VERSION ""

NS_ :

BS_:

BU_: PFAF_HS LVMPC_HS DCDC_HS AMP_HS VICM2_HS FICM_HS ARS_HS MCP_B_HS MCP_A_HS ICCM_OBD_HS SAS_HS ACCM_HS VLBS_HS EBCM_OBD_HS EDI_HS HPCC_HS VITM_OBD_HS PTAM_HS OBCM_HS VICM_HS HCP_HS FDCM_HS APPS_HS ICCM_HS EOCM_F_HS GPCM_HS FSCM_ITBC_HS SCM_HS ITBC_HS VCM_HS HMIM_HS FCP_HS VES_HS Dummy_HS MCP_C_HS RWS_HS ONSTAR_HS EPS_HS TestTool_HS MCP_HS BCP_HS ALC_HS AHL_AFL_HS SADS_HS EPB_HS FSCM_HS AFS_HS FCM_HS TCCM_HS RDCM_HS PTO_HS PCM_HS EBCM_HS ACC_HS BCM_HS TCM_HS ECM_HS

BO_ 1359 UUDT_Resp_From_RDCM_HS: 8 RDCM_HS
 SG_ DgnInf_HS54F : 7|64@0+ (1,0) [0|1.844674407371E+019] ""  FCP_HS,ONSTAR_HS,TestTool_HS

BO_ 2023 USDT_Req_to_VITM_HS: 8 TestTool_HS
 SG_ DgnInf : 7|64@0+ (1,0) [0|1.844674407371E+019] ""  VITM_OBD_HS

BO_ 2021 USDT_Req_to_OBD_Device5: 8 TestTool_HS
 SG_ DgnInf : 7|64@0+ (1,0) [0|1.844674407371E+019] ""  EBCM_OBD_HS

BO_ 2017 USDT_Req_to_BCP_HS: 8 TestTool_HS
 SG_ DgnInf : 7|64@0+ (1,0) [0|1.844674407371E+019] ""  HCP_HS,BCP_HS

BO_ 2019 USDT_Req_to_FSCM_HS: 8 TestTool_HS
 SG_ DgnInf : 7|64@0+ (1,0) [0|1.844674407371E+019] ""  ICCM_OBD_HS,FSCM_ITBC_HS,FSCM_HS

BO_ 585 USDT_Req_to_AFL_AHL_HS: 8 TestTool_HS
 SG_ DgnInf : 7|64@0+ (1,0) [0|1.844674407371E+019] ""  AHL_AFL_HS

BO_ 578 USDT_Req_to_EHPS_EPS_HS: 8 TestTool_HS
 SG_ DgnInf : 7|64@0+ (1,0) [0|1.844674407371E+019] ""  VES_HS,EPS_HS

BO_ 2022 USDT_Req_to_OBD_Device6: 8 TestTool_HS
 SG_ DgnInf : 7|64@0+ (1,0) [0|1.844674407371E+019] ""  FICM_HS,GPCM_HS,VICM2_HS

BO_ 584 USDT_Req_to_Free_48_HS: 8 TestTool_HS
 SG_ DgnInf : 7|64@0+ (1,0) [0|1.844674407371E+019] ""  Dummy_HS

BO_ 591 USDT_Req_to_RDCM_HS: 8 TestTool_HS
 SG_ DgnInf : 7|64@0+ (1,0) [0|1.844674407371E+019] ""  RDCM_HS

BO_ 581 USDT_Req_to_ALC_HS: 8 TestTool_HS
 SG_ DgnInf : 7|64@0+ (1,0) [0|1.844674407371E+019] ""  ALC_HS

BO_ 586 USDT_Req_to_SAS_HS: 8 TestTool_HS
 SG_ DgnInf : 7|64@0+ (1,0) [0|1.844674407371E+019] ""  SAS_HS

BO_ 588 USDT_Req_to_PFAF_HS: 8 TestTool_HS
 SG_ DgnInf : 7|64@0+ (1,0) [0|1.844674407371E+019] ""  PFAF_HS

BO_ 580 USDT_Req_to_OBCM_HS: 8 TestTool_HS
 SG_ DgnInf : 7|64@0+ (1,0) [0|1.844674407371E+019] ""  DCDC_HS,OBCM_HS

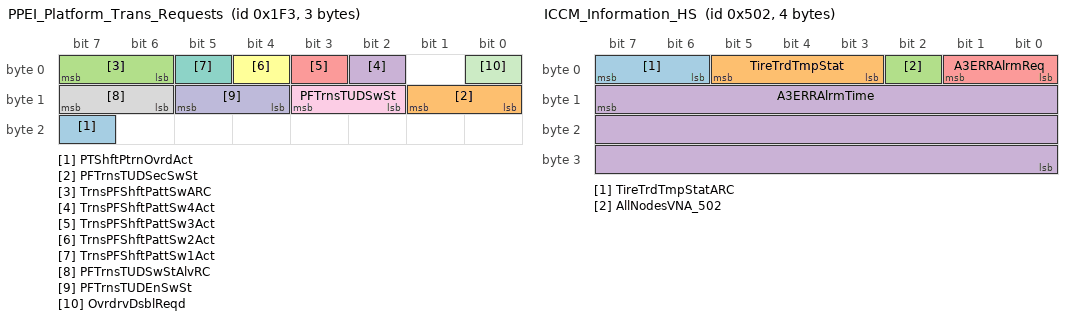
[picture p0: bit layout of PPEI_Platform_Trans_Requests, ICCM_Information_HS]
BO_ 499 PPEI_Platform_Trans_Requests: 3 BCM_HS
 SG_ PTShftPtrnOvrdAct : 23|1@0+ (1,0) [0|1] ""  TCM_HS
 SG_ PFTrnsTUDSecSwSt : 9|2@0+ (1,0) [0|3] ""  TCM_HS
 SG_ TrnsPFShftPattSwARC : 7|2@0+ (1,0) [0|3] ""  PCM_HS,ECM_HS,TCM_HS
 SG_ TrnsPFShftPattSw4Act : 2|1@0+ (1,0) [0|1] ""  PCM_HS,ECM_HS,TCM_HS
 SG_ TrnsPFShftPattSw3Act : 3|1@0+ (1,0) [0|1] ""  PCM_HS,ECM_HS,TCM_HS
 SG_ TrnsPFShftPattSw2Act : 4|1@0+ (1,0) [0|1] ""  PCM_HS,ECM_HS,TCM_HS
 SG_ TrnsPFShftPattSw1Act : 5|1@0+ (1,0) [0|1] ""  PCM_HS,ECM_HS,TCM_HS
 SG_ PFTrnsTUDSwStAlvRC : 15|2@0+ (1,0) [0|3] ""  TCM_HS
 SG_ PFTrnsTUDSwSt : 11|2@0+ (1,0) [0|3] ""  TCM_HS
 SG_ PFTrnsTUDEnSwSt : 13|2@0+ (1,0) [0|3] ""  TCM_HS
 SG_ OvrdrvDsblReqd : 0|1@0+ (1,0) [0|1] "" Vector__XXX

BO_ 1282 ICCM_Information_HS: 4 ALC_HS
 SG_ TireTrdTmpStatARC : 7|2@0+ (1,0) [0|3] ""  EBCM_OBD_HS,EBCM_HS
 SG_ TireTrdTmpStat : 5|3@0+ (1,0) [0|7] ""  BCM_HS,EBCM_OBD_HS,EBCM_HS
 SG_ AllNodesVNA_502 : 2|1@0+ (1,0) [0|1] ""  BCM_HS
 SG_ A3ERRAlrmTime : 15|24@0+ (1,0) [0|16777215] "min"  BCM_HS
 SG_ A3ERRAlrmReq : 1|2@0+ (1,0) [0|3] ""  BCM_HS

BO_ 1360 UUDT_Resp_From_PTAM_HS: 8 PTAM_HS
 SG_ DgnInf_HS550 : 7|64@0+ (1,0) [0|1.844674407371E+019] ""  FCP_HS,ONSTAR_HS,TestTool_HS

BO_ 1616 USDT_Resp_From_PTAM_HS: 8 PTAM_HS
 SG_ DgnInf : 7|64@0+ (1,0) [0|1.844674407371E+019] ""  FCP_HS,ONSTAR_HS,TestTool_HS

BO_ 1921 DTC_Triggered_781: 7 Dummy_HS
 SG_ DTCI_CurrentStatus_781 : 41|1@0+ (1,0) [0|1] ""  HMIM_HS,FCP_HS,ONSTAR_HS
 SG_ DTCI_WrnIndRqdSt_781 : 47|1@0+ (1,0) [0|1] ""  HMIM_HS,FCP_HS,ONSTAR_HS
 SG_ DTCIUnused7_781 : 1|1@0+ (1,0) [0|1] ""  HMIM_HS,FCP_HS,ONSTAR_HS
 SG_ DTCIUnused6_781 : 2|1@0+ (1,0) [0|1] ""  HMIM_HS,FCP_HS,ONSTAR_HS
 SG_ DTCIUnused5_781 : 3|1@0+ (1,0) [0|1] ""  HMIM_HS,FCP_HS,ONSTAR_HS
 SG_ DTCIUnused4_781 : 4|1@0+ (1,0) [0|1] ""  HMIM_HS,FCP_HS,ONSTAR_HS
 SG_ DTCIUnused3_781 : 5|1@0+ (1,0) [0|1] ""  HMIM_HS,FCP_HS,ONSTAR_HS
 SG_ DTCIUnused2_781 : 6|1@0+ (1,0) [0|1] ""  HMIM_HS,FCP_HS,ONSTAR_HS
 SG_ DTCIUnused1_781 : 7|1@0+ (1,0) [0|1] ""  HMIM_HS,FCP_HS,ONSTAR_HS
 SG_ DTCI_TstNPsdPwrUpSt_781 : 45|1@0+ (1,0) [0|1] ""  HMIM_HS,FCP_HS,ONSTAR_HS
 SG_ DTCI_TstNPsdCdClrdSt_781 : 42|1@0+ (1,0) [0|1] ""  HMIM_HS,FCP_HS,ONSTAR_HS
 SG_ DTCI_TstFldPwrUpSt_781 : 46|1@0+ (1,0) [0|1] ""  HMIM_HS,FCP_HS,ONSTAR_HS
 SG_ DTCI_TstFldCdClrdStat_781 : 43|1@0+ (1,0) [0|1] ""  HMIM_HS,FCP_HS,ONSTAR_HS
 SG_ DTCI_HistStat_781 : 44|1@0+ (1,0) [0|1] ""  HMIM_HS,FCP_HS,ONSTAR_HS
 SG_ DTCI_DTCTriggered_781 : 0|1@0+ (1,0) [0|1] ""  HMIM_HS,FCP_HS,ONSTAR_HS
 SG_ DTCI_DTCSource_781 : 15|8@0+ (1,0) [0|255] ""  HMIM_HS,FCP_HS,ONSTAR_HS
 SG_ DTCI_DTCNumber_781 : 23|16@0+ (1,0) [0|65535] ""  HMIM_HS,FCP_HS,ONSTAR_HS
 SG_ DTCI_DTCFaultType_781 : 55|8@0+ (1,0) [0|255] ""  HMIM_HS,FCP_HS,ONSTAR_HS
 SG_ DTCI_DTCFailType_781 : 39|8@0+ (1,0) [0|255] ""  HMIM_HS,FCP_HS,ONSTAR_HS
 SG_ DTCI_CodeSupported_781 : 40|1@0+ (1,0) [0|1] ""  HMIM_HS,FCP_HS,ONSTAR_HS

BO_ 1920 DTC_Triggered_780: 7 EBCM_HS
 SG_ DTCI_CurrentStatus_780 : 41|1@0+ (1,0) [0|1] ""  HMIM_HS,FCP_HS,ONSTAR_HS
 SG_ DTCI_WrnIndRqdSt_780 : 47|1@0+ (1,0) [0|1] ""  HMIM_HS,FCP_HS,ONSTAR_HS
 SG_ DTCIUnused7_780 : 1|1@0+ (1,0) [0|1] ""  HMIM_HS,FCP_HS,ONSTAR_HS
 SG_ DTCIUnused6_780 : 2|1@0+ (1,0) [0|1] ""  HMIM_HS,FCP_HS,ONSTAR_HS
 SG_ DTCIUnused5_780 : 3|1@0+ (1,0) [0|1] ""  HMIM_HS,FCP_HS,ONSTAR_HS
 SG_ DTCIUnused4_780 : 4|1@0+ (1,0) [0|1] ""  HMIM_HS,FCP_HS,ONSTAR_HS
 SG_ DTCIUnused3_780 : 5|1@0+ (1,0) [0|1] ""  HMIM_HS,FCP_HS,ONSTAR_HS
 SG_ DTCIUnused2_780 : 6|1@0+ (1,0) [0|1] ""  HMIM_HS,FCP_HS,ONSTAR_HS
 SG_ DTCIUnused1_780 : 7|1@0+ (1,0) [0|1] ""  HMIM_HS,FCP_HS,ONSTAR_HS
 SG_ DTCI_TstNPsdPwrUpSt_780 : 45|1@0+ (1,0) [0|1] ""  HMIM_HS,FCP_HS,ONSTAR_HS
 SG_ DTCI_TstNPsdCdClrdSt_780 : 42|1@0+ (1,0) [0|1] ""  HMIM_HS,FCP_HS,ONSTAR_HS
 SG_ DTCI_TstFldPwrUpSt_780 : 46|1@0+ (1,0) [0|1] ""  HMIM_HS,FCP_HS,ONSTAR_HS
 SG_ DTCI_TstFldCdClrdStat_780 : 43|1@0+ (1,0) [0|1] ""  HMIM_HS,FCP_HS,ONSTAR_HS
 SG_ DTCI_HistStat_780 : 44|1@0+ (1,0) [0|1] ""  HMIM_HS,FCP_HS,ONSTAR_HS
 SG_ DTCI_DTCTriggered_780 : 0|1@0+ (1,0) [0|1] ""  HMIM_HS,FCP_HS,ONSTAR_HS
 SG_ DTCI_DTCSource_780 : 15|8@0+ (1,0) [0|255] ""  HMIM_HS,FCP_HS,ONSTAR_HS
 SG_ DTCI_DTCNumber_780 : 23|16@0+ (1,0) [0|65535] ""  HMIM_HS,FCP_HS,ONSTAR_HS
 SG_ DTCI_DTCFaultType_780 : 55|8@0+ (1,0) [0|255] ""  HMIM_HS,FCP_HS,ONSTAR_HS
 SG_ DTCI_DTCFailType_780 : 39|8@0+ (1,0) [0|255] ""  HMIM_HS,FCP_HS,ONSTAR_HS
 SG_ DTCI_CodeSupported_780 : 40|1@0+ (1,0) [0|1] ""  HMIM_HS,FCP_HS,ONSTAR_HS

BO_ 596 USDT_Req_to_EPB_HS: 8 TestTool_HS
 SG_ DgnInf : 7|64@0+ (1,0) [0|1.844674407371E+019] ""  EPB_HS

BO_ 2033 PCU_Req_to_SDM_HS: 8 TestTool_HS
 SG_ PCUInfo : 7|64@0+ (1,0) [0|1.844674407371E+019] ""  BCM_HS

BO_ 495 PPEI_Fuel_System_Request_2: 4 ECM_HS
 SG_ MassAirFloV : 7|1@0+ (1,0) [0|1] ""  VICM_HS
 SG_ MassAirFlo : 23|16@0+ (0.01,0) [0|655.35] "grams/s"  VICM_HS

BO_ 1350 UUDT_Resp_From_APPS_HS: 8 APPS_HS
 SG_ DgnInf_HS546 : 7|64@0+ (1,0) [0|1.844674407371E+019] ""  FCP_HS,ONSTAR_HS,TestTool_HS

BO_ 1914 DTC_Triggered_77A: 7 RDCM_HS
 SG_ DTCI_DTCFaultType_77A : 55|8@0+ (1,0) [0|255] ""  HMIM_HS,FCP_HS,ONSTAR_HS
 SG_ DTCI_CodeSupported_77A : 40|1@0+ (1,0) [0|1] ""  HMIM_HS,FCP_HS,ONSTAR_HS
 SG_ DTCI_CurrentStatus_77A : 41|1@0+ (1,0) [0|1] ""  HMIM_HS,FCP_HS,ONSTAR_HS
 SG_ DTCI_TstNPsdCdClrdSt_77A : 42|1@0+ (1,0) [0|1] ""  HMIM_HS,FCP_HS,ONSTAR_HS
 SG_ DTCI_TstFldCdClrdStat_77A : 43|1@0+ (1,0) [0|1] ""  HMIM_HS,FCP_HS,ONSTAR_HS
 SG_ DTCI_HistStat_77A : 44|1@0+ (1,0) [0|1] ""  HMIM_HS,FCP_HS,ONSTAR_HS
 SG_ DTCI_TstNPsdPwrUpSt_77A : 45|1@0+ (1,0) [0|1] ""  HMIM_HS,FCP_HS,ONSTAR_HS
 SG_ DTCI_TstFldPwrUpSt_77A : 46|1@0+ (1,0) [0|1] ""  HMIM_HS,FCP_HS,ONSTAR_HS
 SG_ DTCI_WrnIndRqdSt_77A : 47|1@0+ (1,0) [0|1] ""  HMIM_HS,FCP_HS,ONSTAR_HS
 SG_ DTCI_DTCFailType_77A : 39|8@0+ (1,0) [0|255] ""  HMIM_HS,FCP_HS,ONSTAR_HS
 SG_ DTCI_DTCNumber_77A : 23|16@0+ (1,0) [0|65535] ""  HMIM_HS,FCP_HS,ONSTAR_HS
 SG_ DTCI_DTCSource_77A : 15|8@0+ (1,0) [0|255] ""  HMIM_HS,FCP_HS,ONSTAR_HS
 SG_ DTCI_DTCTriggered_77A : 0|1@0+ (1,0) [0|1] ""  HMIM_HS,FCP_HS,ONSTAR_HS
 SG_ DTCIUnused7_77A : 1|1@0+ (1,0) [0|1] ""  HMIM_HS,FCP_HS,ONSTAR_HS
 SG_ DTCIUnused6_77A : 2|1@0+ (1,0) [0|1] ""  HMIM_HS,FCP_HS,ONSTAR_HS
 SG_ DTCIUnused5_77A : 3|1@0+ (1,0) [0|1] ""  HMIM_HS,FCP_HS,ONSTAR_HS
 SG_ DTCIUnused4_77A : 4|1@0+ (1,0) [0|1] ""  HMIM_HS,FCP_HS,ONSTAR_HS
 SG_ DTCIUnused3_77A : 5|1@0+ (1,0) [0|1] ""  HMIM_HS,FCP_HS,ONSTAR_HS
 SG_ DTCIUnused2_77A : 6|1@0+ (1,0) [0|1] ""  HMIM_HS,FCP_HS,ONSTAR_HS
 SG_ DTCIUnused1_77A : 7|1@0+ (1,0) [0|1] ""  HMIM_HS,FCP_HS,ONSTAR_HS

BO_ 1911 DTC_Triggered_777: 7 PTO_HS
 SG_ DTCI_DTCFaultType_777 : 55|8@0+ (1,0) [0|255] ""  HMIM_HS,FCP_HS,ONSTAR_HS
 SG_ DTCI_CodeSupported_777 : 40|1@0+ (1,0) [0|1] ""  HMIM_HS,FCP_HS,ONSTAR_HS
 SG_ DTCI_CurrentStatus_777 : 41|1@0+ (1,0) [0|1] ""  HMIM_HS,FCP_HS,ONSTAR_HS
 SG_ DTCI_TstNPsdCdClrdSt_777 : 42|1@0+ (1,0) [0|1] ""  HMIM_HS,FCP_HS,ONSTAR_HS
 SG_ DTCI_TstFldCdClrdStat_777 : 43|1@0+ (1,0) [0|1] ""  HMIM_HS,FCP_HS,ONSTAR_HS
 SG_ DTCI_HistStat_777 : 44|1@0+ (1,0) [0|1] ""  HMIM_HS,FCP_HS,ONSTAR_HS
 SG_ DTCI_TstNPsdPwrUpSt_777 : 45|1@0+ (1,0) [0|1] ""  HMIM_HS,FCP_HS,ONSTAR_HS
 SG_ DTCI_TstFldPwrUpSt_777 : 46|1@0+ (1,0) [0|1] ""  HMIM_HS,FCP_HS,ONSTAR_HS
 SG_ DTCI_WrnIndRqdSt_777 : 47|1@0+ (1,0) [0|1] ""  HMIM_HS,FCP_HS,ONSTAR_HS
 SG_ DTCI_DTCFailType_777 : 39|8@0+ (1,0) [0|255] ""  HMIM_HS,FCP_HS,ONSTAR_HS
 SG_ DTCI_DTCNumber_777 : 23|16@0+ (1,0) [0|65535] ""  HMIM_HS,FCP_HS,ONSTAR_HS
 SG_ DTCI_DTCSource_777 : 15|8@0+ (1,0) [0|255] ""  HMIM_HS,FCP_HS,ONSTAR_HS
 SG_ DTCI_DTCTriggered_777 : 0|1@0+ (1,0) [0|1] ""  HMIM_HS,FCP_HS,ONSTAR_HS
 SG_ DTCIUnused7_777 : 1|1@0+ (1,0) [0|1] ""  HMIM_HS,FCP_HS,ONSTAR_HS
 SG_ DTCIUnused6_777 : 2|1@0+ (1,0) [0|1] ""  HMIM_HS,FCP_HS,ONSTAR_HS
 SG_ DTCIUnused5_777 : 3|1@0+ (1,0) [0|1] ""  HMIM_HS,FCP_HS,ONSTAR_HS
 SG_ DTCIUnused4_777 : 4|1@0+ (1,0) [0|1] ""  HMIM_HS,FCP_HS,ONSTAR_HS
 SG_ DTCIUnused3_777 : 5|1@0+ (1,0) [0|1] ""  HMIM_HS,FCP_HS,ONSTAR_HS
 SG_ DTCIUnused2_777 : 6|1@0+ (1,0) [0|1] ""  HMIM_HS,FCP_HS,ONSTAR_HS
 SG_ DTCIUnused1_777 : 7|1@0+ (1,0) [0|1] ""  HMIM_HS,FCP_HS,ONSTAR_HS

BO_ 583 USDT_Req_to_PTO_HS: 8 TestTool_HS
 SG_ DgnInf : 7|64@0+ (1,0) [0|1.844674407371E+019] ""  PTO_HS

BO_ 1351 UUDT_Resp_From_PTO: 8 PTO_HS
 SG_ DgnInf_HS547 : 7|64@0+ (1,0) [0|1.844674407371E+019] ""  FCP_HS,ONSTAR_HS,TestTool_HS

BO_ 1607 USDT_Resp_From_PTO_HS: 8 PTO_HS
 SG_ DgnInf : 7|64@0+ (1,0) [0|1.844674407371E+019] ""  FCP_HS,ONSTAR_HS,TestTool_HS

BO_ 1906 DTC_Triggered_772: 7 ECM_HS
 SG_ DTCI_DTCFaultType_772 : 55|8@0+ (1,0) [0|255] ""  HMIM_HS,FCP_HS,ONSTAR_HS
 SG_ DTCI_CodeSupported_772 : 40|1@0+ (1,0) [0|1] ""  HMIM_HS,FCP_HS,ONSTAR_HS
 SG_ DTCI_CurrentStatus_772 : 41|1@0+ (1,0) [0|1] ""  HMIM_HS,FCP_HS,ONSTAR_HS
 SG_ DTCI_TstNPsdCdClrdSt_772 : 42|1@0+ (1,0) [0|1] ""  HMIM_HS,FCP_HS,ONSTAR_HS
 SG_ DTCI_TstFldCdClrdStat_772 : 43|1@0+ (1,0) [0|1] ""  HMIM_HS,FCP_HS,ONSTAR_HS
 SG_ DTCI_HistStat_772 : 44|1@0+ (1,0) [0|1] ""  HMIM_HS,FCP_HS,ONSTAR_HS
 SG_ DTCI_TstNPsdPwrUpSt_772 : 45|1@0+ (1,0) [0|1] ""  HMIM_HS,FCP_HS,ONSTAR_HS
 SG_ DTCI_TstFldPwrUpSt_772 : 46|1@0+ (1,0) [0|1] ""  HMIM_HS,FCP_HS,ONSTAR_HS
 SG_ DTCI_WrnIndRqdSt_772 : 47|1@0+ (1,0) [0|1] ""  HMIM_HS,FCP_HS,ONSTAR_HS
 SG_ DTCI_DTCFailType_772 : 39|8@0+ (1,0) [0|255] ""  HMIM_HS,FCP_HS,ONSTAR_HS
 SG_ DTCI_DTCNumber_772 : 23|16@0+ (1,0) [0|65535] ""  HMIM_HS,FCP_HS,ONSTAR_HS
 SG_ DTCI_DTCSource_772 : 15|8@0+ (1,0) [0|255] ""  HMIM_HS,FCP_HS,ONSTAR_HS
 SG_ DTCI_DTCTriggered_772 : 0|1@0+ (1,0) [0|1] ""  HMIM_HS,FCP_HS,ONSTAR_HS
 SG_ DTCIUnused7_772 : 1|1@0+ (1,0) [0|1] ""  HMIM_HS,FCP_HS,ONSTAR_HS
 SG_ DTCIUnused6_772 : 2|1@0+ (1,0) [0|1] ""  HMIM_HS,FCP_HS,ONSTAR_HS
 SG_ DTCIUnused5_772 : 3|1@0+ (1,0) [0|1] ""  HMIM_HS,FCP_HS,ONSTAR_HS
 SG_ DTCIUnused4_772 : 4|1@0+ (1,0) [0|1] ""  HMIM_HS,FCP_HS,ONSTAR_HS
 SG_ DTCIUnused3_772 : 5|1@0+ (1,0) [0|1] ""  HMIM_HS,FCP_HS,ONSTAR_HS
 SG_ DTCIUnused2_772 : 6|1@0+ (1,0) [0|1] ""  HMIM_HS,FCP_HS,ONSTAR_HS
 SG_ DTCIUnused1_772 : 7|1@0+ (1,0) [0|1] ""  HMIM_HS,FCP_HS,ONSTAR_HS

BO_ 1907 DTC_Triggered_773: 7 EBCM_HS
 SG_ DTCI_DTCFaultType_773 : 55|8@0+ (1,0) [0|255] ""  HMIM_HS,FCP_HS,ONSTAR_HS
 SG_ DTCI_CodeSupported_773 : 40|1@0+ (1,0) [0|1] ""  HMIM_HS,FCP_HS,ONSTAR_HS
 SG_ DTCI_CurrentStatus_773 : 41|1@0+ (1,0) [0|1] ""  HMIM_HS,FCP_HS,ONSTAR_HS
 SG_ DTCI_TstNPsdCdClrdSt_773 : 42|1@0+ (1,0) [0|1] ""  HMIM_HS,FCP_HS,ONSTAR_HS
 SG_ DTCI_TstFldCdClrdStat_773 : 43|1@0+ (1,0) [0|1] ""  HMIM_HS,FCP_HS,ONSTAR_HS
 SG_ DTCI_HistStat_773 : 44|1@0+ (1,0) [0|1] ""  HMIM_HS,FCP_HS,ONSTAR_HS
 SG_ DTCI_TstNPsdPwrUpSt_773 : 45|1@0+ (1,0) [0|1] ""  HMIM_HS,FCP_HS,ONSTAR_HS
 SG_ DTCI_TstFldPwrUpSt_773 : 46|1@0+ (1,0) [0|1] ""  HMIM_HS,FCP_HS,ONSTAR_HS
 SG_ DTCI_WrnIndRqdSt_773 : 47|1@0+ (1,0) [0|1] ""  HMIM_HS,FCP_HS,ONSTAR_HS
 SG_ DTCI_DTCFailType_773 : 39|8@0+ (1,0) [0|255] ""  HMIM_HS,FCP_HS,ONSTAR_HS
 SG_ DTCI_DTCNumber_773 : 23|16@0+ (1,0) [0|65535] ""  HMIM_HS,FCP_HS,ONSTAR_HS
 SG_ DTCI_DTCSource_773 : 15|8@0+ (1,0) [0|255] ""  HMIM_HS,FCP_HS,ONSTAR_HS
 SG_ DTCI_DTCTriggered_773 : 0|1@0+ (1,0) [0|1] ""  HMIM_HS,FCP_HS,ONSTAR_HS
 SG_ DTCIUnused7_773 : 1|1@0+ (1,0) [0|1] ""  HMIM_HS,FCP_HS,ONSTAR_HS
 SG_ DTCIUnused6_773 : 2|1@0+ (1,0) [0|1] ""  HMIM_HS,FCP_HS,ONSTAR_HS
 SG_ DTCIUnused5_773 : 3|1@0+ (1,0) [0|1] ""  HMIM_HS,FCP_HS,ONSTAR_HS
 SG_ DTCIUnused4_773 : 4|1@0+ (1,0) [0|1] ""  HMIM_HS,FCP_HS,ONSTAR_HS
 SG_ DTCIUnused3_773 : 5|1@0+ (1,0) [0|1] ""  HMIM_HS,FCP_HS,ONSTAR_HS
 SG_ DTCIUnused2_773 : 6|1@0+ (1,0) [0|1] ""  HMIM_HS,FCP_HS,ONSTAR_HS
 SG_ DTCIUnused1_773 : 7|1@0+ (1,0) [0|1] ""  HMIM_HS,FCP_HS,ONSTAR_HS

BO_ 579 USDT_Req_to_EBCM_HPCC_HS: 8 TestTool_HS
 SG_ DgnInf : 7|64@0+ (1,0) [0|1.844674407371E+019] ""  HPCC_HS,EBCM_HS

BO_ 1603 USDT_Resp_From_EBCM_HPCC_HS: 8 EBCM_HS
 SG_ DgnInf : 7|64@0+ (1,0) [0|1.844674407371E+019] ""  FCP_HS,ONSTAR_HS,TestTool_HS

BO_ 1347 UUDT_Resp_From_EBCM_HPCC_HS: 8 EBCM_HS
 SG_ DgnInf_HS543 : 7|64@0+ (1,0) [0|1.844674407371E+019] ""  FCP_HS,ONSTAR_HS,TestTool_HS

BO_ 1915 DTC_Triggered_77B: 7 ACC_HS
 SG_ DTCI_DTCFaultType_77B : 55|8@0+ (1,0) [0|255] ""  HMIM_HS,FCP_HS,ONSTAR_HS
 SG_ DTCI_CodeSupported_77B : 40|1@0+ (1,0) [0|1] ""  HMIM_HS,FCP_HS,ONSTAR_HS
 SG_ DTCI_CurrentStatus_77B : 41|1@0+ (1,0) [0|1] ""  HMIM_HS,FCP_HS,ONSTAR_HS
 SG_ DTCI_TstNPsdCdClrdSt_77B : 42|1@0+ (1,0) [0|1] ""  HMIM_HS,FCP_HS,ONSTAR_HS
 SG_ DTCI_TstFldCdClrdStat_77B : 43|1@0+ (1,0) [0|1] ""  HMIM_HS,FCP_HS,ONSTAR_HS
 SG_ DTCI_HistStat_77B : 44|1@0+ (1,0) [0|1] ""  HMIM_HS,FCP_HS,ONSTAR_HS
 SG_ DTCI_TstNPsdPwrUpSt_77B : 45|1@0+ (1,0) [0|1] ""  HMIM_HS,FCP_HS,ONSTAR_HS
 SG_ DTCI_TstFldPwrUpSt_77B : 46|1@0+ (1,0) [0|1] ""  HMIM_HS,FCP_HS,ONSTAR_HS
 SG_ DTCI_WrnIndRqdSt_77B : 47|1@0+ (1,0) [0|1] ""  HMIM_HS,FCP_HS,ONSTAR_HS
 SG_ DTCI_DTCFailType_77B : 39|8@0+ (1,0) [0|255] ""  HMIM_HS,FCP_HS,ONSTAR_HS
 SG_ DTCI_DTCNumber_77B : 23|16@0+ (1,0) [0|65535] ""  HMIM_HS,FCP_HS,ONSTAR_HS
 SG_ DTCI_DTCSource_77B : 15|8@0+ (1,0) [0|255] ""  HMIM_HS,FCP_HS,ONSTAR_HS
 SG_ DTCI_DTCTriggered_77B : 0|1@0+ (1,0) [0|1] ""  HMIM_HS,FCP_HS,ONSTAR_HS
 SG_ DTCIUnused7_77B : 1|1@0+ (1,0) [0|1] ""  HMIM_HS,FCP_HS,ONSTAR_HS
 SG_ DTCIUnused6_77B : 2|1@0+ (1,0) [0|1] ""  HMIM_HS,FCP_HS,ONSTAR_HS
 SG_ DTCIUnused5_77B : 3|1@0+ (1,0) [0|1] ""  HMIM_HS,FCP_HS,ONSTAR_HS
 SG_ DTCIUnused4_77B : 4|1@0+ (1,0) [0|1] ""  HMIM_HS,FCP_HS,ONSTAR_HS
 SG_ DTCIUnused3_77B : 5|1@0+ (1,0) [0|1] ""  HMIM_HS,FCP_HS,ONSTAR_HS
 SG_ DTCIUnused2_77B : 6|1@0+ (1,0) [0|1] ""  HMIM_HS,FCP_HS,ONSTAR_HS
 SG_ DTCIUnused1_77B : 7|1@0+ (1,0) [0|1] ""  HMIM_HS,FCP_HS,ONSTAR_HS

BO_ 587 USDT_Req_to_EOCM_FCM_HS: 8 TestTool_HS
 SG_ DgnInf : 7|64@0+ (1,0) [0|1.844674407371E+019] ""  EOCM_F_HS,FCM_HS

BO_ 1611 USDT_Resp_From_EOCM_FCM_HS: 8 FCM_HS
 SG_ DgnInf : 7|64@0+ (1,0) [0|1.844674407371E+019] ""  FCP_HS,ONSTAR_HS,TestTool_HS

BO_ 1355 UUDT_Resp_From_EOCM_FCM_HS: 8 FCM_HS
 SG_ DgnInf_HS54B : 7|64@0+ (1,0) [0|1.844674407371E+019] ""  FCP_HS,ONSTAR_HS,TestTool_HS

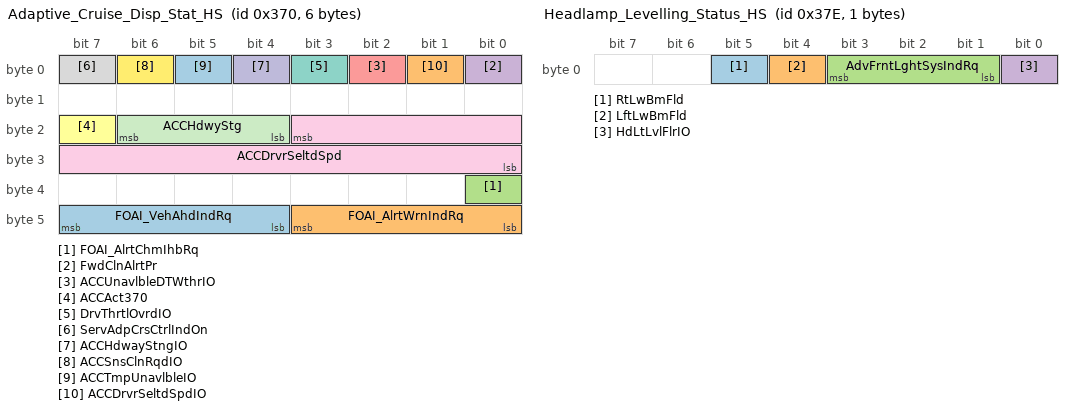
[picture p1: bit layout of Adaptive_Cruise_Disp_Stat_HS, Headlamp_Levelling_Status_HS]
BO_ 880 Adaptive_Cruise_Disp_Stat_HS: 6 ACC_HS
 SG_ FOAI_VehAhdIndRq : 47|4@0+ (1,0) [0|15] ""  BCM_HS
 SG_ FOAI_AlrtWrnIndRq : 43|4@0+ (1,0) [0|15] ""  BCM_HS
 SG_ FOAI_AlrtChmIhbRq : 32|1@0+ (1,0) [0|1] ""  BCM_HS
 SG_ FwdClnAlrtPr : 0|1@0+ (1,0) [0|1] ""  BCM_HS
 SG_ ACCUnavlbleDTWthrIO : 2|1@0+ (1,0) [0|1] ""  BCM_HS
 SG_ ACCAct370 : 23|1@0+ (1,0) [0|1] ""  EBCM_OBD_HS,EBCM_HS,TCM_HS,BCM_HS
 SG_ DrvThrtlOvrdIO : 3|1@0+ (1,0) [0|1] ""  BCM_HS
 SG_ ServAdpCrsCtrlIndOn : 7|1@0+ (1,0) [0|1] ""  BCM_HS
 SG_ ACCDrvrSeltdSpd : 19|12@0+ (0.0625,0) [0|255.9375] "km / h"  ECM_HS,BCM_HS
 SG_ ACCHdwayStngIO : 4|1@0+ (1,0) [0|1] ""  BCM_HS
 SG_ ACCHdwyStg : 22|3@0+ (1,0) [0|7] ""  BCM_HS
 SG_ ACCSnsClnRqdIO : 6|1@0+ (1,0) [0|1] ""  BCM_HS
 SG_ ACCTmpUnavlbleIO : 5|1@0+ (1,0) [0|1] ""  BCM_HS
 SG_ ACCDrvrSeltdSpdIO : 1|1@0+ (1,0) [0|1] ""  BCM_HS

BO_ 894 Headlamp_Levelling_Status_HS: 1 AHL_AFL_HS
 SG_ RtLwBmFld : 5|1@0+ (1,0) [0|1] ""  EOCM_F_HS,BCM_HS
 SG_ LftLwBmFld : 4|1@0+ (1,0) [0|1] ""  EOCM_F_HS,BCM_HS
 SG_ AdvFrntLghtSysIndRq : 3|3@0+ (1,0) [0|7] ""  BCM_HS
 SG_ HdLtLvlFlrIO : 0|1@0+ (1,0) [0|1] ""  BCM_HS

BO_ 577 USDT_Req_to_BCM_HS: 8 TestTool_HS
 SG_ DgnInf : 7|64@0+ (1,0) [0|1.844674407371E+019] ""  BCM_HS

BO_ 298 Body_Information_HS: 8 BCM_HS
 SG_ SpdLmtrSttngTyp : 59|2@0+ (1,0) [0|3] ""  ECM_HS
 SG_ TCSysDisSwAtv : 62|1@0+ (1,0) [0|1] ""  ECM_HS
 SG_ AutoMdSpdLmtCnfrmd : 57|1@0+ (1,0) [0|1] ""  ECM_HS
 SG_ TCSysDisSwAtvARC : 61|2@0+ (1,0) [0|3] ""  ECM_HS,EBCM_OBD_HS,EBCM_HS
 SG_ ChmAct : 55|1@0+ (1,0) [0|1] ""  ACC_HS
 SG_ DDAjrSwAtvM : 63|1@0+ (1,0) [0|1] ""  EBCM_OBD_HS,EBCM_HS,ECM_HS,ACC_HS
 SG_ CrshAlrtDrvrSlctdType : 5|1@0+ (1,0) [0|1] ""  EBCM_OBD_HS,EBCM_HS,ACC_HS
 SG_ PsSbltAtcV : 54|1@0+ (1,0) [0|1] ""  EBCM_OBD_HS,EBCM_HS
 SG_ PsSbltAtc : 53|1@0+ (1,0) [0|1] ""  EBCM_OBD_HS,EBCM_HS
 SG_ TrlrBrkDsplyAct : 51|1@0+ (1,0) [0|1] ""  FSCM_ITBC_HS
 SG_ RdSpdCatType : 45|2@0+ (1,0) [0|3] ""  FCM_HS,AHL_AFL_HS
 SG_ LnCat : 47|2@0+ (1,0) [0|3] ""  FCM_HS,AHL_AFL_HS
 SG_ FncRdClass : 50|3@0+ (1,0) [0|7] ""  FCM_HS,AHL_AFL_HS
 SG_ SprtLnRd : 43|1@0+ (1,0) [0|1] ""  FCM_HS,AHL_AFL_HS
 SG_ CntrldAccRd : 39|1@0+ (1,0) [0|1] ""  FCM_HS,AHL_AFL_HS
 SG_ BldUpArDet : 11|1@0+ (1,0) [0|1] ""  FCM_HS,AHL_AFL_HS
 SG_ MpDataAvlbl : 3|1@0+ (1,0) [0|1] ""  FCM_HS,AHL_AFL_HS
 SG_ SusCustStngReq : 42|3@0+ (1,0) [0|7] ""  EBCM_OBD_HS,EBCM_HS
 SG_ StrCustStngReq : 38|3@0+ (1,0) [0|7] ""  EBCM_OBD_HS,EBCM_HS
 SG_ RstrCustFctrDef : 35|1@0+ (1,0) [0|1] ""  AHL_AFL_HS,EBCM_OBD_HS,EBCM_HS
 SG_ DrvlnCustStngReq : 34|3@0+ (1,0) [0|7] ""  EBCM_OBD_HS,EBCM_HS
 SG_ ChmMstrVDA : 22|1@0+ (1,0) [0|1] ""  EOCM_F_HS,ACC_HS
 SG_ IPCVDA : 21|1@0+ (1,0) [0|1] ""  EOCM_F_HS,ACC_HS,EBCM_OBD_HS,EBCM_HS
 SG_ HeadUpDispVDA : 20|1@0+ (1,0) [0|1] ""  EOCM_F_HS,ACC_HS
 SG_ HapticSeatVDA : 52|1@0+ (1,0) [0|1] ""  ACC_HS
 SG_ RRDoorAjarSwAct : 23|1@0+ (1,0) [0|1] ""  ICCM_OBD_HS,ICCM_HS,ALC_HS,EPB_HS,SADS_HS
 SG_ PDAjrSwAtv : 10|1@0+ (1,0) [0|1] ""  EPB_HS,ICCM_OBD_HS,ICCM_HS,ALC_HS,SADS_HS
 SG_ DDAjrSwAtv : 9|1@0+ (1,0) [0|1] ""  ECM_HS,EBCM_OBD_HS,EBCM_HS,ACC_HS,EPB_HS,ICCM_OBD_HS,ICCM_HS,ALC_HS,SADS_HS
 SG_ TrlrHWIntrfcVDA : 4|1@0+ (1,0) [0|1] ""  EBCM_OBD_HS,EBCM_HS,RDCM_HS
 SG_ DrId : 15|3@0+ (1,0) [0|7] ""  ACC_HS
 SG_ EnrgMgtLdShdRq : 19|4@0+ (1,0) [0|15] ""  PTO_HS,ARS_HS,ICCM_OBD_HS,ICCM_HS,ALC_HS,SADS_HS
 SG_ DrSbltAtcV : 2|1@0+ (1,0) [0|1] ""  ECM_HS,ACC_HS,EPB_HS,EBCM_OBD_HS,EBCM_HS
 SG_ TrlrHtchSwAtv : 0|1@0+ (1,0) [0|1] ""  EBCM_OBD_HS,EBCM_HS,RDCM_HS
 SG_ TreInfMonSysRstReq : 7|1@0+ (1,0) [0|1] ""  EBCM_OBD_HS,EBCM_HS
 SG_ HUDActv : 6|1@0+ (1,0) [0|1] ""  ACC_HS
 SG_ BatVltV : 1|1@0+ (1,0) [0|1] ""  LVMPC_HS,EDI_HS,TCM_HS,HCP_HS,BCP_HS,MCP_C_HS,MCP_B_HS,MCP_A_HS,ECM_HS,EPB_HS,ICCM_OBD_HS,ICCM_HS,ALC_HS,SADS_HS
 SG_ BatVlt : 31|8@0+ (0.1,3) [3|28.5] "volts"  LVMPC_HS,EDI_HS,TCM_HS,HCP_HS,BCP_HS,MCP_C_HS,MCP_B_HS,MCP_A_HS,ECM_HS,EPB_HS,ICCM_OBD_HS,ICCM_HS,ALC_HS,SADS_HS
 SG_ RLDoorAjarSwAct : 8|1@0+ (1,0) [0|1] ""  ICCM_OBD_HS,ICCM_HS,ALC_HS,EPB_HS,SADS_HS
 SG_ DrSbltAtc : 12|1@0+ (1,0) [0|1] ""  ECM_HS,ACC_HS,EPB_HS,EBCM_OBD_HS,EBCM_HS

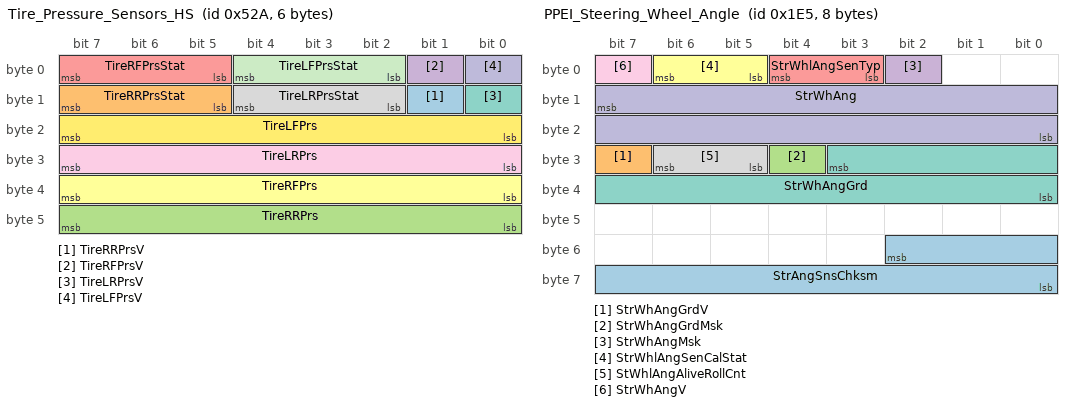
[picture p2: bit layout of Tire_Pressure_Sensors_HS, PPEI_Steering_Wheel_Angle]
BO_ 1322 Tire_Pressure_Sensors_HS: 6 BCM_HS
 SG_ TireRRPrsV : 9|1@0+ (1,0) [0|1] ""  LVMPC_HS,EDI_HS,ICCM_OBD_HS,ICCM_HS,RDCM_HS,EBCM_OBD_HS,EBCM_HS
 SG_ TireRRPrsStat : 15|3@0+ (1,0) [0|7] ""  LVMPC_HS,EDI_HS,ICCM_OBD_HS,ICCM_HS,RDCM_HS,EBCM_OBD_HS,EBCM_HS
 SG_ TireRRPrs : 47|8@0+ (4,0) [0|1020] "kPaG"  LVMPC_HS,EDI_HS,ICCM_OBD_HS,ICCM_HS,RDCM_HS,EBCM_OBD_HS,EBCM_HS
 SG_ TireRFPrsV : 1|1@0+ (1,0) [0|1] ""  LVMPC_HS,EDI_HS,ICCM_OBD_HS,ICCM_HS,RDCM_HS,EBCM_OBD_HS,EBCM_HS
 SG_ TireRFPrsStat : 7|3@0+ (1,0) [0|7] ""  LVMPC_HS,EDI_HS,ICCM_OBD_HS,ICCM_HS,RDCM_HS,EBCM_OBD_HS,EBCM_HS
 SG_ TireRFPrs : 39|8@0+ (4,0) [0|1020] "kPaG"  LVMPC_HS,EDI_HS,ICCM_OBD_HS,ICCM_HS,RDCM_HS,EBCM_OBD_HS,EBCM_HS
 SG_ TireLRPrsV : 8|1@0+ (1,0) [0|1] ""  LVMPC_HS,EDI_HS,ICCM_OBD_HS,ICCM_HS,RDCM_HS,EBCM_OBD_HS,EBCM_HS
 SG_ TireLRPrsStat : 12|3@0+ (1,0) [0|7] ""  LVMPC_HS,EDI_HS,ICCM_OBD_HS,ICCM_HS,RDCM_HS,EBCM_OBD_HS,EBCM_HS
 SG_ TireLRPrs : 31|8@0+ (4,0) [0|1020] "kPaG"  LVMPC_HS,EDI_HS,ICCM_OBD_HS,ICCM_HS,RDCM_HS,EBCM_OBD_HS,EBCM_HS
 SG_ TireLFPrsV : 0|1@0+ (1,0) [0|1] ""  LVMPC_HS,EDI_HS,ICCM_OBD_HS,ICCM_HS,RDCM_HS,EBCM_OBD_HS,EBCM_HS
 SG_ TireLFPrsStat : 4|3@0+ (1,0) [0|7] ""  LVMPC_HS,EDI_HS,ICCM_OBD_HS,ICCM_HS,RDCM_HS,EBCM_OBD_HS,EBCM_HS
 SG_ TireLFPrs : 23|8@0+ (4,0) [0|1020] "kPaG"  LVMPC_HS,EDI_HS,ICCM_OBD_HS,ICCM_HS,RDCM_HS,EBCM_OBD_HS,EBCM_HS

BO_ 1601 USDT_Resp_From_BCM_HS: 8 BCM_HS
 SG_ DgnInf : 7|64@0+ (1,0) [0|1.844674407371E+019] ""  FCP_HS,ONSTAR_HS,TestTool_HS

BO_ 2018 USDT_Req_to_TCM_MTA_MTIO_HS: 8 TestTool_HS
 SG_ DgnInf : 7|64@0+ (1,0) [0|1.844674407371E+019] ""  TCM_HS

BO_ 2026 USDT_Resp_From_TCM_MTA_MTIO_HS: 8 TCM_HS
 SG_ DgnInf : 7|64@0+ (1,0) [0|1.844674407371E+019] ""  FCP_HS,ONSTAR_HS,TestTool_HS

BO_ 1514 UUDT_Resp_From_TCM_MTA_MTIO_HS: 8 TCM_HS
 SG_ DgnInf : 7|64@0+ (1,0) [0|1.844674407371E+019] ""  FCP_HS,ONSTAR_HS,TestTool_HS

BO_ 1300 VIN_Digits_2_to_9_HS: 8 BCM_HS
 SG_ VehIdNmDig2_9 : 7|64@0+ (1,0) [0|1] ""  EBCM_OBD_HS,EBCM_HS,VES_HS,EPS_HS,VLBS_HS,ACC_HS,TCCM_HS,EPB_HS,AFS_HS,RDCM_HS

BO_ 288 Vehicle_Odometer_HS: 5 BCM_HS
 SG_ VehOdo : 7|32@0+ (0.015625,0) [0|67108863.984375] "km"  LVMPC_HS,TCCM_HS,ACC_HS,AFS_HS
 SG_ VehOdoV : 32|1@0+ (1,0) [0|1] ""  LVMPC_HS,TCCM_HS,ACC_HS,AFS_HS

BO_ 2020 USDT_Req_to_VICM_HS: 8 TestTool_HS
 SG_ DgnInf : 7|64@0+ (1,0) [0|1.844674407371E+019] ""  VICM_HS

BO_ 2028 USDT_Resp_From_VICM_HS: 8 VICM_HS
 SG_ DgnInf : 7|64@0+ (1,0) [0|1.844674407371E+019] ""  FCP_HS,ONSTAR_HS,TestTool_HS

BO_ 1516 UUDT_Resp_From_VICM_HS: 8 VICM_HS
 SG_ DgnInf : 7|64@0+ (1,0) [0|1.844674407371E+019] ""  FCP_HS,ONSTAR_HS,TestTool_HS

BO_ 485 PPEI_Steering_Wheel_Angle: 8 EBCM_HS
 SG_ StrAngSnsChksm : 50|11@0+ (1,0) [0|2047] ""  FCM_HS,HMIM_HS,VES_HS,EPS_HS,EBCM_OBD_HS,EBCM_HS,EPB_HS
 SG_ StrWhAngGrdV : 31|1@0+ (1,0) [0|1] ""  FCM_HS,HMIM_HS,ACC_HS,FCP_HS,ONSTAR_HS,ICCM_OBD_HS,ICCM_HS,ALC_HS,SADS_HS,ECM_HS,VES_HS,EPS_HS,EPB_HS,RDCM_HS,TCCM_HS,EBCM_OBD_HS,EBCM_HS
 SG_ StrWhAngGrdMsk : 28|1@0+ (1,0) [0|1] ""  FCM_HS,VES_HS,EPS_HS,HMIM_HS,EPB_HS,EBCM_OBD_HS,EBCM_HS
 SG_ StrWhAngMsk : 2|1@0+ (1,0) [0|1] ""  LVMPC_HS,EDI_HS,FCM_HS,HMIM_HS,ICCM_OBD_HS,ICCM_HS,ALC_HS,SADS_HS,VES_HS,EPS_HS,EPB_HS,RDCM_HS,EBCM_OBD_HS,EBCM_HS
 SG_ StrWhlAngSenTyp : 4|2@0+ (1,0) [0|3] ""  EBCM_OBD_HS,EBCM_HS,VES_HS,EPS_HS,HMIM_HS,EPB_HS
 SG_ StrWhlAngSenCalStat : 6|2@0+ (1,0) [0|3] ""  EBCM_OBD_HS,EBCM_HS,HMIM_HS,FCM_HS,ICCM_OBD_HS,ICCM_HS,ALC_HS,SADS_HS,VES_HS,EPS_HS,AHL_AFL_HS,EPB_HS,RDCM_HS,ACC_HS,BCM_HS,TCCM_HS
 SG_ StrWhAngGrd : 27|12@0- (1,0) [-2048|2047] "deg/sec"  FCM_HS,EBCM_OBD_HS,EBCM_HS,HMIM_HS,ACC_HS,PCM_HS,ECM_HS,TCCM_HS,RDCM_HS,ICCM_OBD_HS,ICCM_HS,ALC_HS,SADS_HS,VES_HS,EPS_HS,EPB_HS,FCP_HS,ONSTAR_HS
 SG_ StWhlAngAliveRollCnt : 30|2@0+ (1,0) [0|3] ""  HMIM_HS,EBCM_OBD_HS,EBCM_HS,ICCM_OBD_HS,ICCM_HS,ALC_HS,SADS_HS,VES_HS,EPS_HS,RDCM_HS,EPB_HS
 SG_ StrWhAngV : 7|1@0+ (1,0) [0|1] ""  LVMPC_HS,EDI_HS,HMIM_HS,FCM_HS,EBCM_OBD_HS,EBCM_HS,ICCM_OBD_HS,ICCM_HS,ALC_HS,SADS_HS,VES_HS,EPS_HS,RDCM_HS,FCP_HS,ONSTAR_HS,ACC_HS,BCM_HS,AHL_AFL_HS,EPB_HS,TCCM_HS
 SG_ StrWhAng : 15|16@0- (0.0625,0) [-2048|2047.9375] "deg"  LVMPC_HS,EDI_HS,HMIM_HS,FCM_HS,EBCM_OBD_HS,EBCM_HS,ICCM_OBD_HS,ICCM_HS,ALC_HS,SADS_HS,VES_HS,EPS_HS,RDCM_HS,EPB_HS,FCP_HS,ONSTAR_HS,ACC_HS,AHL_AFL_HS,BCM_HS,TCCM_HS

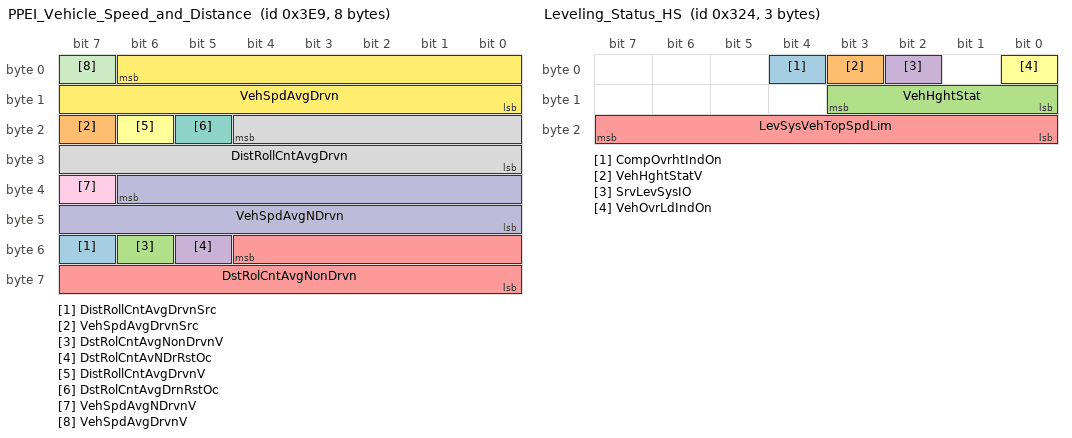
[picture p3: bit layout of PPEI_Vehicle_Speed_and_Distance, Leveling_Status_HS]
BO_ 1001 PPEI_Vehicle_Speed_and_Distance: 8 ECM_HS
 SG_ DistRollCntAvgDrvnSrc : 55|1@0+ (1,0) [0|1] ""  HCP_HS,BCP_HS,HMIM_HS,EBCM_OBD_HS,EBCM_HS,VES_HS,EPS_HS,VICM_HS,TCM_HS,TCCM_HS,BCM_HS
 SG_ VehSpdAvgDrvnSrc : 23|1@0+ (1,0) [0|1] ""  PTO_HS,FICM_HS,EBCM_OBD_HS,EBCM_HS,HMIM_HS,TCM_HS,ARS_HS,VES_HS,EPS_HS,TCCM_HS,EPB_HS,BCM_HS
 SG_ DstRolCntAvgNonDrvnV : 54|1@0+ (1,0) [0|1] ""  VICM_HS,HMIM_HS,EBCM_OBD_HS,EBCM_HS,VES_HS,EPS_HS,TCCM_HS,BCM_HS
 SG_ DstRolCntAvNDrRstOc : 53|1@0+ (1,0) [0|1] ""  VICM_HS,HMIM_HS,EBCM_OBD_HS,EBCM_HS,VES_HS,EPS_HS,TCCM_HS,BCM_HS
 SG_ DstRolCntAvgNonDrvn : 52|13@0+ (0.125,0) [0|1023.875] "m"  VICM_HS,HMIM_HS,EBCM_OBD_HS,EBCM_HS,VES_HS,EPS_HS,TCCM_HS,BCM_HS
 SG_ DistRollCntAvgDrvnV : 22|1@0+ (1,0) [0|1] ""  HCP_HS,BCP_HS,HMIM_HS,EBCM_OBD_HS,EBCM_HS,VES_HS,EPS_HS,VICM_HS,TCM_HS,TCCM_HS,ICCM_OBD_HS,ICCM_HS,FSCM_ITBC_HS,FSCM_HS,BCM_HS
 SG_ DstRolCntAvgDrnRstOc : 21|1@0+ (1,0) [0|1] ""  HCP_HS,BCP_HS,HMIM_HS,EBCM_OBD_HS,EBCM_HS,VES_HS,EPS_HS,VICM_HS,TCM_HS,TCCM_HS,ICCM_OBD_HS,ICCM_HS,FSCM_ITBC_HS,FSCM_HS,BCM_HS
 SG_ DistRollCntAvgDrvn : 20|13@0+ (0.125,0) [0|1023.875] "m"  HCP_HS,BCP_HS,HMIM_HS,EBCM_OBD_HS,EBCM_HS,VES_HS,EPS_HS,VICM_HS,TCM_HS,TCCM_HS,ICCM_OBD_HS,ICCM_HS,FSCM_ITBC_HS,FSCM_HS,BCM_HS
 SG_ VehSpdAvgNDrvnV : 39|1@0+ (1,0) [0|1] ""  VICM2_HS,VLBS_HS,HMIM_HS,FCP_HS,ONSTAR_HS,VES_HS,EPS_HS,VICM_HS,ICCM_OBD_HS,ICCM_HS,EBCM_OBD_HS,EBCM_HS,APPS_HS,TCCM_HS,BCP_HS,EPB_HS,AHL_AFL_HS,BCM_HS,ACC_HS,PTO_HS
 SG_ VehSpdAvgNDrvn : 38|15@0+ (0.015625,0) [0|511.984375] "km / h"  VICM2_HS,VLBS_HS,HMIM_HS,FCP_HS,ONSTAR_HS,VES_HS,EPS_HS,VICM_HS,ICCM_OBD_HS,ICCM_HS,EBCM_OBD_HS,EBCM_HS,APPS_HS,BCP_HS,TCCM_HS,EPB_HS,AHL_AFL_HS,BCM_HS,ACC_HS,PTO_HS
 SG_ VehSpdAvgDrvnV : 7|1@0+ (1,0) [0|1] ""  PFAF_HS,LVMPC_HS,EDI_HS,VLBS_HS,FICM_HS,EBCM_OBD_HS,EBCM_HS,HMIM_HS,TCM_HS,ARS_HS,BCP_HS,ONSTAR_HS,VES_HS,EPS_HS,VICM_HS,APPS_HS,TCCM_HS,FCP_HS,VICM2_HS,FSCM_ITBC_HS,FSCM_HS,EPB_HS,ICCM_OBD_HS,ICCM_HS,ALC_HS,SADS_HS,ACC_HS,BCM_HS,PTO_HS
 SG_ VehSpdAvgDrvn : 6|15@0+ (0.015625,0) [0|511.984375] "km / h"  PFAF_HS,LVMPC_HS,EDI_HS,VLBS_HS,FICM_HS,EBCM_OBD_HS,EBCM_HS,HMIM_HS,TCM_HS,ARS_HS,BCP_HS,ONSTAR_HS,VES_HS,EPS_HS,VICM_HS,APPS_HS,TCCM_HS,VICM2_HS,FSCM_ITBC_HS,FSCM_HS,EPB_HS,ICCM_OBD_HS,ICCM_HS,ALC_HS,SADS_HS,FCP_HS,ACC_HS,BCM_HS,PTO_HS

BO_ 961 PPEI_Powertrain_Immobilizer_Data: 8 ECM_HS
 SG_ PTImmblzerInfo : 7|64@0+ (1,0) [0|1.844674407371E+019] ""  PCM_HS,ECM_HS,VLBS_HS,FCP_HS,ONSTAR_HS,BCM_HS

BO_ 804 Leveling_Status_HS: 3 SADS_HS
 SG_ CompOvrhtIndOn : 4|1@0+ (1,0) [0|1] ""  BCM_HS
 SG_ VehHghtStatV : 3|1@0+ (1,0) [0|1] ""  BCM_HS,EBCM_OBD_HS,EBCM_HS
 SG_ VehHghtStat : 11|4@0+ (1,0) [0|15] ""  BCM_HS,EBCM_OBD_HS,EBCM_HS
 SG_ SrvLevSysIO : 2|1@0+ (1,0) [0|1] ""  BCM_HS,FCP_HS,ONSTAR_HS
 SG_ LevSysVehTopSpdLim : 23|8@0+ (2,0) [0|510] "km/h"  BCM_HS
 SG_ VehOvrLdIndOn : 0|1@0+ (1,0) [0|1] ""  FCP_HS,ONSTAR_HS,BCM_HS

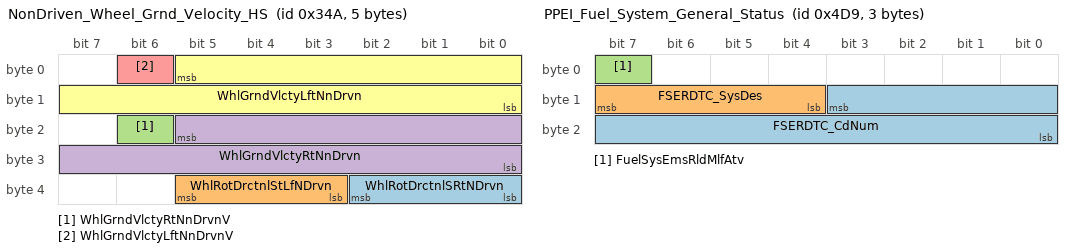
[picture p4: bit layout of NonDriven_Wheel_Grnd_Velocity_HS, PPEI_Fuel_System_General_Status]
BO_ 842 NonDriven_Wheel_Grnd_Velocity_HS: 5 EBCM_HS
 SG_ WhlRotDrctnlSRtNDrvn : 34|3@0+ (1,0) [0|7] ""  VICM_HS,EDI_HS,EOCM_F_HS,HMIM_HS
 SG_ WhlRotDrctnlStLfNDrvn : 37|3@0+ (1,0) [0|7] ""  VICM_HS,EDI_HS,EOCM_F_HS,HMIM_HS
 SG_ WhlGrndVlctyRtNnDrvnV : 22|1@0+ (1,0) [0|1] ""  EDI_HS,HMIM_HS,TCCM_HS,FCM_HS,APPS_HS,EOCM_F_HS,EPB_HS,RDCM_HS,ACC_HS,BCM_HS,AFS_HS,VES_HS,EPS_HS,SADS_HS
 SG_ WhlGrndVlctyRtNnDrvn : 21|14@0+ (0.03125,0) [0|511.96875] "km / h"  EDI_HS,HMIM_HS,TCCM_HS,FCM_HS,APPS_HS,EOCM_F_HS,RDCM_HS,ACC_HS,BCM_HS,EPB_HS,AFS_HS,VES_HS,EPS_HS,SADS_HS
 SG_ WhlGrndVlctyLftNnDrvnV : 6|1@0+ (1,0) [0|1] ""  EDI_HS,HMIM_HS,TCCM_HS,FCM_HS,APPS_HS,EOCM_F_HS,EPB_HS,BCM_HS,RDCM_HS,ACC_HS,AFS_HS,VES_HS,EPS_HS,SADS_HS
 SG_ WhlGrndVlctyLftNnDrvn : 5|14@0+ (0.03125,0) [0|511.96875] "km / h"  EDI_HS,HMIM_HS,TCCM_HS,FCM_HS,APPS_HS,EOCM_F_HS,BCM_HS,RDCM_HS,ACC_HS,EPB_HS,VES_HS,EPS_HS,AFS_HS,SADS_HS

BO_ 1241 PPEI_Fuel_System_General_Status: 3 FSCM_HS
 SG_ FSERDTC_CdNum : 11|12@0+ (1,0) [0|4095] ""  PCM_HS,ECM_HS
 SG_ FSERDTC_SysDes : 15|4@0+ (1,0) [0|15] ""  PCM_HS,ECM_HS
 SG_ FuelSysEmsRldMlfAtv : 7|1@0+ (1,0) [0|1] ""  PCM_HS,ECM_HS

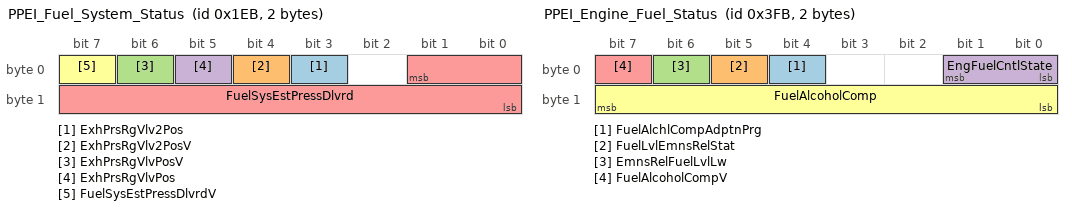
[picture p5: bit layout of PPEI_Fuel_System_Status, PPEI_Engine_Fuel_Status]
BO_ 491 PPEI_Fuel_System_Status: 2 FSCM_HS
 SG_ ExhPrsRgVlv2Pos : 3|1@0+ (1,0) [0|1] ""  ECM_HS
 SG_ ExhPrsRgVlv2PosV : 4|1@0+ (1,0) [0|1] ""  ECM_HS
 SG_ ExhPrsRgVlvPosV : 6|1@0+ (1,0) [0|1] ""  PCM_HS,ECM_HS
 SG_ ExhPrsRgVlvPos : 5|1@0+ (1,0) [0|1] ""  PCM_HS,ECM_HS
 SG_ FuelSysEstPressDlvrd : 1|10@0+ (1,0) [0|1023] "kPa"  VCM_HS,PCM_HS,ECM_HS
 SG_ FuelSysEstPressDlvrdV : 7|1@0+ (1,0) [0|1] ""  VCM_HS,PCM_HS,ECM_HS

BO_ 1019 PPEI_Engine_Fuel_Status: 2 ECM_HS
 SG_ FuelAlchlCompAdptnPrg : 4|1@0+ (1,0) [0|1] ""  BCM_HS
 SG_ FuelLvlEmnsRelStat : 5|1@0+ (1,0) [0|1] ""  FICM_HS,BCP_HS
 SG_ EmnsRelFuelLvlLw : 6|1@0+ (1,0) [0|1] ""  FICM_HS,BCP_HS,ICCM_OBD_HS,ICCM_HS,FSCM_ITBC_HS,FSCM_HS
 SG_ EngFuelCntlState : 1|2@0+ (1,0) [0|3] ""  FICM_HS,ICCM_OBD_HS,ICCM_HS,FSCM_ITBC_HS,FSCM_HS
 SG_ FuelAlcoholCompV : 7|1@0+ (1,0) [0|1] ""  FICM_HS,VICM_HS,FCP_HS,ONSTAR_HS,BCM_HS,ICCM_OBD_HS,ICCM_HS,FSCM_ITBC_HS,FSCM_HS
 SG_ FuelAlcoholComp : 15|8@0+ (0.392157,0) [0|100.000035] "%"  FICM_HS,VICM_HS,FCP_HS,ONSTAR_HS,BCM_HS,ICCM_OBD_HS,ICCM_HS,FSCM_ITBC_HS,FSCM_HS

BO_TX_BU_ 2023 : FCP_HS,ONSTAR_HS,TestTool_HS;
BO_TX_BU_ 2021 : FCP_HS,ONSTAR_HS,TestTool_HS;
BO_TX_BU_ 2017 : FCP_HS,ONSTAR_HS,TestTool_HS;
BO_TX_BU_ 2019 : FCP_HS,ONSTAR_HS,TestTool_HS;
BO_TX_BU_ 585 : FCP_HS,ONSTAR_HS,TestTool_HS;
BO_TX_BU_ 578 : FCP_HS,ONSTAR_HS,TestTool_HS;
BO_TX_BU_ 2022 : FCP_HS,ONSTAR_HS,TestTool_HS;
BO_TX_BU_ 584 : FCP_HS,ONSTAR_HS,TestTool_HS;
BO_TX_BU_ 591 : FCP_HS,ONSTAR_HS,TestTool_HS;
BO_TX_BU_ 581 : FCP_HS,ONSTAR_HS,TestTool_HS;
BO_TX_BU_ 586 : FCP_HS,ONSTAR_HS,TestTool_HS;
BO_TX_BU_ 588 : FCP_HS,ONSTAR_HS,TestTool_HS;
BO_TX_BU_ 580 : FCP_HS,ONSTAR_HS,TestTool_HS;
BO_TX_BU_ 1282 : ICCM_OBD_HS,ICCM_HS,ALC_HS;
BO_TX_BU_ 1920 : EBCM_OBD_HS,EBCM_HS;
BO_TX_BU_ 596 : FCP_HS,ONSTAR_HS,TestTool_HS;
BO_TX_BU_ 495 : PCM_HS,ECM_HS;
BO_TX_BU_ 1914 : TCCM_HS,RDCM_HS;
BO_TX_BU_ 583 : FCP_HS,ONSTAR_HS,TestTool_HS;
BO_TX_BU_ 1906 : PCM_HS,ECM_HS;
BO_TX_BU_ 1907 : EBCM_OBD_HS,EBCM_HS;
BO_TX_BU_ 579 : FCP_HS,ONSTAR_HS,TestTool_HS;
BO_TX_BU_ 1603 : HPCC_HS,EBCM_HS;
BO_TX_BU_ 1347 : HPCC_HS,EBCM_HS;
BO_TX_BU_ 1915 : FCM_HS,ACC_HS;
BO_TX_BU_ 587 : FCP_HS,ONSTAR_HS,TestTool_HS;
BO_TX_BU_ 1611 : EOCM_F_HS,FCM_HS;
BO_TX_BU_ 1355 : EOCM_F_HS,FCM_HS;
BO_TX_BU_ 880 : EOCM_F_HS,ACC_HS;
BO_TX_BU_ 577 : FCP_HS,ONSTAR_HS,TestTool_HS;
BO_TX_BU_ 2018 : FCP_HS,ONSTAR_HS,TestTool_HS;
BO_TX_BU_ 2020 : FCP_HS,ONSTAR_HS,TestTool_HS;
BO_TX_BU_ 485 : SAS_HS,EBCM_OBD_HS,EPS_HS,EBCM_HS;
BO_TX_BU_ 961 : HCP_HS,PCM_HS,ECM_HS;
BO_TX_BU_ 804 : ICCM_OBD_HS,ICCM_HS,ALC_HS,SADS_HS;
BO_TX_BU_ 842 : EBCM_OBD_HS,EBCM_HS;
BO_TX_BU_ 1241 : ICCM_OBD_HS,ICCM_HS,FSCM_ITBC_HS,FSCM_HS;
BO_TX_BU_ 491 : ICCM_OBD_HS,ICCM_HS,FSCM_ITBC_HS,FSCM_HS;
BO_TX_BU_ 1019 : PCM_HS,ECM_HS;
CM_ SG_ 499 PFTrnsTUDSecSwSt "Added 2006 Nov 10 according to CR1112";
CM_ BO_ 1282 "ALC will not (and cannot) be present on vehicles where the ICCM will transmit HS $502. Currently, this is only envisioned for high-performance vehicles.";
CM_ SG_ 1921 DTCI_DTCSource_781 "This shall be equal to the Diagnostic Address of the transmittting device.";
CM_ SG_ 1921 DTCI_DTCFaultType_781 "Based on Powertrain definition.  Not expected to be supported by all devices.";
CM_ SG_ 1921 DTCI_DTCFailType_781 "Assigned per GMW3110, Appendix E";
CM_ SG_ 1920 DTCI_DTCSource_780 "This shall be equal to the Diagnostic Address of the transmittting device.";
CM_ SG_ 1920 DTCI_DTCFaultType_780 "Based on Powertrain definition.  Not expected to be supported by all devices.";
CM_ SG_ 1920 DTCI_DTCFailType_780 "Assigned per GMW3110, Appendix E";
CM_ SG_ 1914 DTCI_DTCFaultType_77A "Based on Powertrain definition.  Not expected to be supported by all devices.";
CM_ SG_ 1914 DTCI_DTCFailType_77A "Assigned per GMW3110, Appendix E";
CM_ SG_ 1914 DTCI_DTCSource_77A "This shall be equal to the Diagnostic Address of the transmittting device.";
CM_ SG_ 1911 DTCI_DTCFaultType_777 "Based on Powertrain definition.  Not expected to be supported by all devices.";
CM_ SG_ 1911 DTCI_DTCFailType_777 "Assigned per GMW3110, Appendix E";
CM_ SG_ 1911 DTCI_DTCSource_777 "This shall be equal to the Diagnostic Address of the transmittting device.";
CM_ SG_ 1906 DTCI_DTCFaultType_772 "Based on Powertrain definition.  Not expected to be supported by all devices.";
CM_ SG_ 1906 DTCI_DTCFailType_772 "Assigned per GMW3110, Appendix E";
CM_ SG_ 1906 DTCI_DTCSource_772 "This shall be equal to the Diagnostic Address of the transmittting device.";
CM_ SG_ 1907 DTCI_DTCFaultType_773 "Based on Powertrain definition.  Not expected to be supported by all devices.";
CM_ SG_ 1907 DTCI_DTCFailType_773 "Assigned per GMW3110, Appendix E";
CM_ SG_ 1907 DTCI_DTCSource_773 "This shall be equal to the Diagnostic Address of the transmittting device.";
CM_ SG_ 1915 DTCI_DTCFaultType_77B "Based on Powertrain definition.  Not expected to be supported by all devices.";
CM_ SG_ 1915 DTCI_DTCFailType_77B "Assigned per GMW3110, Appendix E";
CM_ SG_ 1915 DTCI_DTCSource_77B "This shall be equal to the Diagnostic Address of the transmittting device.";
CM_ BO_ 880 "Note that the ACC algorithm will transmit this message at a 50 ms periodic rate and the EOCM algorithm will transmit this message at a 40 ms periodic rate";
CM_ SG_ 880 ACCHdwyStg "Headway is the  time which results from dividing the following distance (or gap) between vehicles by the vehicle speed.  This setting allows the driver to choose a Headway Setting without actually knowing the value of this time.";
CM_ SG_ 298 DrId "Driver 8 changed to Unknown on 3/30/99";
CM_ SG_ 1300 VehIdNmDig2_9 "Desc: 8 ASCII Characters";
CM_ BO_ 485 "6443-Power Steering Indication On in this frame not used by GlobalA /JD";
CM_ BO_ 491 "Changed for PPEI 3.6 - Should be gated from FSCM";
BA_DEF_ SG_  "VNSigSLHS_VNReq" ENUM  "No","Yes";
BA_DEF_ SG_  "VNSigSLHSSharedDiagnostic" ENUM  "No","Yes";
BA_DEF_ SG_  "SignalType" STRING ;
BA_DEF_ SG_  "PacketOrder" INT 0 65535;
BA_DEF_ SG_  "SignalLongName" STRING ;
BA_DEF_ SG_  "GenSigStartValue" INT 0 65535;
BA_DEF_ SG_  "VNSigAllNodes" ENUM  "No","Yes";
BA_DEF_ SG_  "GenSigDeltaValue" INT 0 0;
BA_DEF_ SG_  "GenSigSendType" ENUM  "not used","not used","not used","not used","not used","not used","not used","NoSigSendType","not used","not used","OnAnyChange","OnChangeIfActive","OnDelta";
BA_DEF_ SG_  "GenSigSendOnInit" ENUM  "Not Initialized","Application","Handler";
BA_DEF_ BO_  "AppGenMsgCycleTime" INT 0 0;
BA_DEF_ BO_  "GenMsgILSupport" ENUM  "No","Yes";
BA_DEF_ BO_  "TpApplType" STRING ;
BA_DEF_ BO_  "Prio" INT 0 7;
BA_DEF_ BO_  "MessageSubnet" ENUM  "LS","MS","HS","CE","PE","HV","FO";
BA_DEF_ BO_  "DiagState" ENUM  "No","Yes";
BA_DEF_ BO_  "GenMsgDelayTime" INT 0 100000;
BA_DEF_ BO_  "GenMsgCycleTime" INT 0 100000;
BA_DEF_ BO_  "GenMsgSendType" ENUM  "cyclicX","spontanX","cyclicIfActiveX","spontanWithDelay","cyclicAndSpontanX","cyclicAndSpontanWithDelay","spontanWithRepitition","cyclicIfActiveAndSpontanWD";
BA_DEF_ BO_  "DiagResponse" ENUM  "No","Yes";
BA_DEF_ BO_  "DiagRequest" ENUM  "No","Yes";
BA_DEF_ BO_  "NmMessage" ENUM  "No","Yes";
BA_DEF_REL_ BU_SG_REL_  "GenSigSuprvRespComment" STRING ;
BA_DEF_REL_ BU_SG_REL_  "GenSigVBitResp" ENUM  "No","Yes";
BA_DEF_REL_ BU_SG_REL_  "GenSigVBitRespComment" STRING ;
BA_DEF_REL_ BU_SG_REL_  "GenSigVDAFailComment" STRING ;
BA_DEF_REL_ BU_SG_REL_  "GenSigVDAFailResp" ENUM  "No","Yes";
BA_DEF_REL_ BU_SG_REL_  "GenSigRxStartValue" STRING ;
BA_DEF_REL_ BU_SG_REL_  "GenSigSuprvRespSubValue" INT 0 65535;
BA_DEF_REL_ BU_SG_REL_  "GenSigSuprvResp" ENUM  "None","Notify App","Substitute Default";
BA_DEF_REL_ BU_SG_REL_  "GenSigTimeoutMsg" HEX -2147483648 268435455;
BA_DEF_REL_ BU_SG_REL_  "GenSigTimeoutTime" INT 0 15000;
BA_DEF_DEF_  "VNSigSLHS_VNReq" "No";
BA_DEF_DEF_  "VNSigSLHSSharedDiagnostic" "No";
BA_DEF_DEF_  "SignalType" "";
BA_DEF_DEF_  "PacketOrder" 0;
BA_DEF_DEF_  "SignalLongName" "";
BA_DEF_DEF_  "GenSigStartValue" 0;
BA_DEF_DEF_  "VNSigAllNodes" "No";
BA_DEF_DEF_  "GenSigDeltaValue" 0;
BA_DEF_DEF_  "GenSigSendType" "NoSigSendType";
BA_DEF_DEF_  "GenSigSendOnInit" "Not Initialized";
BA_DEF_DEF_  "AppGenMsgCycleTime" 0;
BA_DEF_DEF_  "GenMsgILSupport" "Yes";
BA_DEF_DEF_  "TpApplType" "";
BA_DEF_DEF_  "Prio" 4;
BA_DEF_DEF_  "MessageSubnet" "FO";
BA_DEF_DEF_  "DiagState" "No";
BA_DEF_DEF_  "GenMsgDelayTime" 0;
BA_DEF_DEF_  "GenMsgCycleTime" 0;
BA_DEF_DEF_  "GenMsgSendType" "spontanX";
BA_DEF_DEF_  "DiagResponse" "No";
BA_DEF_DEF_  "DiagRequest" "No";
BA_DEF_DEF_  "NmMessage" "No";
BA_DEF_DEF_REL_ "GenSigSuprvRespComment" "";
BA_DEF_DEF_REL_ "GenSigVBitResp" "No";
BA_DEF_DEF_REL_ "GenSigVBitRespComment" "";
BA_DEF_DEF_REL_ "GenSigVDAFailComment" "";
BA_DEF_DEF_REL_ "GenSigVDAFailResp" "No";
BA_DEF_DEF_REL_ "GenSigRxStartValue" "";
BA_DEF_DEF_REL_ "GenSigSuprvRespSubValue" 0;
BA_DEF_DEF_REL_ "GenSigSuprvResp" "None";
BA_DEF_DEF_REL_ "GenSigTimeoutMsg" 0;
BA_DEF_DEF_REL_ "GenSigTimeoutTime" 0;
BA_ "GenMsgILSupport" BO_ 1359 0;
BA_ "TpApplType" BO_ 1359 "DiagUUDTResponse";
BA_ "Prio" BO_ 1359 0;
BA_ "MessageSubnet" BO_ 1359 2;
BA_ "Prio" BO_ 2023 0;
BA_ "MessageSubnet" BO_ 2023 2;
BA_ "DiagRequest" BO_ 2023 1;
BA_ "Prio" BO_ 2021 0;
BA_ "MessageSubnet" BO_ 2021 2;
BA_ "DiagRequest" BO_ 2021 1;
BA_ "Prio" BO_ 2017 0;
BA_ "MessageSubnet" BO_ 2017 2;
BA_ "DiagRequest" BO_ 2017 1;
BA_ "Prio" BO_ 2019 0;
BA_ "MessageSubnet" BO_ 2019 2;
BA_ "DiagRequest" BO_ 2019 1;
BA_ "Prio" BO_ 585 0;
BA_ "MessageSubnet" BO_ 585 2;
BA_ "DiagRequest" BO_ 585 1;
BA_ "Prio" BO_ 578 0;
BA_ "MessageSubnet" BO_ 578 2;
BA_ "DiagRequest" BO_ 578 1;
BA_ "Prio" BO_ 2022 0;
BA_ "MessageSubnet" BO_ 2022 2;
BA_ "DiagRequest" BO_ 2022 1;
BA_ "Prio" BO_ 584 0;
BA_ "MessageSubnet" BO_ 584 2;
BA_ "DiagRequest" BO_ 584 1;
BA_ "Prio" BO_ 591 0;
BA_ "MessageSubnet" BO_ 591 2;
BA_ "DiagRequest" BO_ 591 1;
BA_ "Prio" BO_ 581 0;
BA_ "MessageSubnet" BO_ 581 2;
BA_ "DiagRequest" BO_ 581 1;
BA_ "Prio" BO_ 586 0;
BA_ "MessageSubnet" BO_ 586 2;
BA_ "DiagRequest" BO_ 586 1;
BA_ "GenMsgILSupport" BO_ 588 0;
BA_ "Prio" BO_ 588 0;
BA_ "MessageSubnet" BO_ 588 2;
BA_ "DiagRequest" BO_ 588 1;
BA_ "Prio" BO_ 580 0;
BA_ "MessageSubnet" BO_ 580 2;
BA_ "DiagRequest" BO_ 580 1;
BA_ "Prio" BO_ 499 0;
BA_ "MessageSubnet" BO_ 499 2;
BA_ "GenMsgCycleTime" BO_ 499 30;
BA_ "GenMsgSendType" BO_ 499 0;
BA_ "Prio" BO_ 1282 0;
BA_ "MessageSubnet" BO_ 1282 2;
BA_ "GenMsgCycleTime" BO_ 1282 500;
BA_ "GenMsgSendType" BO_ 1282 0;
BA_ "GenMsgILSupport" BO_ 1360 0;
BA_ "TpApplType" BO_ 1360 "DiagUUDTResponse";
BA_ "Prio" BO_ 1360 0;
BA_ "MessageSubnet" BO_ 1360 2;
BA_ "Prio" BO_ 1616 0;
BA_ "MessageSubnet" BO_ 1616 2;
BA_ "DiagResponse" BO_ 1616 1;
BA_ "Prio" BO_ 1921 0;
BA_ "MessageSubnet" BO_ 1921 2;
BA_ "GenMsgCycleTime" BO_ 1921 1000;
BA_ "GenMsgSendType" BO_ 1921 0;
BA_ "Prio" BO_ 1920 0;
BA_ "MessageSubnet" BO_ 1920 2;
BA_ "GenMsgCycleTime" BO_ 1920 1000;
BA_ "GenMsgSendType" BO_ 1920 0;
BA_ "Prio" BO_ 596 0;
BA_ "MessageSubnet" BO_ 596 2;
BA_ "DiagRequest" BO_ 596 1;
BA_ "Prio" BO_ 2033 0;
BA_ "MessageSubnet" BO_ 2033 2;
BA_ "Prio" BO_ 495 0;
BA_ "MessageSubnet" BO_ 495 2;
BA_ "GenMsgCycleTime" BO_ 495 12;
BA_ "GenMsgSendType" BO_ 495 0;
BA_ "GenMsgILSupport" BO_ 1350 0;
BA_ "TpApplType" BO_ 1350 "DiagUUDTResponse";
BA_ "Prio" BO_ 1350 0;
BA_ "MessageSubnet" BO_ 1350 2;
BA_ "Prio" BO_ 1914 6;
BA_ "MessageSubnet" BO_ 1914 2;
BA_ "GenMsgCycleTime" BO_ 1914 1000;
BA_ "GenMsgSendType" BO_ 1914 0;
BA_ "Prio" BO_ 1911 6;
BA_ "MessageSubnet" BO_ 1911 2;
BA_ "GenMsgCycleTime" BO_ 1911 1000;
BA_ "GenMsgSendType" BO_ 1911 0;
BA_ "Prio" BO_ 583 0;
BA_ "MessageSubnet" BO_ 583 2;
BA_ "DiagRequest" BO_ 583 1;
BA_ "GenMsgILSupport" BO_ 1351 0;
BA_ "TpApplType" BO_ 1351 "DiagUUDTResponse";
BA_ "Prio" BO_ 1351 0;
BA_ "MessageSubnet" BO_ 1351 2;
BA_ "Prio" BO_ 1607 0;
BA_ "MessageSubnet" BO_ 1607 2;
BA_ "DiagResponse" BO_ 1607 1;
BA_ "Prio" BO_ 1906 6;
BA_ "MessageSubnet" BO_ 1906 2;
BA_ "GenMsgCycleTime" BO_ 1906 1000;
BA_ "GenMsgSendType" BO_ 1906 0;
BA_ "Prio" BO_ 1907 6;
BA_ "MessageSubnet" BO_ 1907 2;
BA_ "GenMsgCycleTime" BO_ 1907 1000;
BA_ "GenMsgSendType" BO_ 1907 0;
BA_ "Prio" BO_ 579 0;
BA_ "MessageSubnet" BO_ 579 2;
BA_ "DiagRequest" BO_ 579 1;
BA_ "Prio" BO_ 1603 0;
BA_ "MessageSubnet" BO_ 1603 2;
BA_ "DiagResponse" BO_ 1603 1;
BA_ "GenMsgILSupport" BO_ 1347 0;
BA_ "TpApplType" BO_ 1347 "DiagUUDTResponse";
BA_ "Prio" BO_ 1347 0;
BA_ "MessageSubnet" BO_ 1347 2;
BA_ "Prio" BO_ 1915 6;
BA_ "MessageSubnet" BO_ 1915 2;
BA_ "GenMsgCycleTime" BO_ 1915 1000;
BA_ "GenMsgSendType" BO_ 1915 0;
BA_ "GenMsgILSupport" BO_ 587 0;
BA_ "Prio" BO_ 587 0;
BA_ "MessageSubnet" BO_ 587 2;
BA_ "DiagRequest" BO_ 587 1;
BA_ "GenMsgILSupport" BO_ 1611 0;
BA_ "Prio" BO_ 1611 0;
BA_ "MessageSubnet" BO_ 1611 2;
BA_ "DiagResponse" BO_ 1611 1;
BA_ "GenMsgILSupport" BO_ 1355 0;
BA_ "TpApplType" BO_ 1355 "DiagUUDTResponse";
BA_ "Prio" BO_ 1355 0;
BA_ "MessageSubnet" BO_ 1355 2;
BA_ "AppGenMsgCycleTime" BO_ 880 40;
BA_ "Prio" BO_ 880 0;
BA_ "MessageSubnet" BO_ 880 2;
BA_ "Prio" BO_ 894 0;
BA_ "MessageSubnet" BO_ 894 2;
BA_ "GenMsgCycleTime" BO_ 894 1500;
BA_ "GenMsgSendType" BO_ 894 0;
BA_ "Prio" BO_ 577 0;
BA_ "MessageSubnet" BO_ 577 2;
BA_ "DiagRequest" BO_ 577 1;
BA_ "Prio" BO_ 298 0;
BA_ "MessageSubnet" BO_ 298 2;
BA_ "GenMsgCycleTime" BO_ 298 100;
BA_ "GenMsgSendType" BO_ 298 0;
BA_ "Prio" BO_ 1322 0;
BA_ "MessageSubnet" BO_ 1322 2;
BA_ "GenMsgCycleTime" BO_ 1322 1000;
BA_ "GenMsgSendType" BO_ 1322 0;
BA_ "Prio" BO_ 1601 0;
BA_ "MessageSubnet" BO_ 1601 2;
BA_ "DiagResponse" BO_ 1601 1;
BA_ "Prio" BO_ 2018 0;
BA_ "MessageSubnet" BO_ 2018 2;
BA_ "DiagRequest" BO_ 2018 1;
BA_ "Prio" BO_ 2026 0;
BA_ "MessageSubnet" BO_ 2026 2;
BA_ "DiagResponse" BO_ 2026 1;
BA_ "GenMsgILSupport" BO_ 1514 0;
BA_ "TpApplType" BO_ 1514 "DiagUUDTResponse";
BA_ "Prio" BO_ 1514 0;
BA_ "MessageSubnet" BO_ 1514 2;
BA_ "Prio" BO_ 1300 0;
BA_ "MessageSubnet" BO_ 1300 2;
BA_ "GenMsgCycleTime" BO_ 1300 1000;
BA_ "GenMsgSendType" BO_ 1300 0;
BA_ "Prio" BO_ 288 0;
BA_ "MessageSubnet" BO_ 288 2;
BA_ "GenMsgCycleTime" BO_ 288 5000;
BA_ "GenMsgSendType" BO_ 288 0;
BA_ "Prio" BO_ 2020 0;
BA_ "MessageSubnet" BO_ 2020 2;
BA_ "DiagRequest" BO_ 2020 1;
BA_ "Prio" BO_ 2028 0;
BA_ "MessageSubnet" BO_ 2028 2;
BA_ "DiagResponse" BO_ 2028 1;
BA_ "GenMsgILSupport" BO_ 1516 0;
BA_ "TpApplType" BO_ 1516 "DiagUUDTResponse";
BA_ "Prio" BO_ 1516 0;
BA_ "MessageSubnet" BO_ 1516 2;
BA_ "Prio" BO_ 485 0;
BA_ "MessageSubnet" BO_ 485 2;
BA_ "GenMsgCycleTime" BO_ 485 10;
BA_ "GenMsgSendType" BO_ 485 0;
BA_ "Prio" BO_ 1001 0;
BA_ "MessageSubnet" BO_ 1001 2;
BA_ "GenMsgCycleTime" BO_ 1001 100;
BA_ "GenMsgSendType" BO_ 1001 0;
BA_ "Prio" BO_ 961 0;
BA_ "MessageSubnet" BO_ 961 2;
BA_ "GenMsgCycleTime" BO_ 961 100;
BA_ "GenMsgSendType" BO_ 961 0;
BA_ "Prio" BO_ 804 0;
BA_ "MessageSubnet" BO_ 804 2;
BA_ "GenMsgCycleTime" BO_ 804 500;
BA_ "GenMsgSendType" BO_ 804 0;
BA_ "Prio" BO_ 842 0;
BA_ "MessageSubnet" BO_ 842 2;
BA_ "GenMsgCycleTime" BO_ 842 50;
BA_ "GenMsgSendType" BO_ 842 0;
BA_ "Prio" BO_ 1241 0;
BA_ "MessageSubnet" BO_ 1241 2;
BA_ "GenMsgCycleTime" BO_ 1241 500;
BA_ "GenMsgSendType" BO_ 1241 0;
BA_ "Prio" BO_ 491 0;
BA_ "MessageSubnet" BO_ 491 2;
BA_ "GenMsgCycleTime" BO_ 491 12;
BA_ "GenMsgSendType" BO_ 491 0;
BA_ "Prio" BO_ 1019 0;
BA_ "MessageSubnet" BO_ 1019 2;
BA_ "GenMsgCycleTime" BO_ 1019 250;
BA_ "GenMsgSendType" BO_ 1019 0;
BA_ "VNSigSLHSSharedDiagnostic" SG_ 1359 DgnInf_HS54F 1;
BA_ "SignalType" SG_ 1359 DgnInf_HS54F "UNM";
BA_ "SignalLongName" SG_ 1359 DgnInf_HS54F "Diagnostic Information HS54F";
BA_ "VNSigAllNodes" SG_ 1359 DgnInf_HS54F 1;
BA_ "VNSigSLHSSharedDiagnostic" SG_ 2023 DgnInf 1;
BA_ "SignalType" SG_ 2023 DgnInf "UNM";
BA_ "SignalLongName" SG_ 2023 DgnInf "Diagnostic Information";
BA_ "VNSigAllNodes" SG_ 2023 DgnInf 1;
BA_ "VNSigSLHSSharedDiagnostic" SG_ 2021 DgnInf 1;
BA_ "SignalType" SG_ 2021 DgnInf "UNM";
BA_ "SignalLongName" SG_ 2021 DgnInf "Diagnostic Information";
BA_ "VNSigAllNodes" SG_ 2021 DgnInf 1;
BA_ "VNSigSLHSSharedDiagnostic" SG_ 2017 DgnInf 1;
BA_ "SignalType" SG_ 2017 DgnInf "UNM";
BA_ "SignalLongName" SG_ 2017 DgnInf "Diagnostic Information";
BA_ "VNSigAllNodes" SG_ 2017 DgnInf 1;
BA_ "VNSigSLHSSharedDiagnostic" SG_ 2019 DgnInf 1;
BA_ "SignalType" SG_ 2019 DgnInf "UNM";
BA_ "SignalLongName" SG_ 2019 DgnInf "Diagnostic Information";
BA_ "VNSigAllNodes" SG_ 2019 DgnInf 1;
BA_ "VNSigSLHSSharedDiagnostic" SG_ 585 DgnInf 1;
BA_ "SignalType" SG_ 585 DgnInf "UNM";
BA_ "SignalLongName" SG_ 585 DgnInf "Diagnostic Information";
BA_ "VNSigAllNodes" SG_ 585 DgnInf 1;
BA_ "VNSigSLHSSharedDiagnostic" SG_ 578 DgnInf 1;
BA_ "SignalType" SG_ 578 DgnInf "UNM";
BA_ "SignalLongName" SG_ 578 DgnInf "Diagnostic Information";
BA_ "VNSigAllNodes" SG_ 578 DgnInf 1;
BA_ "VNSigSLHSSharedDiagnostic" SG_ 2022 DgnInf 1;
BA_ "SignalType" SG_ 2022 DgnInf "UNM";
BA_ "SignalLongName" SG_ 2022 DgnInf "Diagnostic Information";
BA_ "VNSigAllNodes" SG_ 2022 DgnInf 1;
BA_ "VNSigSLHSSharedDiagnostic" SG_ 584 DgnInf 1;
BA_ "SignalType" SG_ 584 DgnInf "UNM";
BA_ "SignalLongName" SG_ 584 DgnInf "Diagnostic Information";
BA_ "VNSigAllNodes" SG_ 584 DgnInf 1;
BA_ "VNSigSLHSSharedDiagnostic" SG_ 591 DgnInf 1;
BA_ "SignalType" SG_ 591 DgnInf "UNM";
BA_ "SignalLongName" SG_ 591 DgnInf "Diagnostic Information";
BA_ "VNSigAllNodes" SG_ 591 DgnInf 1;
BA_ "VNSigSLHSSharedDiagnostic" SG_ 581 DgnInf 1;
BA_ "SignalType" SG_ 581 DgnInf "UNM";
BA_ "SignalLongName" SG_ 581 DgnInf "Diagnostic Information";
BA_ "VNSigAllNodes" SG_ 581 DgnInf 1;
BA_ "VNSigSLHSSharedDiagnostic" SG_ 586 DgnInf 1;
BA_ "SignalType" SG_ 586 DgnInf "UNM";
BA_ "SignalLongName" SG_ 586 DgnInf "Diagnostic Information";
BA_ "VNSigAllNodes" SG_ 586 DgnInf 1;
BA_ "VNSigSLHSSharedDiagnostic" SG_ 588 DgnInf 1;
BA_ "SignalType" SG_ 588 DgnInf "UNM";
BA_ "SignalLongName" SG_ 588 DgnInf "Diagnostic Information";
BA_ "VNSigAllNodes" SG_ 588 DgnInf 1;
BA_ "VNSigSLHSSharedDiagnostic" SG_ 580 DgnInf 1;
BA_ "SignalType" SG_ 580 DgnInf "UNM";
BA_ "SignalLongName" SG_ 580 DgnInf "Diagnostic Information";
BA_ "VNSigAllNodes" SG_ 580 DgnInf 1;
BA_ "SignalType" SG_ 499 PTShftPtrnOvrdAct "BLN";
BA_ "SignalLongName" SG_ 499 PTShftPtrnOvrdAct "Powertrain Shift Pattern Override Active";
BA_ "VNSigAllNodes" SG_ 499 PTShftPtrnOvrdAct 1;
BA_ "SignalType" SG_ 499 PFTrnsTUDSecSwSt "ENM";
BA_ "SignalLongName" SG_ 499 PFTrnsTUDSecSwSt "Platform Transmission Tap Up/Down Secondary Switch State";
BA_ "VNSigAllNodes" SG_ 499 PFTrnsTUDSecSwSt 1;
BA_ "SignalType" SG_ 499 TrnsPFShftPattSwARC "UNM";
BA_ "SignalLongName" SG_ 499 TrnsPFShftPattSwARC "Transmission Platform Shift Pattern Switch Alive Rolling Count";
BA_ "VNSigAllNodes" SG_ 499 TrnsPFShftPattSwARC 1;
BA_ "SignalType" SG_ 499 TrnsPFShftPattSw4Act "BLN";
BA_ "SignalLongName" SG_ 499 TrnsPFShftPattSw4Act "Transmission Platform Shift Pattern Switch 4 Active";
BA_ "VNSigAllNodes" SG_ 499 TrnsPFShftPattSw4Act 1;
BA_ "SignalType" SG_ 499 TrnsPFShftPattSw3Act "BLN";
BA_ "SignalLongName" SG_ 499 TrnsPFShftPattSw3Act "Transmission Platform Shift Pattern Switch 3 Active";
BA_ "VNSigAllNodes" SG_ 499 TrnsPFShftPattSw3Act 1;
BA_ "SignalType" SG_ 499 TrnsPFShftPattSw2Act "BLN";
BA_ "SignalLongName" SG_ 499 TrnsPFShftPattSw2Act "Transmission Platform Shift Pattern Switch 2 Active";
BA_ "VNSigAllNodes" SG_ 499 TrnsPFShftPattSw2Act 1;
BA_ "SignalType" SG_ 499 TrnsPFShftPattSw1Act "BLN";
BA_ "SignalLongName" SG_ 499 TrnsPFShftPattSw1Act "Transmission Platform Shift Pattern Switch 1 Active";
BA_ "VNSigAllNodes" SG_ 499 TrnsPFShftPattSw1Act 1;
BA_ "SignalType" SG_ 499 PFTrnsTUDSwStAlvRC "UNM";
BA_ "SignalLongName" SG_ 499 PFTrnsTUDSwStAlvRC "Platform Transmission Tap Up/Down Switch Status Alive Rolling Count";
BA_ "VNSigAllNodes" SG_ 499 PFTrnsTUDSwStAlvRC 1;
BA_ "SignalType" SG_ 499 PFTrnsTUDSwSt "ENM";
BA_ "SignalLongName" SG_ 499 PFTrnsTUDSwSt "Platform Transmission Tap Up/Down Switch State";
BA_ "VNSigAllNodes" SG_ 499 PFTrnsTUDSwSt 1;
BA_ "SignalType" SG_ 499 PFTrnsTUDEnSwSt "ENM";
BA_ "SignalLongName" SG_ 499 PFTrnsTUDEnSwSt "Platform Transmission Tap Up/Down Enable Switch State";
BA_ "VNSigAllNodes" SG_ 499 PFTrnsTUDEnSwSt 1;
BA_ "SignalType" SG_ 499 OvrdrvDsblReqd "BLN";
BA_ "SignalLongName" SG_ 499 OvrdrvDsblReqd "Overdrive Disable Requested";
BA_ "VNSigAllNodes" SG_ 499 OvrdrvDsblReqd 1;
BA_ "SignalType" SG_ 1282 TireTrdTmpStatARC "UNM";
BA_ "SignalLongName" SG_ 1282 TireTrdTmpStatARC "Tire Tread Temperature Status Alive Rolling Count";
BA_ "VNSigAllNodes" SG_ 1282 TireTrdTmpStatARC 1;
BA_ "SignalType" SG_ 1282 TireTrdTmpStat "ENM";
BA_ "SignalLongName" SG_ 1282 TireTrdTmpStat "Tire Tread Temperature Status";
BA_ "VNSigAllNodes" SG_ 1282 TireTrdTmpStat 1;
BA_ "VNSigSLHS_VNReq" SG_ 1282 AllNodesVNA_502 1;
BA_ "SignalType" SG_ 1282 AllNodesVNA_502 "ENM";
BA_ "SignalLongName" SG_ 1282 AllNodesVNA_502 "All Nodes Virtual Network Activation";
BA_ "VNSigAllNodes" SG_ 1282 AllNodesVNA_502 1;
BA_ "SignalType" SG_ 1282 A3ERRAlrmTime "UNM";
BA_ "PacketOrder" SG_ 1282 A3ERRAlrmTime 2;
BA_ "SignalLongName" SG_ 1282 A3ERRAlrmTime "Alarm 3 Extended Range Request : Alarm Time";
BA_ "VNSigAllNodes" SG_ 1282 A3ERRAlrmTime 1;
BA_ "SignalType" SG_ 1282 A3ERRAlrmReq "ENM";
BA_ "PacketOrder" SG_ 1282 A3ERRAlrmReq 1;
BA_ "SignalLongName" SG_ 1282 A3ERRAlrmReq "Alarm 3 Extended Range Request : Alarm Request";
BA_ "VNSigAllNodes" SG_ 1282 A3ERRAlrmReq 1;
BA_ "VNSigSLHSSharedDiagnostic" SG_ 1360 DgnInf_HS550 1;
BA_ "SignalType" SG_ 1360 DgnInf_HS550 "UNM";
BA_ "SignalLongName" SG_ 1360 DgnInf_HS550 "Diagnostic Information HS550";
BA_ "VNSigAllNodes" SG_ 1360 DgnInf_HS550 1;
BA_ "VNSigSLHSSharedDiagnostic" SG_ 1616 DgnInf 1;
BA_ "SignalType" SG_ 1616 DgnInf "UNM";
BA_ "SignalLongName" SG_ 1616 DgnInf "Diagnostic Information";
BA_ "VNSigAllNodes" SG_ 1616 DgnInf 1;
BA_ "SignalType" SG_ 1921 DTCI_CurrentStatus_781 "BLN";
BA_ "PacketOrder" SG_ 1921 DTCI_CurrentStatus_781 18;
BA_ "SignalLongName" SG_ 1921 DTCI_CurrentStatus_781 "Diagnostic Trouble Code Information Extended 781: Current Status";
BA_ "VNSigAllNodes" SG_ 1921 DTCI_CurrentStatus_781 1;
BA_ "SignalType" SG_ 1921 DTCI_WrnIndRqdSt_781 "BLN";
BA_ "PacketOrder" SG_ 1921 DTCI_WrnIndRqdSt_781 12;
BA_ "SignalLongName" SG_ 1921 DTCI_WrnIndRqdSt_781 "Diagnostic Trouble Code Information Extended 781 : Warning Indicator Requested Status";
BA_ "VNSigAllNodes" SG_ 1921 DTCI_WrnIndRqdSt_781 1;
BA_ "SignalType" SG_ 1921 DTCIUnused7_781 "BLN";
BA_ "PacketOrder" SG_ 1921 DTCIUnused7_781 7;
BA_ "SignalLongName" SG_ 1921 DTCIUnused7_781 "Diagnostic Trouble Code Information Extended 781 : Unused 7";
BA_ "VNSigAllNodes" SG_ 1921 DTCIUnused7_781 1;
BA_ "SignalType" SG_ 1921 DTCIUnused6_781 "BLN";
BA_ "PacketOrder" SG_ 1921 DTCIUnused6_781 6;
BA_ "SignalLongName" SG_ 1921 DTCIUnused6_781 "Diagnostic Trouble Code Information Extended 781 : Unused 6";
BA_ "VNSigAllNodes" SG_ 1921 DTCIUnused6_781 1;
BA_ "SignalType" SG_ 1921 DTCIUnused5_781 "BLN";
BA_ "PacketOrder" SG_ 1921 DTCIUnused5_781 5;
BA_ "SignalLongName" SG_ 1921 DTCIUnused5_781 "Diagnostic Trouble Code Information Extended 781 : Unused 5";
BA_ "VNSigAllNodes" SG_ 1921 DTCIUnused5_781 1;
BA_ "SignalType" SG_ 1921 DTCIUnused4_781 "BLN";
BA_ "PacketOrder" SG_ 1921 DTCIUnused4_781 4;
BA_ "SignalLongName" SG_ 1921 DTCIUnused4_781 "Diagnostic Trouble Code Information Extended 781 : Unused 4";
BA_ "VNSigAllNodes" SG_ 1921 DTCIUnused4_781 1;
BA_ "SignalType" SG_ 1921 DTCIUnused3_781 "BLN";
BA_ "PacketOrder" SG_ 1921 DTCIUnused3_781 3;
BA_ "SignalLongName" SG_ 1921 DTCIUnused3_781 "Diagnostic Trouble Code Information Extended 781 : Unused 3";
BA_ "VNSigAllNodes" SG_ 1921 DTCIUnused3_781 1;
BA_ "SignalType" SG_ 1921 DTCIUnused2_781 "BLN";
BA_ "PacketOrder" SG_ 1921 DTCIUnused2_781 2;
BA_ "SignalLongName" SG_ 1921 DTCIUnused2_781 "Diagnostic Trouble Code Information Extended 781 : Unused 2";
BA_ "VNSigAllNodes" SG_ 1921 DTCIUnused2_781 1;
BA_ "SignalType" SG_ 1921 DTCIUnused1_781 "BLN";
BA_ "PacketOrder" SG_ 1921 DTCIUnused1_781 1;
BA_ "SignalLongName" SG_ 1921 DTCIUnused1_781 "Diagnostic Trouble Code Information Extended 781 : Unused 1";
BA_ "VNSigAllNodes" SG_ 1921 DTCIUnused1_781 1;
BA_ "SignalType" SG_ 1921 DTCI_TstNPsdPwrUpSt_781 "BLN";
BA_ "PacketOrder" SG_ 1921 DTCI_TstNPsdPwrUpSt_781 14;
BA_ "SignalLongName" SG_ 1921 DTCI_TstNPsdPwrUpSt_781 "Diagnostic Trouble Code Information Extended 781 : Test Not Passed Since Power Up Status";
BA_ "VNSigAllNodes" SG_ 1921 DTCI_TstNPsdPwrUpSt_781 1;
BA_ "SignalType" SG_ 1921 DTCI_TstNPsdCdClrdSt_781 "BLN";
BA_ "PacketOrder" SG_ 1921 DTCI_TstNPsdCdClrdSt_781 17;
BA_ "SignalLongName" SG_ 1921 DTCI_TstNPsdCdClrdSt_781 "Diagnostic Trouble Code Information Extended 781 : Test Not Passed Since Code Cleared Status";
BA_ "VNSigAllNodes" SG_ 1921 DTCI_TstNPsdCdClrdSt_781 1;
BA_ "SignalType" SG_ 1921 DTCI_TstFldPwrUpSt_781 "BLN";
BA_ "PacketOrder" SG_ 1921 DTCI_TstFldPwrUpSt_781 13;
BA_ "SignalLongName" SG_ 1921 DTCI_TstFldPwrUpSt_781 "Diagnostic Trouble Code Information Extended 781 : Test Failed Since Power Up Status";
BA_ "VNSigAllNodes" SG_ 1921 DTCI_TstFldPwrUpSt_781 1;
BA_ "SignalType" SG_ 1921 DTCI_TstFldCdClrdStat_781 "BLN";
BA_ "PacketOrder" SG_ 1921 DTCI_TstFldCdClrdStat_781 16;
BA_ "SignalLongName" SG_ 1921 DTCI_TstFldCdClrdStat_781 "Diagnostic Trouble Code Information Extended 781 : Test Failed Since Code Cleared Status";
BA_ "VNSigAllNodes" SG_ 1921 DTCI_TstFldCdClrdStat_781 1;
BA_ "SignalType" SG_ 1921 DTCI_HistStat_781 "BLN";
BA_ "PacketOrder" SG_ 1921 DTCI_HistStat_781 15;
BA_ "SignalLongName" SG_ 1921 DTCI_HistStat_781 "Diagnostic Trouble Code Information Extended 781 : History Status";
BA_ "VNSigAllNodes" SG_ 1921 DTCI_HistStat_781 1;
BA_ "SignalType" SG_ 1921 DTCI_DTCTriggered_781 "BLN";
BA_ "PacketOrder" SG_ 1921 DTCI_DTCTriggered_781 8;
BA_ "SignalLongName" SG_ 1921 DTCI_DTCTriggered_781 "Diagnostic Trouble Code Information Extended 781 : Diagnostic Trouble Code Triggered";
BA_ "VNSigAllNodes" SG_ 1921 DTCI_DTCTriggered_781 1;
BA_ "SignalType" SG_ 1921 DTCI_DTCSource_781 "UNM";
BA_ "PacketOrder" SG_ 1921 DTCI_DTCSource_781 9;
BA_ "SignalLongName" SG_ 1921 DTCI_DTCSource_781 "Diagnostic Trouble Code Information Extended 781 : Diagnostic Trouble Code Source";
BA_ "VNSigAllNodes" SG_ 1921 DTCI_DTCSource_781 1;
BA_ "SignalType" SG_ 1921 DTCI_DTCNumber_781 "UNM";
BA_ "PacketOrder" SG_ 1921 DTCI_DTCNumber_781 10;
BA_ "SignalLongName" SG_ 1921 DTCI_DTCNumber_781 "Diagnostic Trouble Code Information Extended 781 : Diagnostic Trouble Code Number";
BA_ "VNSigAllNodes" SG_ 1921 DTCI_DTCNumber_781 1;
BA_ "SignalType" SG_ 1921 DTCI_DTCFaultType_781 "ENM";
BA_ "PacketOrder" SG_ 1921 DTCI_DTCFaultType_781 20;
BA_ "SignalLongName" SG_ 1921 DTCI_DTCFaultType_781 "Diagnostic Trouble Code Information Extended 781 : Diagnostic Trouble Code Fault Type";
BA_ "VNSigAllNodes" SG_ 1921 DTCI_DTCFaultType_781 1;
BA_ "SignalType" SG_ 1921 DTCI_DTCFailType_781 "UNM";
BA_ "PacketOrder" SG_ 1921 DTCI_DTCFailType_781 11;
BA_ "SignalLongName" SG_ 1921 DTCI_DTCFailType_781 "Diagnostic Trouble Code Information Extended 781 : Diagnostic Trouble Code Failure Type";
BA_ "VNSigAllNodes" SG_ 1921 DTCI_DTCFailType_781 1;
BA_ "SignalType" SG_ 1921 DTCI_CodeSupported_781 "BLN";
BA_ "PacketOrder" SG_ 1921 DTCI_CodeSupported_781 19;
BA_ "SignalLongName" SG_ 1921 DTCI_CodeSupported_781 "Diagnostic Trouble Code Information Extended 781 : Code Supported";
BA_ "VNSigAllNodes" SG_ 1921 DTCI_CodeSupported_781 1;
BA_ "SignalType" SG_ 1920 DTCI_CurrentStatus_780 "BLN";
BA_ "PacketOrder" SG_ 1920 DTCI_CurrentStatus_780 18;
BA_ "SignalLongName" SG_ 1920 DTCI_CurrentStatus_780 "Diagnostic Trouble Code Information Extended 780 : Current Status";
BA_ "VNSigAllNodes" SG_ 1920 DTCI_CurrentStatus_780 1;
BA_ "SignalType" SG_ 1920 DTCI_WrnIndRqdSt_780 "BLN";
BA_ "PacketOrder" SG_ 1920 DTCI_WrnIndRqdSt_780 12;
BA_ "SignalLongName" SG_ 1920 DTCI_WrnIndRqdSt_780 "Diagnostic Trouble Code Information Extended 780 : Warning Indicator Requested Status";
BA_ "VNSigAllNodes" SG_ 1920 DTCI_WrnIndRqdSt_780 1;
BA_ "SignalType" SG_ 1920 DTCIUnused7_780 "BLN";
BA_ "PacketOrder" SG_ 1920 DTCIUnused7_780 7;
BA_ "SignalLongName" SG_ 1920 DTCIUnused7_780 "Diagnostic Trouble Code Information Extended 780 : Unused 7";
BA_ "VNSigAllNodes" SG_ 1920 DTCIUnused7_780 1;
BA_ "SignalType" SG_ 1920 DTCIUnused6_780 "BLN";
BA_ "PacketOrder" SG_ 1920 DTCIUnused6_780 6;
BA_ "SignalLongName" SG_ 1920 DTCIUnused6_780 "Diagnostic Trouble Code Information Extended 780 : Unused 6";
BA_ "VNSigAllNodes" SG_ 1920 DTCIUnused6_780 1;
BA_ "SignalType" SG_ 1920 DTCIUnused5_780 "BLN";
BA_ "PacketOrder" SG_ 1920 DTCIUnused5_780 5;
BA_ "SignalLongName" SG_ 1920 DTCIUnused5_780 "Diagnostic Trouble Code Information Extended 780 : Unused 5";
BA_ "VNSigAllNodes" SG_ 1920 DTCIUnused5_780 1;
BA_ "SignalType" SG_ 1920 DTCIUnused4_780 "BLN";
BA_ "PacketOrder" SG_ 1920 DTCIUnused4_780 4;
BA_ "SignalLongName" SG_ 1920 DTCIUnused4_780 "Diagnostic Trouble Code Information Extended 780 : Unused 4";
BA_ "VNSigAllNodes" SG_ 1920 DTCIUnused4_780 1;
BA_ "SignalType" SG_ 1920 DTCIUnused3_780 "BLN";
BA_ "PacketOrder" SG_ 1920 DTCIUnused3_780 3;
BA_ "SignalLongName" SG_ 1920 DTCIUnused3_780 "Diagnostic Trouble Code Information Extended 780 : Unused 3";
BA_ "VNSigAllNodes" SG_ 1920 DTCIUnused3_780 1;
BA_ "SignalType" SG_ 1920 DTCIUnused2_780 "BLN";
BA_ "PacketOrder" SG_ 1920 DTCIUnused2_780 2;
BA_ "SignalLongName" SG_ 1920 DTCIUnused2_780 "Diagnostic Trouble Code Information Extended 780 : Unused 2";
BA_ "VNSigAllNodes" SG_ 1920 DTCIUnused2_780 1;
BA_ "SignalType" SG_ 1920 DTCIUnused1_780 "BLN";
BA_ "PacketOrder" SG_ 1920 DTCIUnused1_780 1;
BA_ "SignalLongName" SG_ 1920 DTCIUnused1_780 "Diagnostic Trouble Code Information Extended 780 : Unused 1";
BA_ "VNSigAllNodes" SG_ 1920 DTCIUnused1_780 1;
BA_ "SignalType" SG_ 1920 DTCI_TstNPsdPwrUpSt_780 "BLN";
BA_ "PacketOrder" SG_ 1920 DTCI_TstNPsdPwrUpSt_780 14;
BA_ "SignalLongName" SG_ 1920 DTCI_TstNPsdPwrUpSt_780 "Diagnostic Trouble Code Information Extended 780 : Test Not Passed Since Power Up Status";
BA_ "VNSigAllNodes" SG_ 1920 DTCI_TstNPsdPwrUpSt_780 1;
BA_ "SignalType" SG_ 1920 DTCI_TstNPsdCdClrdSt_780 "BLN";
BA_ "PacketOrder" SG_ 1920 DTCI_TstNPsdCdClrdSt_780 17;
BA_ "SignalLongName" SG_ 1920 DTCI_TstNPsdCdClrdSt_780 "Diagnostic Trouble Code Information Extended 780 : Test Not Passed Since Code Cleared Status";
BA_ "VNSigAllNodes" SG_ 1920 DTCI_TstNPsdCdClrdSt_780 1;
BA_ "SignalType" SG_ 1920 DTCI_TstFldPwrUpSt_780 "BLN";
BA_ "PacketOrder" SG_ 1920 DTCI_TstFldPwrUpSt_780 13;
BA_ "SignalLongName" SG_ 1920 DTCI_TstFldPwrUpSt_780 "Diagnostic Trouble Code Information Extended 780 : Test Failed Since Power Up Status";
BA_ "VNSigAllNodes" SG_ 1920 DTCI_TstFldPwrUpSt_780 1;
BA_ "SignalType" SG_ 1920 DTCI_TstFldCdClrdStat_780 "BLN";
BA_ "PacketOrder" SG_ 1920 DTCI_TstFldCdClrdStat_780 16;
BA_ "SignalLongName" SG_ 1920 DTCI_TstFldCdClrdStat_780 "Diagnostic Trouble Code Information Extended 780 : Test Failed Since Code Cleared Status";
BA_ "VNSigAllNodes" SG_ 1920 DTCI_TstFldCdClrdStat_780 1;
BA_ "SignalType" SG_ 1920 DTCI_HistStat_780 "BLN";
BA_ "PacketOrder" SG_ 1920 DTCI_HistStat_780 15;
BA_ "SignalLongName" SG_ 1920 DTCI_HistStat_780 "Diagnostic Trouble Code Information Extended 780 : History Status";
BA_ "VNSigAllNodes" SG_ 1920 DTCI_HistStat_780 1;
BA_ "SignalType" SG_ 1920 DTCI_DTCTriggered_780 "BLN";
BA_ "PacketOrder" SG_ 1920 DTCI_DTCTriggered_780 8;
BA_ "SignalLongName" SG_ 1920 DTCI_DTCTriggered_780 "Diagnostic Trouble Code Information Extended 780 : Diagnostic Trouble Code Triggered";
BA_ "VNSigAllNodes" SG_ 1920 DTCI_DTCTriggered_780 1;
BA_ "SignalType" SG_ 1920 DTCI_DTCSource_780 "UNM";
BA_ "PacketOrder" SG_ 1920 DTCI_DTCSource_780 9;
BA_ "SignalLongName" SG_ 1920 DTCI_DTCSource_780 "Diagnostic Trouble Code Information Extended 780 : Diagnostic Trouble Code Source";
BA_ "VNSigAllNodes" SG_ 1920 DTCI_DTCSource_780 1;
BA_ "SignalType" SG_ 1920 DTCI_DTCNumber_780 "UNM";
BA_ "PacketOrder" SG_ 1920 DTCI_DTCNumber_780 10;
BA_ "SignalLongName" SG_ 1920 DTCI_DTCNumber_780 "Diagnostic Trouble Code Information Extended 780 : Diagnostic Trouble Code Number";
BA_ "VNSigAllNodes" SG_ 1920 DTCI_DTCNumber_780 1;
BA_ "SignalType" SG_ 1920 DTCI_DTCFaultType_780 "ENM";
BA_ "PacketOrder" SG_ 1920 DTCI_DTCFaultType_780 20;
BA_ "SignalLongName" SG_ 1920 DTCI_DTCFaultType_780 "Diagnostic Trouble Code Information Extended 780 : Diagnostic Trouble Code Fault Type";
BA_ "VNSigAllNodes" SG_ 1920 DTCI_DTCFaultType_780 1;
BA_ "SignalType" SG_ 1920 DTCI_DTCFailType_780 "UNM";
BA_ "PacketOrder" SG_ 1920 DTCI_DTCFailType_780 11;
BA_ "SignalLongName" SG_ 1920 DTCI_DTCFailType_780 "Diagnostic Trouble Code Information Extended 780 : Diagnostic Trouble Code Failure Type";
BA_ "VNSigAllNodes" SG_ 1920 DTCI_DTCFailType_780 1;
BA_ "SignalType" SG_ 1920 DTCI_CodeSupported_780 "BLN";
BA_ "PacketOrder" SG_ 1920 DTCI_CodeSupported_780 19;
BA_ "SignalLongName" SG_ 1920 DTCI_CodeSupported_780 "Diagnostic Trouble Code Information Extended 780 : Code Supported";
BA_ "VNSigAllNodes" SG_ 1920 DTCI_CodeSupported_780 1;
BA_ "VNSigSLHSSharedDiagnostic" SG_ 596 DgnInf 1;
BA_ "SignalType" SG_ 596 DgnInf "UNM";
BA_ "SignalLongName" SG_ 596 DgnInf "Diagnostic Information";
BA_ "VNSigAllNodes" SG_ 596 DgnInf 1;
BA_ "GenSigDeltaValue" SG_ 2033 PCUInfo 1;
BA_ "GenSigSendType" SG_ 2033 PCUInfo 12;
BA_ "SignalType" SG_ 2033 PCUInfo "UNM";
BA_ "SignalLongName" SG_ 2033 PCUInfo "Pyrotechnical Control Unit Information";
BA_ "VNSigAllNodes" SG_ 2033 PCUInfo 1;
BA_ "SignalType" SG_ 495 MassAirFloV "ENM";
BA_ "SignalLongName" SG_ 495 MassAirFloV "Mass Air Flow Validity";
BA_ "VNSigAllNodes" SG_ 495 MassAirFloV 1;
BA_ "SignalType" SG_ 495 MassAirFlo "UNM";
BA_ "SignalLongName" SG_ 495 MassAirFlo "Mass Air Flow";
BA_ "VNSigAllNodes" SG_ 495 MassAirFlo 1;
BA_ "VNSigSLHSSharedDiagnostic" SG_ 1350 DgnInf_HS546 1;
BA_ "SignalType" SG_ 1350 DgnInf_HS546 "UNM";
BA_ "SignalLongName" SG_ 1350 DgnInf_HS546 "Diagnostic Information HS546";
BA_ "VNSigAllNodes" SG_ 1350 DgnInf_HS546 1;
BA_ "SignalType" SG_ 1914 DTCI_DTCFaultType_77A "ENM";
BA_ "PacketOrder" SG_ 1914 DTCI_DTCFaultType_77A 20;
BA_ "SignalLongName" SG_ 1914 DTCI_DTCFaultType_77A "Diagnostic Trouble Code Information Extended 77A : Diagnostic Trouble Code Fault Type";
BA_ "VNSigAllNodes" SG_ 1914 DTCI_DTCFaultType_77A 1;
BA_ "SignalType" SG_ 1914 DTCI_CodeSupported_77A "BLN";
BA_ "PacketOrder" SG_ 1914 DTCI_CodeSupported_77A 19;
BA_ "SignalLongName" SG_ 1914 DTCI_CodeSupported_77A "Diagnostic Trouble Code Information Extended 77A : Code Supported";
BA_ "VNSigAllNodes" SG_ 1914 DTCI_CodeSupported_77A 1;
BA_ "SignalType" SG_ 1914 DTCI_CurrentStatus_77A "BLN";
BA_ "PacketOrder" SG_ 1914 DTCI_CurrentStatus_77A 18;
BA_ "SignalLongName" SG_ 1914 DTCI_CurrentStatus_77A "Diagnostic Trouble Code Information Extended 77A : Current Status";
BA_ "VNSigAllNodes" SG_ 1914 DTCI_CurrentStatus_77A 1;
BA_ "SignalType" SG_ 1914 DTCI_TstNPsdCdClrdSt_77A "BLN";
BA_ "PacketOrder" SG_ 1914 DTCI_TstNPsdCdClrdSt_77A 17;
BA_ "SignalLongName" SG_ 1914 DTCI_TstNPsdCdClrdSt_77A "Diagnostic Trouble Code Information Extended 77A : Test Not Passed Since Code Cleared Status";
BA_ "VNSigAllNodes" SG_ 1914 DTCI_TstNPsdCdClrdSt_77A 1;
BA_ "SignalType" SG_ 1914 DTCI_TstFldCdClrdStat_77A "BLN";
BA_ "PacketOrder" SG_ 1914 DTCI_TstFldCdClrdStat_77A 16;
BA_ "SignalLongName" SG_ 1914 DTCI_TstFldCdClrdStat_77A "Diagnostic Trouble Code Information Extended 77A : Test Failed Since Code Cleared Status";
BA_ "VNSigAllNodes" SG_ 1914 DTCI_TstFldCdClrdStat_77A 1;
BA_ "SignalType" SG_ 1914 DTCI_HistStat_77A "BLN";
BA_ "PacketOrder" SG_ 1914 DTCI_HistStat_77A 15;
BA_ "SignalLongName" SG_ 1914 DTCI_HistStat_77A "Diagnostic Trouble Code Information Extended 77A : History Status";
BA_ "VNSigAllNodes" SG_ 1914 DTCI_HistStat_77A 1;
BA_ "SignalType" SG_ 1914 DTCI_TstNPsdPwrUpSt_77A "BLN";
BA_ "PacketOrder" SG_ 1914 DTCI_TstNPsdPwrUpSt_77A 14;
BA_ "SignalLongName" SG_ 1914 DTCI_TstNPsdPwrUpSt_77A "Diagnostic Trouble Code Information Extended 77A : Test Not Passed Since Power Up Status";
BA_ "VNSigAllNodes" SG_ 1914 DTCI_TstNPsdPwrUpSt_77A 1;
BA_ "SignalType" SG_ 1914 DTCI_TstFldPwrUpSt_77A "BLN";
BA_ "PacketOrder" SG_ 1914 DTCI_TstFldPwrUpSt_77A 13;
BA_ "SignalLongName" SG_ 1914 DTCI_TstFldPwrUpSt_77A "Diagnostic Trouble Code Information Extended 77A : Test Failed Since Power Up Status";
BA_ "VNSigAllNodes" SG_ 1914 DTCI_TstFldPwrUpSt_77A 1;
BA_ "SignalType" SG_ 1914 DTCI_WrnIndRqdSt_77A "BLN";
BA_ "PacketOrder" SG_ 1914 DTCI_WrnIndRqdSt_77A 12;
BA_ "SignalLongName" SG_ 1914 DTCI_WrnIndRqdSt_77A "Diagnostic Trouble Code Information Extended 77A : Warning Indicator Requested Status";
BA_ "VNSigAllNodes" SG_ 1914 DTCI_WrnIndRqdSt_77A 1;
BA_ "SignalType" SG_ 1914 DTCI_DTCFailType_77A "UNM";
BA_ "PacketOrder" SG_ 1914 DTCI_DTCFailType_77A 11;
BA_ "SignalLongName" SG_ 1914 DTCI_DTCFailType_77A "Diagnostic Trouble Code Information Extended 77A : Diagnostic Trouble Code Failure Type";
BA_ "VNSigAllNodes" SG_ 1914 DTCI_DTCFailType_77A 1;
BA_ "SignalType" SG_ 1914 DTCI_DTCNumber_77A "UNM";
BA_ "PacketOrder" SG_ 1914 DTCI_DTCNumber_77A 10;
BA_ "SignalLongName" SG_ 1914 DTCI_DTCNumber_77A "Diagnostic Trouble Code Information Extended 77A : Diagnostic Trouble Code Number";
BA_ "VNSigAllNodes" SG_ 1914 DTCI_DTCNumber_77A 1;
BA_ "SignalType" SG_ 1914 DTCI_DTCSource_77A "UNM";
BA_ "PacketOrder" SG_ 1914 DTCI_DTCSource_77A 9;
BA_ "SignalLongName" SG_ 1914 DTCI_DTCSource_77A "Diagnostic Trouble Code Information Extended 77A : Diagnostic Trouble Code Source";
BA_ "VNSigAllNodes" SG_ 1914 DTCI_DTCSource_77A 1;
BA_ "SignalType" SG_ 1914 DTCI_DTCTriggered_77A "BLN";
BA_ "PacketOrder" SG_ 1914 DTCI_DTCTriggered_77A 8;
BA_ "SignalLongName" SG_ 1914 DTCI_DTCTriggered_77A "Diagnostic Trouble Code Information Extended 77A : Diagnostic Trouble Code Triggered";
BA_ "VNSigAllNodes" SG_ 1914 DTCI_DTCTriggered_77A 1;
BA_ "SignalType" SG_ 1914 DTCIUnused7_77A "BLN";
BA_ "PacketOrder" SG_ 1914 DTCIUnused7_77A 7;
BA_ "SignalLongName" SG_ 1914 DTCIUnused7_77A "Diagnostic Trouble Code Information Extended 77A : Unused 7";
BA_ "VNSigAllNodes" SG_ 1914 DTCIUnused7_77A 1;
BA_ "SignalType" SG_ 1914 DTCIUnused6_77A "BLN";
BA_ "PacketOrder" SG_ 1914 DTCIUnused6_77A 6;
BA_ "SignalLongName" SG_ 1914 DTCIUnused6_77A "Diagnostic Trouble Code Information Extended 77A : Unused 6";
BA_ "VNSigAllNodes" SG_ 1914 DTCIUnused6_77A 1;
BA_ "SignalType" SG_ 1914 DTCIUnused5_77A "BLN";
BA_ "PacketOrder" SG_ 1914 DTCIUnused5_77A 5;
BA_ "SignalLongName" SG_ 1914 DTCIUnused5_77A "Diagnostic Trouble Code Information Extended 77A : Unused 5";
BA_ "VNSigAllNodes" SG_ 1914 DTCIUnused5_77A 1;
BA_ "SignalType" SG_ 1914 DTCIUnused4_77A "BLN";
BA_ "PacketOrder" SG_ 1914 DTCIUnused4_77A 4;
BA_ "SignalLongName" SG_ 1914 DTCIUnused4_77A "Diagnostic Trouble Code Information Extended 77A : Unused 4";
BA_ "VNSigAllNodes" SG_ 1914 DTCIUnused4_77A 1;
BA_ "SignalType" SG_ 1914 DTCIUnused3_77A "BLN";
BA_ "PacketOrder" SG_ 1914 DTCIUnused3_77A 3;
BA_ "SignalLongName" SG_ 1914 DTCIUnused3_77A "Diagnostic Trouble Code Information Extended 77A : Unused 3";
BA_ "VNSigAllNodes" SG_ 1914 DTCIUnused3_77A 1;
BA_ "SignalType" SG_ 1914 DTCIUnused2_77A "BLN";
BA_ "PacketOrder" SG_ 1914 DTCIUnused2_77A 2;
BA_ "SignalLongName" SG_ 1914 DTCIUnused2_77A "Diagnostic Trouble Code Information Extended 77A : Unused 2";
BA_ "VNSigAllNodes" SG_ 1914 DTCIUnused2_77A 1;
BA_ "SignalType" SG_ 1914 DTCIUnused1_77A "BLN";
BA_ "PacketOrder" SG_ 1914 DTCIUnused1_77A 1;
BA_ "SignalLongName" SG_ 1914 DTCIUnused1_77A "Diagnostic Trouble Code Information Extended 77A : Unused 1";
BA_ "VNSigAllNodes" SG_ 1914 DTCIUnused1_77A 1;
BA_ "SignalType" SG_ 1911 DTCI_DTCFaultType_777 "ENM";
BA_ "PacketOrder" SG_ 1911 DTCI_DTCFaultType_777 20;
BA_ "SignalLongName" SG_ 1911 DTCI_DTCFaultType_777 "Diagnostic Trouble Code Information Extended 777 : Diagnostic Trouble Code Fault Type";
BA_ "VNSigAllNodes" SG_ 1911 DTCI_DTCFaultType_777 1;
BA_ "SignalType" SG_ 1911 DTCI_CodeSupported_777 "BLN";
BA_ "PacketOrder" SG_ 1911 DTCI_CodeSupported_777 19;
BA_ "SignalLongName" SG_ 1911 DTCI_CodeSupported_777 "Diagnostic Trouble Code Information Extended 777 : Code Supported";
BA_ "VNSigAllNodes" SG_ 1911 DTCI_CodeSupported_777 1;
BA_ "SignalType" SG_ 1911 DTCI_CurrentStatus_777 "BLN";
BA_ "PacketOrder" SG_ 1911 DTCI_CurrentStatus_777 18;
BA_ "SignalLongName" SG_ 1911 DTCI_CurrentStatus_777 "Diagnostic Trouble Code Information Extended 777 : Current Status";
BA_ "VNSigAllNodes" SG_ 1911 DTCI_CurrentStatus_777 1;
BA_ "SignalType" SG_ 1911 DTCI_TstNPsdCdClrdSt_777 "BLN";
BA_ "PacketOrder" SG_ 1911 DTCI_TstNPsdCdClrdSt_777 17;
BA_ "SignalLongName" SG_ 1911 DTCI_TstNPsdCdClrdSt_777 "Diagnostic Trouble Code Information Extended 777 : Test Not Passed Since Code Cleared Status";
BA_ "VNSigAllNodes" SG_ 1911 DTCI_TstNPsdCdClrdSt_777 1;
BA_ "SignalType" SG_ 1911 DTCI_TstFldCdClrdStat_777 "BLN";
BA_ "PacketOrder" SG_ 1911 DTCI_TstFldCdClrdStat_777 16;
BA_ "SignalLongName" SG_ 1911 DTCI_TstFldCdClrdStat_777 "Diagnostic Trouble Code Information Extended 777 : Test Failed Since Code Cleared Status";
BA_ "VNSigAllNodes" SG_ 1911 DTCI_TstFldCdClrdStat_777 1;
BA_ "SignalType" SG_ 1911 DTCI_HistStat_777 "BLN";
BA_ "PacketOrder" SG_ 1911 DTCI_HistStat_777 15;
BA_ "SignalLongName" SG_ 1911 DTCI_HistStat_777 "Diagnostic Trouble Code Information Extended 777 : History Status";
BA_ "VNSigAllNodes" SG_ 1911 DTCI_HistStat_777 1;
BA_ "SignalType" SG_ 1911 DTCI_TstNPsdPwrUpSt_777 "BLN";
BA_ "PacketOrder" SG_ 1911 DTCI_TstNPsdPwrUpSt_777 14;
BA_ "SignalLongName" SG_ 1911 DTCI_TstNPsdPwrUpSt_777 "Diagnostic Trouble Code Information Extended 777 : Test Not Passed Since Power Up Status";
BA_ "VNSigAllNodes" SG_ 1911 DTCI_TstNPsdPwrUpSt_777 1;
BA_ "SignalType" SG_ 1911 DTCI_TstFldPwrUpSt_777 "BLN";
BA_ "PacketOrder" SG_ 1911 DTCI_TstFldPwrUpSt_777 13;
BA_ "SignalLongName" SG_ 1911 DTCI_TstFldPwrUpSt_777 "Diagnostic Trouble Code Information Extended 777 : Test Failed Since Power Up Status";
BA_ "VNSigAllNodes" SG_ 1911 DTCI_TstFldPwrUpSt_777 1;
BA_ "SignalType" SG_ 1911 DTCI_WrnIndRqdSt_777 "BLN";
BA_ "PacketOrder" SG_ 1911 DTCI_WrnIndRqdSt_777 12;
BA_ "SignalLongName" SG_ 1911 DTCI_WrnIndRqdSt_777 "Diagnostic Trouble Code Information Extended 777 : Warning Indicator Requested Status";
BA_ "VNSigAllNodes" SG_ 1911 DTCI_WrnIndRqdSt_777 1;
BA_ "SignalType" SG_ 1911 DTCI_DTCFailType_777 "UNM";
BA_ "PacketOrder" SG_ 1911 DTCI_DTCFailType_777 11;
BA_ "SignalLongName" SG_ 1911 DTCI_DTCFailType_777 "Diagnostic Trouble Code Information Extended 777 : Diagnostic Trouble Code Failure Type";
BA_ "VNSigAllNodes" SG_ 1911 DTCI_DTCFailType_777 1;
BA_ "SignalType" SG_ 1911 DTCI_DTCNumber_777 "UNM";
BA_ "PacketOrder" SG_ 1911 DTCI_DTCNumber_777 10;
BA_ "SignalLongName" SG_ 1911 DTCI_DTCNumber_777 "Diagnostic Trouble Code Information Extended 777 : Diagnostic Trouble Code Number";
BA_ "VNSigAllNodes" SG_ 1911 DTCI_DTCNumber_777 1;
BA_ "SignalType" SG_ 1911 DTCI_DTCSource_777 "UNM";
BA_ "PacketOrder" SG_ 1911 DTCI_DTCSource_777 9;
BA_ "SignalLongName" SG_ 1911 DTCI_DTCSource_777 "Diagnostic Trouble Code Information Extended 777 : Diagnostic Trouble Code Source";
BA_ "VNSigAllNodes" SG_ 1911 DTCI_DTCSource_777 1;
BA_ "SignalType" SG_ 1911 DTCI_DTCTriggered_777 "BLN";
BA_ "PacketOrder" SG_ 1911 DTCI_DTCTriggered_777 8;
BA_ "SignalLongName" SG_ 1911 DTCI_DTCTriggered_777 "Diagnostic Trouble Code Information Extended 777 : Diagnostic Trouble Code Triggered";
BA_ "VNSigAllNodes" SG_ 1911 DTCI_DTCTriggered_777 1;
BA_ "SignalType" SG_ 1911 DTCIUnused7_777 "BLN";
BA_ "PacketOrder" SG_ 1911 DTCIUnused7_777 7;
BA_ "SignalLongName" SG_ 1911 DTCIUnused7_777 "Diagnostic Trouble Code Information Extended 777 : Unused 7";
BA_ "VNSigAllNodes" SG_ 1911 DTCIUnused7_777 1;
BA_ "SignalType" SG_ 1911 DTCIUnused6_777 "BLN";
BA_ "PacketOrder" SG_ 1911 DTCIUnused6_777 6;
BA_ "SignalLongName" SG_ 1911 DTCIUnused6_777 "Diagnostic Trouble Code Information Extended 777 : Unused 6";
BA_ "VNSigAllNodes" SG_ 1911 DTCIUnused6_777 1;
BA_ "SignalType" SG_ 1911 DTCIUnused5_777 "BLN";
BA_ "PacketOrder" SG_ 1911 DTCIUnused5_777 5;
BA_ "SignalLongName" SG_ 1911 DTCIUnused5_777 "Diagnostic Trouble Code Information Extended 777 : Unused 5";
BA_ "VNSigAllNodes" SG_ 1911 DTCIUnused5_777 1;
BA_ "SignalType" SG_ 1911 DTCIUnused4_777 "BLN";
BA_ "PacketOrder" SG_ 1911 DTCIUnused4_777 4;
BA_ "SignalLongName" SG_ 1911 DTCIUnused4_777 "Diagnostic Trouble Code Information Extended 777 : Unused 4";
BA_ "VNSigAllNodes" SG_ 1911 DTCIUnused4_777 1;
BA_ "SignalType" SG_ 1911 DTCIUnused3_777 "BLN";
BA_ "PacketOrder" SG_ 1911 DTCIUnused3_777 3;
BA_ "SignalLongName" SG_ 1911 DTCIUnused3_777 "Diagnostic Trouble Code Information Extended 777 : Unused 3";
BA_ "VNSigAllNodes" SG_ 1911 DTCIUnused3_777 1;
BA_ "SignalType" SG_ 1911 DTCIUnused2_777 "BLN";
BA_ "PacketOrder" SG_ 1911 DTCIUnused2_777 2;
BA_ "SignalLongName" SG_ 1911 DTCIUnused2_777 "Diagnostic Trouble Code Information Extended 777 : Unused 2";
BA_ "VNSigAllNodes" SG_ 1911 DTCIUnused2_777 1;
BA_ "SignalType" SG_ 1911 DTCIUnused1_777 "BLN";
BA_ "PacketOrder" SG_ 1911 DTCIUnused1_777 1;
BA_ "SignalLongName" SG_ 1911 DTCIUnused1_777 "Diagnostic Trouble Code Information Extended 777 : Unused 1";
BA_ "VNSigAllNodes" SG_ 1911 DTCIUnused1_777 1;
BA_ "VNSigSLHSSharedDiagnostic" SG_ 583 DgnInf 1;
BA_ "SignalType" SG_ 583 DgnInf "UNM";
BA_ "SignalLongName" SG_ 583 DgnInf "Diagnostic Information";
BA_ "VNSigAllNodes" SG_ 583 DgnInf 1;
BA_ "VNSigSLHSSharedDiagnostic" SG_ 1351 DgnInf_HS547 1;
BA_ "SignalType" SG_ 1351 DgnInf_HS547 "UNM";
BA_ "SignalLongName" SG_ 1351 DgnInf_HS547 "Diagnostic Information HS547";
BA_ "VNSigAllNodes" SG_ 1351 DgnInf_HS547 1;
BA_ "VNSigSLHSSharedDiagnostic" SG_ 1607 DgnInf 1;
BA_ "SignalType" SG_ 1607 DgnInf "UNM";
BA_ "SignalLongName" SG_ 1607 DgnInf "Diagnostic Information";
BA_ "VNSigAllNodes" SG_ 1607 DgnInf 1;
BA_ "SignalType" SG_ 1906 DTCI_DTCFaultType_772 "ENM";
BA_ "PacketOrder" SG_ 1906 DTCI_DTCFaultType_772 20;
BA_ "SignalLongName" SG_ 1906 DTCI_DTCFaultType_772 "Diagnostic Trouble Code Information Extended 772 : Diagnostic Trouble Code Fault Type";
BA_ "VNSigAllNodes" SG_ 1906 DTCI_DTCFaultType_772 1;
BA_ "SignalType" SG_ 1906 DTCI_CodeSupported_772 "BLN";
BA_ "PacketOrder" SG_ 1906 DTCI_CodeSupported_772 19;
BA_ "SignalLongName" SG_ 1906 DTCI_CodeSupported_772 "Diagnostic Trouble Code Information Extended 772 : Code Supported";
BA_ "VNSigAllNodes" SG_ 1906 DTCI_CodeSupported_772 1;
BA_ "SignalType" SG_ 1906 DTCI_CurrentStatus_772 "BLN";
BA_ "PacketOrder" SG_ 1906 DTCI_CurrentStatus_772 18;
BA_ "SignalLongName" SG_ 1906 DTCI_CurrentStatus_772 "Diagnostic Trouble Code Information Extended 772 : Current Status";
BA_ "VNSigAllNodes" SG_ 1906 DTCI_CurrentStatus_772 1;
BA_ "SignalType" SG_ 1906 DTCI_TstNPsdCdClrdSt_772 "BLN";
BA_ "PacketOrder" SG_ 1906 DTCI_TstNPsdCdClrdSt_772 17;
BA_ "SignalLongName" SG_ 1906 DTCI_TstNPsdCdClrdSt_772 "Diagnostic Trouble Code Information Extended 772 : Test Not Passed Since Code Cleared Status";
BA_ "VNSigAllNodes" SG_ 1906 DTCI_TstNPsdCdClrdSt_772 1;
BA_ "SignalType" SG_ 1906 DTCI_TstFldCdClrdStat_772 "BLN";
BA_ "PacketOrder" SG_ 1906 DTCI_TstFldCdClrdStat_772 16;
BA_ "SignalLongName" SG_ 1906 DTCI_TstFldCdClrdStat_772 "Diagnostic Trouble Code Information Extended 772 : Test Failed Since Code Cleared Status";
BA_ "VNSigAllNodes" SG_ 1906 DTCI_TstFldCdClrdStat_772 1;
BA_ "SignalType" SG_ 1906 DTCI_HistStat_772 "BLN";
BA_ "PacketOrder" SG_ 1906 DTCI_HistStat_772 15;
BA_ "SignalLongName" SG_ 1906 DTCI_HistStat_772 "Diagnostic Trouble Code Information Extended 772 : History Status";
BA_ "VNSigAllNodes" SG_ 1906 DTCI_HistStat_772 1;
BA_ "SignalType" SG_ 1906 DTCI_TstNPsdPwrUpSt_772 "BLN";
BA_ "PacketOrder" SG_ 1906 DTCI_TstNPsdPwrUpSt_772 14;
BA_ "SignalLongName" SG_ 1906 DTCI_TstNPsdPwrUpSt_772 "Diagnostic Trouble Code Information Extended 772 : Test Not Passed Since Power Up Status";
BA_ "VNSigAllNodes" SG_ 1906 DTCI_TstNPsdPwrUpSt_772 1;
BA_ "SignalType" SG_ 1906 DTCI_TstFldPwrUpSt_772 "BLN";
BA_ "PacketOrder" SG_ 1906 DTCI_TstFldPwrUpSt_772 13;
BA_ "SignalLongName" SG_ 1906 DTCI_TstFldPwrUpSt_772 "Diagnostic Trouble Code Information Extended 772 : Test Failed Since Power Up Status";
BA_ "VNSigAllNodes" SG_ 1906 DTCI_TstFldPwrUpSt_772 1;
BA_ "SignalType" SG_ 1906 DTCI_WrnIndRqdSt_772 "BLN";
BA_ "PacketOrder" SG_ 1906 DTCI_WrnIndRqdSt_772 12;
BA_ "SignalLongName" SG_ 1906 DTCI_WrnIndRqdSt_772 "Diagnostic Trouble Code Information Extended 772 : Warning Indicator Requested Status";
BA_ "VNSigAllNodes" SG_ 1906 DTCI_WrnIndRqdSt_772 1;
BA_ "SignalType" SG_ 1906 DTCI_DTCFailType_772 "UNM";
BA_ "PacketOrder" SG_ 1906 DTCI_DTCFailType_772 11;
BA_ "SignalLongName" SG_ 1906 DTCI_DTCFailType_772 "Diagnostic Trouble Code Information Extended 772 : Diagnostic Trouble Code Failure Type";
BA_ "VNSigAllNodes" SG_ 1906 DTCI_DTCFailType_772 1;
BA_ "SignalType" SG_ 1906 DTCI_DTCNumber_772 "UNM";
BA_ "PacketOrder" SG_ 1906 DTCI_DTCNumber_772 10;
BA_ "SignalLongName" SG_ 1906 DTCI_DTCNumber_772 "Diagnostic Trouble Code Information Extended 772 : Diagnostic Trouble Code Number";
BA_ "VNSigAllNodes" SG_ 1906 DTCI_DTCNumber_772 1;
BA_ "SignalType" SG_ 1906 DTCI_DTCSource_772 "UNM";
BA_ "PacketOrder" SG_ 1906 DTCI_DTCSource_772 9;
BA_ "SignalLongName" SG_ 1906 DTCI_DTCSource_772 "Diagnostic Trouble Code Information Extended 772 : Diagnostic Trouble Code Source";
BA_ "VNSigAllNodes" SG_ 1906 DTCI_DTCSource_772 1;
BA_ "SignalType" SG_ 1906 DTCI_DTCTriggered_772 "BLN";
BA_ "PacketOrder" SG_ 1906 DTCI_DTCTriggered_772 8;
BA_ "SignalLongName" SG_ 1906 DTCI_DTCTriggered_772 "Diagnostic Trouble Code Information Extended 772 : Diagnostic Trouble Code Triggered";
BA_ "VNSigAllNodes" SG_ 1906 DTCI_DTCTriggered_772 1;
BA_ "SignalType" SG_ 1906 DTCIUnused7_772 "BLN";
BA_ "PacketOrder" SG_ 1906 DTCIUnused7_772 7;
BA_ "SignalLongName" SG_ 1906 DTCIUnused7_772 "Diagnostic Trouble Code Information Extended 772 : Unused 7";
BA_ "VNSigAllNodes" SG_ 1906 DTCIUnused7_772 1;
BA_ "SignalType" SG_ 1906 DTCIUnused6_772 "BLN";
BA_ "PacketOrder" SG_ 1906 DTCIUnused6_772 6;
BA_ "SignalLongName" SG_ 1906 DTCIUnused6_772 "Diagnostic Trouble Code Information Extended 772 : Unused 6";
BA_ "VNSigAllNodes" SG_ 1906 DTCIUnused6_772 1;
BA_ "SignalType" SG_ 1906 DTCIUnused5_772 "BLN";
BA_ "PacketOrder" SG_ 1906 DTCIUnused5_772 5;
BA_ "SignalLongName" SG_ 1906 DTCIUnused5_772 "Diagnostic Trouble Code Information Extended 772 : Unused 5";
BA_ "VNSigAllNodes" SG_ 1906 DTCIUnused5_772 1;
BA_ "SignalType" SG_ 1906 DTCIUnused4_772 "BLN";
BA_ "PacketOrder" SG_ 1906 DTCIUnused4_772 4;
BA_ "SignalLongName" SG_ 1906 DTCIUnused4_772 "Diagnostic Trouble Code Information Extended 772 : Unused 4";
BA_ "VNSigAllNodes" SG_ 1906 DTCIUnused4_772 1;
BA_ "SignalType" SG_ 1906 DTCIUnused3_772 "BLN";
BA_ "PacketOrder" SG_ 1906 DTCIUnused3_772 3;
BA_ "SignalLongName" SG_ 1906 DTCIUnused3_772 "Diagnostic Trouble Code Information Extended 772 : Unused 3";
BA_ "VNSigAllNodes" SG_ 1906 DTCIUnused3_772 1;
BA_ "SignalType" SG_ 1906 DTCIUnused2_772 "BLN";
BA_ "PacketOrder" SG_ 1906 DTCIUnused2_772 2;
BA_ "SignalLongName" SG_ 1906 DTCIUnused2_772 "Diagnostic Trouble Code Information Extended 772 : Unused 2";
BA_ "VNSigAllNodes" SG_ 1906 DTCIUnused2_772 1;
BA_ "SignalType" SG_ 1906 DTCIUnused1_772 "BLN";
BA_ "PacketOrder" SG_ 1906 DTCIUnused1_772 1;
BA_ "SignalLongName" SG_ 1906 DTCIUnused1_772 "Diagnostic Trouble Code Information Extended 772 : Unused 1";
BA_ "VNSigAllNodes" SG_ 1906 DTCIUnused1_772 1;
BA_ "SignalType" SG_ 1907 DTCI_DTCFaultType_773 "ENM";
BA_ "PacketOrder" SG_ 1907 DTCI_DTCFaultType_773 20;
BA_ "SignalLongName" SG_ 1907 DTCI_DTCFaultType_773 "Diagnostic Trouble Code Information Extended 773 : Diagnostic Trouble Code Fault Type";
BA_ "VNSigAllNodes" SG_ 1907 DTCI_DTCFaultType_773 1;
BA_ "SignalType" SG_ 1907 DTCI_CodeSupported_773 "BLN";
BA_ "PacketOrder" SG_ 1907 DTCI_CodeSupported_773 19;
BA_ "SignalLongName" SG_ 1907 DTCI_CodeSupported_773 "Diagnostic Trouble Code Information Extended 773 : Code Supported";
BA_ "VNSigAllNodes" SG_ 1907 DTCI_CodeSupported_773 1;
BA_ "SignalType" SG_ 1907 DTCI_CurrentStatus_773 "BLN";
BA_ "PacketOrder" SG_ 1907 DTCI_CurrentStatus_773 18;
BA_ "SignalLongName" SG_ 1907 DTCI_CurrentStatus_773 "Diagnostic Trouble Code Information Extended 773 : Current Status";
BA_ "VNSigAllNodes" SG_ 1907 DTCI_CurrentStatus_773 1;
BA_ "SignalType" SG_ 1907 DTCI_TstNPsdCdClrdSt_773 "BLN";
BA_ "PacketOrder" SG_ 1907 DTCI_TstNPsdCdClrdSt_773 17;
BA_ "SignalLongName" SG_ 1907 DTCI_TstNPsdCdClrdSt_773 "Diagnostic Trouble Code Information Extended 773 : Test Not Passed Since Code Cleared Status";
BA_ "VNSigAllNodes" SG_ 1907 DTCI_TstNPsdCdClrdSt_773 1;
BA_ "SignalType" SG_ 1907 DTCI_TstFldCdClrdStat_773 "BLN";
BA_ "PacketOrder" SG_ 1907 DTCI_TstFldCdClrdStat_773 16;
BA_ "SignalLongName" SG_ 1907 DTCI_TstFldCdClrdStat_773 "Diagnostic Trouble Code Information Extended 773 : Test Failed Since Code Cleared Status";
BA_ "VNSigAllNodes" SG_ 1907 DTCI_TstFldCdClrdStat_773 1;
BA_ "SignalType" SG_ 1907 DTCI_HistStat_773 "BLN";
BA_ "PacketOrder" SG_ 1907 DTCI_HistStat_773 15;
BA_ "SignalLongName" SG_ 1907 DTCI_HistStat_773 "Diagnostic Trouble Code Information Extended 773 : History Status";
BA_ "VNSigAllNodes" SG_ 1907 DTCI_HistStat_773 1;
BA_ "SignalType" SG_ 1907 DTCI_TstNPsdPwrUpSt_773 "BLN";
BA_ "PacketOrder" SG_ 1907 DTCI_TstNPsdPwrUpSt_773 14;
BA_ "SignalLongName" SG_ 1907 DTCI_TstNPsdPwrUpSt_773 "Diagnostic Trouble Code Information Extended 773 : Test Not Passed Since Power Up Status";
BA_ "VNSigAllNodes" SG_ 1907 DTCI_TstNPsdPwrUpSt_773 1;
BA_ "SignalType" SG_ 1907 DTCI_TstFldPwrUpSt_773 "BLN";
BA_ "PacketOrder" SG_ 1907 DTCI_TstFldPwrUpSt_773 13;
BA_ "SignalLongName" SG_ 1907 DTCI_TstFldPwrUpSt_773 "Diagnostic Trouble Code Information Extended 773 : Test Failed Since Power Up Status";
BA_ "VNSigAllNodes" SG_ 1907 DTCI_TstFldPwrUpSt_773 1;
BA_ "SignalType" SG_ 1907 DTCI_WrnIndRqdSt_773 "BLN";
BA_ "PacketOrder" SG_ 1907 DTCI_WrnIndRqdSt_773 12;
BA_ "SignalLongName" SG_ 1907 DTCI_WrnIndRqdSt_773 "Diagnostic Trouble Code Information Extended 773 : Warning Indicator Requested Status";
BA_ "VNSigAllNodes" SG_ 1907 DTCI_WrnIndRqdSt_773 1;
BA_ "SignalType" SG_ 1907 DTCI_DTCFailType_773 "UNM";
BA_ "PacketOrder" SG_ 1907 DTCI_DTCFailType_773 11;
BA_ "SignalLongName" SG_ 1907 DTCI_DTCFailType_773 "Diagnostic Trouble Code Information Extended 773 : Diagnostic Trouble Code Failure Type";
BA_ "VNSigAllNodes" SG_ 1907 DTCI_DTCFailType_773 1;
BA_ "SignalType" SG_ 1907 DTCI_DTCNumber_773 "UNM";
BA_ "PacketOrder" SG_ 1907 DTCI_DTCNumber_773 10;
BA_ "SignalLongName" SG_ 1907 DTCI_DTCNumber_773 "Diagnostic Trouble Code Information Extended 773 : Diagnostic Trouble Code Number";
BA_ "VNSigAllNodes" SG_ 1907 DTCI_DTCNumber_773 1;
BA_ "SignalType" SG_ 1907 DTCI_DTCSource_773 "UNM";
BA_ "PacketOrder" SG_ 1907 DTCI_DTCSource_773 9;
BA_ "SignalLongName" SG_ 1907 DTCI_DTCSource_773 "Diagnostic Trouble Code Information Extended 773 : Diagnostic Trouble Code Source";
BA_ "VNSigAllNodes" SG_ 1907 DTCI_DTCSource_773 1;
BA_ "SignalType" SG_ 1907 DTCI_DTCTriggered_773 "BLN";
BA_ "PacketOrder" SG_ 1907 DTCI_DTCTriggered_773 8;
BA_ "SignalLongName" SG_ 1907 DTCI_DTCTriggered_773 "Diagnostic Trouble Code Information Extended 773 : Diagnostic Trouble Code Triggered";
BA_ "VNSigAllNodes" SG_ 1907 DTCI_DTCTriggered_773 1;
BA_ "SignalType" SG_ 1907 DTCIUnused7_773 "BLN";
BA_ "PacketOrder" SG_ 1907 DTCIUnused7_773 7;
BA_ "SignalLongName" SG_ 1907 DTCIUnused7_773 "Diagnostic Trouble Code Information Extended 773 : Unused 7";
BA_ "VNSigAllNodes" SG_ 1907 DTCIUnused7_773 1;
BA_ "SignalType" SG_ 1907 DTCIUnused6_773 "BLN";
BA_ "PacketOrder" SG_ 1907 DTCIUnused6_773 6;
BA_ "SignalLongName" SG_ 1907 DTCIUnused6_773 "Diagnostic Trouble Code Information Extended 773 : Unused 6";
BA_ "VNSigAllNodes" SG_ 1907 DTCIUnused6_773 1;
BA_ "SignalType" SG_ 1907 DTCIUnused5_773 "BLN";
BA_ "PacketOrder" SG_ 1907 DTCIUnused5_773 5;
BA_ "SignalLongName" SG_ 1907 DTCIUnused5_773 "Diagnostic Trouble Code Information Extended 773 : Unused 5";
BA_ "VNSigAllNodes" SG_ 1907 DTCIUnused5_773 1;
BA_ "SignalType" SG_ 1907 DTCIUnused4_773 "BLN";
BA_ "PacketOrder" SG_ 1907 DTCIUnused4_773 4;
BA_ "SignalLongName" SG_ 1907 DTCIUnused4_773 "Diagnostic Trouble Code Information Extended 773 : Unused 4";
BA_ "VNSigAllNodes" SG_ 1907 DTCIUnused4_773 1;
BA_ "SignalType" SG_ 1907 DTCIUnused3_773 "BLN";
BA_ "PacketOrder" SG_ 1907 DTCIUnused3_773 3;
BA_ "SignalLongName" SG_ 1907 DTCIUnused3_773 "Diagnostic Trouble Code Information Extended 773 : Unused 3";
BA_ "VNSigAllNodes" SG_ 1907 DTCIUnused3_773 1;
BA_ "SignalType" SG_ 1907 DTCIUnused2_773 "BLN";
BA_ "PacketOrder" SG_ 1907 DTCIUnused2_773 2;
BA_ "SignalLongName" SG_ 1907 DTCIUnused2_773 "Diagnostic Trouble Code Information Extended 773 : Unused 2";
BA_ "VNSigAllNodes" SG_ 1907 DTCIUnused2_773 1;
BA_ "SignalType" SG_ 1907 DTCIUnused1_773 "BLN";
BA_ "PacketOrder" SG_ 1907 DTCIUnused1_773 1;
BA_ "SignalLongName" SG_ 1907 DTCIUnused1_773 "Diagnostic Trouble Code Information Extended 773 : Unused 1";
BA_ "VNSigAllNodes" SG_ 1907 DTCIUnused1_773 1;
BA_ "VNSigSLHSSharedDiagnostic" SG_ 579 DgnInf 1;
BA_ "SignalType" SG_ 579 DgnInf "UNM";
BA_ "SignalLongName" SG_ 579 DgnInf "Diagnostic Information";
BA_ "VNSigAllNodes" SG_ 579 DgnInf 1;
BA_ "VNSigSLHSSharedDiagnostic" SG_ 1603 DgnInf 1;
BA_ "SignalType" SG_ 1603 DgnInf "UNM";
BA_ "SignalLongName" SG_ 1603 DgnInf "Diagnostic Information";
BA_ "VNSigAllNodes" SG_ 1603 DgnInf 1;
BA_ "VNSigSLHSSharedDiagnostic" SG_ 1347 DgnInf_HS543 1;
BA_ "SignalType" SG_ 1347 DgnInf_HS543 "UNM";
BA_ "SignalLongName" SG_ 1347 DgnInf_HS543 "Diagnostic Information HS543";
BA_ "VNSigAllNodes" SG_ 1347 DgnInf_HS543 1;
BA_ "SignalType" SG_ 1915 DTCI_DTCFaultType_77B "ENM";
BA_ "PacketOrder" SG_ 1915 DTCI_DTCFaultType_77B 20;
BA_ "SignalLongName" SG_ 1915 DTCI_DTCFaultType_77B "Diagnostic Trouble Code Information Extended 77B : Diagnostic Trouble Code Fault Type";
BA_ "VNSigAllNodes" SG_ 1915 DTCI_DTCFaultType_77B 1;
BA_ "SignalType" SG_ 1915 DTCI_CodeSupported_77B "BLN";
BA_ "PacketOrder" SG_ 1915 DTCI_CodeSupported_77B 19;
BA_ "SignalLongName" SG_ 1915 DTCI_CodeSupported_77B "Diagnostic Trouble Code Information Extended 77B : Code Supported";
BA_ "VNSigAllNodes" SG_ 1915 DTCI_CodeSupported_77B 1;
BA_ "SignalType" SG_ 1915 DTCI_CurrentStatus_77B "BLN";
BA_ "PacketOrder" SG_ 1915 DTCI_CurrentStatus_77B 18;
BA_ "SignalLongName" SG_ 1915 DTCI_CurrentStatus_77B "Diagnostic Trouble Code Information Extended 77B : Current Status";
BA_ "VNSigAllNodes" SG_ 1915 DTCI_CurrentStatus_77B 1;
BA_ "SignalType" SG_ 1915 DTCI_TstNPsdCdClrdSt_77B "BLN";
BA_ "PacketOrder" SG_ 1915 DTCI_TstNPsdCdClrdSt_77B 17;
BA_ "SignalLongName" SG_ 1915 DTCI_TstNPsdCdClrdSt_77B "Diagnostic Trouble Code Information Extended 77B : Test Not Passed Since Code Cleared Status";
BA_ "VNSigAllNodes" SG_ 1915 DTCI_TstNPsdCdClrdSt_77B 1;
BA_ "SignalType" SG_ 1915 DTCI_TstFldCdClrdStat_77B "BLN";
BA_ "PacketOrder" SG_ 1915 DTCI_TstFldCdClrdStat_77B 16;
BA_ "SignalLongName" SG_ 1915 DTCI_TstFldCdClrdStat_77B "Diagnostic Trouble Code Information Extended 77B : Test Failed Since Code Cleared Status";
BA_ "VNSigAllNodes" SG_ 1915 DTCI_TstFldCdClrdStat_77B 1;
BA_ "SignalType" SG_ 1915 DTCI_HistStat_77B "BLN";
BA_ "PacketOrder" SG_ 1915 DTCI_HistStat_77B 15;
BA_ "SignalLongName" SG_ 1915 DTCI_HistStat_77B "Diagnostic Trouble Code Information Extended 77B : History Status";
BA_ "VNSigAllNodes" SG_ 1915 DTCI_HistStat_77B 1;
BA_ "SignalType" SG_ 1915 DTCI_TstNPsdPwrUpSt_77B "BLN";
BA_ "PacketOrder" SG_ 1915 DTCI_TstNPsdPwrUpSt_77B 14;
BA_ "SignalLongName" SG_ 1915 DTCI_TstNPsdPwrUpSt_77B "Diagnostic Trouble Code Information Extended 77B : Test Not Passed Since Power Up Status";
BA_ "VNSigAllNodes" SG_ 1915 DTCI_TstNPsdPwrUpSt_77B 1;
BA_ "SignalType" SG_ 1915 DTCI_TstFldPwrUpSt_77B "BLN";
BA_ "PacketOrder" SG_ 1915 DTCI_TstFldPwrUpSt_77B 13;
BA_ "SignalLongName" SG_ 1915 DTCI_TstFldPwrUpSt_77B "Diagnostic Trouble Code Information Extended 77B : Test Failed Since Power Up Status";
BA_ "VNSigAllNodes" SG_ 1915 DTCI_TstFldPwrUpSt_77B 1;
BA_ "SignalType" SG_ 1915 DTCI_WrnIndRqdSt_77B "BLN";
BA_ "PacketOrder" SG_ 1915 DTCI_WrnIndRqdSt_77B 12;
BA_ "SignalLongName" SG_ 1915 DTCI_WrnIndRqdSt_77B "Diagnostic Trouble Code Information Extended 77B : Warning Indicator Requested Status";
BA_ "VNSigAllNodes" SG_ 1915 DTCI_WrnIndRqdSt_77B 1;
BA_ "SignalType" SG_ 1915 DTCI_DTCFailType_77B "UNM";
BA_ "PacketOrder" SG_ 1915 DTCI_DTCFailType_77B 11;
BA_ "SignalLongName" SG_ 1915 DTCI_DTCFailType_77B "Diagnostic Trouble Code Information Extended 77B : Diagnostic Trouble Code Failure Type";
BA_ "VNSigAllNodes" SG_ 1915 DTCI_DTCFailType_77B 1;
BA_ "SignalType" SG_ 1915 DTCI_DTCNumber_77B "UNM";
BA_ "PacketOrder" SG_ 1915 DTCI_DTCNumber_77B 10;
BA_ "SignalLongName" SG_ 1915 DTCI_DTCNumber_77B "Diagnostic Trouble Code Information Extended 77B : Diagnostic Trouble Code Number";
BA_ "VNSigAllNodes" SG_ 1915 DTCI_DTCNumber_77B 1;
BA_ "SignalType" SG_ 1915 DTCI_DTCSource_77B "UNM";
BA_ "PacketOrder" SG_ 1915 DTCI_DTCSource_77B 9;
BA_ "SignalLongName" SG_ 1915 DTCI_DTCSource_77B "Diagnostic Trouble Code Information Extended 77B : Diagnostic Trouble Code Source";
BA_ "VNSigAllNodes" SG_ 1915 DTCI_DTCSource_77B 1;
BA_ "SignalType" SG_ 1915 DTCI_DTCTriggered_77B "BLN";
BA_ "PacketOrder" SG_ 1915 DTCI_DTCTriggered_77B 8;
BA_ "SignalLongName" SG_ 1915 DTCI_DTCTriggered_77B "Diagnostic Trouble Code Information Extended 77B : Diagnostic Trouble Code Triggered";
BA_ "VNSigAllNodes" SG_ 1915 DTCI_DTCTriggered_77B 1;
BA_ "SignalType" SG_ 1915 DTCIUnused7_77B "BLN";
BA_ "PacketOrder" SG_ 1915 DTCIUnused7_77B 7;
BA_ "SignalLongName" SG_ 1915 DTCIUnused7_77B "Diagnostic Trouble Code Information Extended 77B : Unused 7";
BA_ "VNSigAllNodes" SG_ 1915 DTCIUnused7_77B 1;
BA_ "SignalType" SG_ 1915 DTCIUnused6_77B "BLN";
BA_ "PacketOrder" SG_ 1915 DTCIUnused6_77B 6;
BA_ "SignalLongName" SG_ 1915 DTCIUnused6_77B "Diagnostic Trouble Code Information Extended 77B : Unused 6";
BA_ "VNSigAllNodes" SG_ 1915 DTCIUnused6_77B 1;
BA_ "SignalType" SG_ 1915 DTCIUnused5_77B "BLN";
BA_ "PacketOrder" SG_ 1915 DTCIUnused5_77B 5;
BA_ "SignalLongName" SG_ 1915 DTCIUnused5_77B "Diagnostic Trouble Code Information Extended 77B : Unused 5";
BA_ "VNSigAllNodes" SG_ 1915 DTCIUnused5_77B 1;
BA_ "SignalType" SG_ 1915 DTCIUnused4_77B "BLN";
BA_ "PacketOrder" SG_ 1915 DTCIUnused4_77B 4;
BA_ "SignalLongName" SG_ 1915 DTCIUnused4_77B "Diagnostic Trouble Code Information Extended 77B : Unused 4";
BA_ "VNSigAllNodes" SG_ 1915 DTCIUnused4_77B 1;
BA_ "SignalType" SG_ 1915 DTCIUnused3_77B "BLN";
BA_ "PacketOrder" SG_ 1915 DTCIUnused3_77B 3;
BA_ "SignalLongName" SG_ 1915 DTCIUnused3_77B "Diagnostic Trouble Code Information Extended 77B : Unused 3";
BA_ "VNSigAllNodes" SG_ 1915 DTCIUnused3_77B 1;
BA_ "SignalType" SG_ 1915 DTCIUnused2_77B "BLN";
BA_ "PacketOrder" SG_ 1915 DTCIUnused2_77B 2;
BA_ "SignalLongName" SG_ 1915 DTCIUnused2_77B "Diagnostic Trouble Code Information Extended 77B : Unused 2";
BA_ "VNSigAllNodes" SG_ 1915 DTCIUnused2_77B 1;
BA_ "SignalType" SG_ 1915 DTCIUnused1_77B "BLN";
BA_ "PacketOrder" SG_ 1915 DTCIUnused1_77B 1;
BA_ "SignalLongName" SG_ 1915 DTCIUnused1_77B "Diagnostic Trouble Code Information Extended 77B : Unused 1";
BA_ "VNSigAllNodes" SG_ 1915 DTCIUnused1_77B 1;
BA_ "VNSigSLHSSharedDiagnostic" SG_ 587 DgnInf 1;
BA_ "SignalType" SG_ 587 DgnInf "UNM";
BA_ "SignalLongName" SG_ 587 DgnInf "Diagnostic Information";
BA_ "VNSigAllNodes" SG_ 587 DgnInf 1;
BA_ "VNSigSLHSSharedDiagnostic" SG_ 1611 DgnInf 1;
BA_ "SignalType" SG_ 1611 DgnInf "UNM";
BA_ "SignalLongName" SG_ 1611 DgnInf "Diagnostic Information";
BA_ "VNSigAllNodes" SG_ 1611 DgnInf 1;
BA_ "VNSigSLHSSharedDiagnostic" SG_ 1355 DgnInf_HS54B 1;
BA_ "SignalType" SG_ 1355 DgnInf_HS54B "UNM";
BA_ "SignalLongName" SG_ 1355 DgnInf_HS54B "Diagnostic Information HS54B";
BA_ "VNSigAllNodes" SG_ 1355 DgnInf_HS54B 1;
BA_ "SignalType" SG_ 880 FOAI_VehAhdIndRq "ENM";
BA_ "SignalLongName" SG_ 880 FOAI_VehAhdIndRq "Forward Object Alert Indications : Vehicle Ahead Indication Request";
BA_ "VNSigAllNodes" SG_ 880 FOAI_VehAhdIndRq 1;
BA_ "SignalType" SG_ 880 FOAI_AlrtWrnIndRq "ENM";
BA_ "SignalLongName" SG_ 880 FOAI_AlrtWrnIndRq "Forward Object Alert Indications : Alert Warning Indication Request";
BA_ "VNSigAllNodes" SG_ 880 FOAI_AlrtWrnIndRq 1;
BA_ "SignalType" SG_ 880 FOAI_AlrtChmIhbRq "ENM";
BA_ "SignalLongName" SG_ 880 FOAI_AlrtChmIhbRq "Forward Object Alert Indications : Alert Warning Chime Inhibit Request";
BA_ "VNSigAllNodes" SG_ 880 FOAI_AlrtChmIhbRq 1;
BA_ "SignalType" SG_ 880 FwdClnAlrtPr "BLN";
BA_ "SignalLongName" SG_ 880 FwdClnAlrtPr "Forward Collision Alert Present";
BA_ "VNSigAllNodes" SG_ 880 FwdClnAlrtPr 1;
BA_ "SignalType" SG_ 880 ACCUnavlbleDTWthrIO "BLN";
BA_ "SignalLongName" SG_ 880 ACCUnavlbleDTWthrIO "Adaptive Cruise Unavailable Due To Weather Indication On";
BA_ "VNSigAllNodes" SG_ 880 ACCUnavlbleDTWthrIO 1;
BA_ "SignalType" SG_ 880 ACCAct370 "BLN";
BA_ "SignalLongName" SG_ 880 ACCAct370 "Adaptive Cruise Control Active";
BA_ "VNSigAllNodes" SG_ 880 ACCAct370 1;
BA_ "SignalType" SG_ 880 DrvThrtlOvrdIO "BLN";
BA_ "SignalLongName" SG_ 880 DrvThrtlOvrdIO "Driver Throttle Override Indication On";
BA_ "VNSigAllNodes" SG_ 880 DrvThrtlOvrdIO 1;
BA_ "SignalType" SG_ 880 ServAdpCrsCtrlIndOn "BLN";
BA_ "SignalLongName" SG_ 880 ServAdpCrsCtrlIndOn "Service Adaptive Cruise Control Indication On";
BA_ "VNSigAllNodes" SG_ 880 ServAdpCrsCtrlIndOn 1;
BA_ "SignalType" SG_ 880 ACCDrvrSeltdSpd "UNM";
BA_ "SignalLongName" SG_ 880 ACCDrvrSeltdSpd "Adaptive Cruise Control Driver Selected Speed";
BA_ "VNSigAllNodes" SG_ 880 ACCDrvrSeltdSpd 1;
BA_ "SignalType" SG_ 880 ACCHdwayStngIO "BLN";
BA_ "SignalLongName" SG_ 880 ACCHdwayStngIO "Adaptive Cruise Control Headway Setting Indication On";
BA_ "VNSigAllNodes" SG_ 880 ACCHdwayStngIO 1;
BA_ "SignalType" SG_ 880 ACCHdwyStg "ENM";
BA_ "SignalLongName" SG_ 880 ACCHdwyStg "Adaptive Cruise Control Headway Setting";
BA_ "VNSigAllNodes" SG_ 880 ACCHdwyStg 1;
BA_ "SignalType" SG_ 880 ACCSnsClnRqdIO "BLN";
BA_ "SignalLongName" SG_ 880 ACCSnsClnRqdIO "Adaptive Cruise Control Sensor Cleaning Required Indication On";
BA_ "VNSigAllNodes" SG_ 880 ACCSnsClnRqdIO 1;
BA_ "SignalType" SG_ 880 ACCTmpUnavlbleIO "BLN";
BA_ "SignalLongName" SG_ 880 ACCTmpUnavlbleIO "Adaptive Cruise Control Temporarily Unavailable Indication On";
BA_ "VNSigAllNodes" SG_ 880 ACCTmpUnavlbleIO 1;
BA_ "SignalType" SG_ 880 ACCDrvrSeltdSpdIO "BLN";
BA_ "SignalLongName" SG_ 880 ACCDrvrSeltdSpdIO "Adaptive Cruise Control Driver Selected Speed Indication On";
BA_ "VNSigAllNodes" SG_ 880 ACCDrvrSeltdSpdIO 1;
BA_ "SignalType" SG_ 894 RtLwBmFld "BLN";
BA_ "SignalLongName" SG_ 894 RtLwBmFld "Right Low Beam Failed";
BA_ "VNSigAllNodes" SG_ 894 RtLwBmFld 1;
BA_ "SignalType" SG_ 894 LftLwBmFld "BLN";
BA_ "SignalLongName" SG_ 894 LftLwBmFld "Left Low Beam Failed";
BA_ "VNSigAllNodes" SG_ 894 LftLwBmFld 1;
BA_ "SignalType" SG_ 894 AdvFrntLghtSysIndRq "ENM";
BA_ "SignalLongName" SG_ 894 AdvFrntLghtSysIndRq "Advanced Front Lighting System Indication Request";
BA_ "VNSigAllNodes" SG_ 894 AdvFrntLghtSysIndRq 1;
BA_ "SignalType" SG_ 894 HdLtLvlFlrIO "BLN";
BA_ "SignalLongName" SG_ 894 HdLtLvlFlrIO "Head Light Leveling Failure Indication On";
BA_ "VNSigAllNodes" SG_ 894 HdLtLvlFlrIO 1;
BA_ "VNSigSLHSSharedDiagnostic" SG_ 577 DgnInf 1;
BA_ "SignalType" SG_ 577 DgnInf "UNM";
BA_ "SignalLongName" SG_ 577 DgnInf "Diagnostic Information";
BA_ "VNSigAllNodes" SG_ 577 DgnInf 1;
BA_ "SignalType" SG_ 298 SpdLmtrSttngTyp "ENM";
BA_ "SignalLongName" SG_ 298 SpdLmtrSttngTyp "Speed Limiter Setting Type";
BA_ "VNSigAllNodes" SG_ 298 SpdLmtrSttngTyp 1;
BA_ "SignalType" SG_ 298 TCSysDisSwAtv "BLN";
BA_ "SignalLongName" SG_ 298 TCSysDisSwAtv "Traction Control System Disable Switch Active";
BA_ "VNSigAllNodes" SG_ 298 TCSysDisSwAtv 1;
BA_ "SignalType" SG_ 298 AutoMdSpdLmtCnfrmd "BLN";
BA_ "SignalLongName" SG_ 298 AutoMdSpdLmtCnfrmd "Auto Mode Speed Limit Confirmed";
BA_ "VNSigAllNodes" SG_ 298 AutoMdSpdLmtCnfrmd 1;
BA_ "SignalType" SG_ 298 TCSysDisSwAtvARC "UNM";
BA_ "SignalLongName" SG_ 298 TCSysDisSwAtvARC "Traction Control System Disable Switch Active Alive Rolling Count";
BA_ "VNSigAllNodes" SG_ 298 TCSysDisSwAtvARC 1;
BA_ "SignalType" SG_ 298 ChmAct "BLN";
BA_ "SignalLongName" SG_ 298 ChmAct "Chime Active";
BA_ "VNSigAllNodes" SG_ 298 ChmAct 1;
BA_ "SignalType" SG_ 298 DDAjrSwAtvM "ENM";
BA_ "SignalLongName" SG_ 298 DDAjrSwAtvM "Driver Door Ajar Switch Active Mask";
BA_ "VNSigAllNodes" SG_ 298 DDAjrSwAtvM 1;
BA_ "SignalType" SG_ 298 CrshAlrtDrvrSlctdType "ENM";
BA_ "SignalLongName" SG_ 298 CrshAlrtDrvrSlctdType "Crash Alert Driver Selected Type";
BA_ "VNSigAllNodes" SG_ 298 CrshAlrtDrvrSlctdType 1;
BA_ "SignalType" SG_ 298 PsSbltAtcV "ENM";
BA_ "SignalLongName" SG_ 298 PsSbltAtcV "Passenger Seatbelt Attached Validity";
BA_ "VNSigAllNodes" SG_ 298 PsSbltAtcV 1;
BA_ "SignalType" SG_ 298 PsSbltAtc "BLN";
BA_ "SignalLongName" SG_ 298 PsSbltAtc "Passenger Seatbelt Attached";
BA_ "VNSigAllNodes" SG_ 298 PsSbltAtc 1;
BA_ "SignalType" SG_ 298 TrlrBrkDsplyAct "BLN";
BA_ "SignalLongName" SG_ 298 TrlrBrkDsplyAct "Trailer Brake Display Active";
BA_ "VNSigAllNodes" SG_ 298 TrlrBrkDsplyAct 1;
BA_ "SignalType" SG_ 298 RdSpdCatType "ENM";
BA_ "SignalLongName" SG_ 298 RdSpdCatType "Road Speed Category Type";
BA_ "VNSigAllNodes" SG_ 298 RdSpdCatType 1;
BA_ "SignalType" SG_ 298 LnCat "ENM";
BA_ "SignalLongName" SG_ 298 LnCat "Lane Category";
BA_ "VNSigAllNodes" SG_ 298 LnCat 1;
BA_ "SignalType" SG_ 298 FncRdClass "ENM";
BA_ "SignalLongName" SG_ 298 FncRdClass "Functional Road Class";
BA_ "VNSigAllNodes" SG_ 298 FncRdClass 1;
BA_ "SignalType" SG_ 298 SprtLnRd "BLN";
BA_ "SignalLongName" SG_ 298 SprtLnRd "Separate Lane Road";
BA_ "VNSigAllNodes" SG_ 298 SprtLnRd 1;
BA_ "SignalType" SG_ 298 CntrldAccRd "BLN";
BA_ "SignalLongName" SG_ 298 CntrldAccRd "Controlled Access Road";
BA_ "VNSigAllNodes" SG_ 298 CntrldAccRd 1;
BA_ "SignalType" SG_ 298 BldUpArDet "BLN";
BA_ "SignalLongName" SG_ 298 BldUpArDet "Build Up Area Detected";
BA_ "VNSigAllNodes" SG_ 298 BldUpArDet 1;
BA_ "SignalType" SG_ 298 MpDataAvlbl "BLN";
BA_ "SignalLongName" SG_ 298 MpDataAvlbl "Map Data Available";
BA_ "VNSigAllNodes" SG_ 298 MpDataAvlbl 1;
BA_ "SignalType" SG_ 298 SusCustStngReq "ENM";
BA_ "SignalLongName" SG_ 298 SusCustStngReq "Suspension Customization Setting Request";
BA_ "VNSigAllNodes" SG_ 298 SusCustStngReq 1;
BA_ "SignalType" SG_ 298 StrCustStngReq "ENM";
BA_ "SignalLongName" SG_ 298 StrCustStngReq "Steering Customization Setting Request";
BA_ "VNSigAllNodes" SG_ 298 StrCustStngReq 1;
BA_ "SignalType" SG_ 298 RstrCustFctrDef "ENM";
BA_ "SignalLongName" SG_ 298 RstrCustFctrDef "Restore Customization Factory Defaults";
BA_ "VNSigAllNodes" SG_ 298 RstrCustFctrDef 1;
BA_ "SignalType" SG_ 298 DrvlnCustStngReq "ENM";
BA_ "SignalLongName" SG_ 298 DrvlnCustStngReq "Driveline Customization Setting Request";
BA_ "VNSigAllNodes" SG_ 298 DrvlnCustStngReq 1;
BA_ "SignalType" SG_ 298 ChmMstrVDA "ENM";
BA_ "SignalLongName" SG_ 298 ChmMstrVDA "Chime Master Virtual Device Availability";
BA_ "GenSigStartValue" SG_ 298 ChmMstrVDA 1;
BA_ "VNSigAllNodes" SG_ 298 ChmMstrVDA 1;
BA_ "SignalType" SG_ 298 IPCVDA "ENM";
BA_ "SignalLongName" SG_ 298 IPCVDA "Instrument Panel Cluster Virtual Device Availability";
BA_ "GenSigStartValue" SG_ 298 IPCVDA 1;
BA_ "VNSigAllNodes" SG_ 298 IPCVDA 1;
BA_ "SignalType" SG_ 298 HeadUpDispVDA "ENM";
BA_ "SignalLongName" SG_ 298 HeadUpDispVDA "Head Up Display Virtual Device Availability";
BA_ "GenSigStartValue" SG_ 298 HeadUpDispVDA 1;
BA_ "VNSigAllNodes" SG_ 298 HeadUpDispVDA 1;
BA_ "SignalType" SG_ 298 HapticSeatVDA "ENM";
BA_ "SignalLongName" SG_ 298 HapticSeatVDA "Haptic Seat Virtual Device Availability";
BA_ "GenSigStartValue" SG_ 298 HapticSeatVDA 1;
BA_ "VNSigAllNodes" SG_ 298 HapticSeatVDA 1;
BA_ "SignalType" SG_ 298 RRDoorAjarSwAct "BLN";
BA_ "SignalLongName" SG_ 298 RRDoorAjarSwAct "Rear Right Door Ajar Switch Active";
BA_ "VNSigAllNodes" SG_ 298 RRDoorAjarSwAct 1;
BA_ "SignalType" SG_ 298 PDAjrSwAtv "BLN";
BA_ "SignalLongName" SG_ 298 PDAjrSwAtv "Passenger Door Ajar Switch Active";
BA_ "VNSigAllNodes" SG_ 298 PDAjrSwAtv 1;
BA_ "SignalType" SG_ 298 DDAjrSwAtv "BLN";
BA_ "SignalLongName" SG_ 298 DDAjrSwAtv "Driver Door Ajar Switch Active";
BA_ "VNSigAllNodes" SG_ 298 DDAjrSwAtv 1;
BA_ "SignalType" SG_ 298 TrlrHWIntrfcVDA "ENM";
BA_ "SignalLongName" SG_ 298 TrlrHWIntrfcVDA "Trailer Hardware Interface Virtual Device Availability";
BA_ "GenSigStartValue" SG_ 298 TrlrHWIntrfcVDA 1;
BA_ "VNSigAllNodes" SG_ 298 TrlrHWIntrfcVDA 1;
BA_ "SignalType" SG_ 298 DrId "ENM";
BA_ "SignalLongName" SG_ 298 DrId "Driver Identifier";
BA_ "GenSigStartValue" SG_ 298 DrId 7;
BA_ "VNSigAllNodes" SG_ 298 DrId 1;
BA_ "SignalType" SG_ 298 EnrgMgtLdShdRq "ENM";
BA_ "SignalLongName" SG_ 298 EnrgMgtLdShdRq "Energy Management Load Shedding Request";
BA_ "VNSigAllNodes" SG_ 298 EnrgMgtLdShdRq 1;
BA_ "SignalType" SG_ 298 DrSbltAtcV "ENM";
BA_ "SignalLongName" SG_ 298 DrSbltAtcV "Driver Seatbelt Attached Validity";
BA_ "VNSigAllNodes" SG_ 298 DrSbltAtcV 1;
BA_ "SignalType" SG_ 298 TrlrHtchSwAtv "BLN";
BA_ "SignalLongName" SG_ 298 TrlrHtchSwAtv "Trailer Hitch Switch Active";
BA_ "VNSigAllNodes" SG_ 298 TrlrHtchSwAtv 1;
BA_ "SignalType" SG_ 298 TreInfMonSysRstReq "BLN";
BA_ "SignalLongName" SG_ 298 TreInfMonSysRstReq "Tire Inflation Monitoring System Reset Requested";
BA_ "VNSigAllNodes" SG_ 298 TreInfMonSysRstReq 1;
BA_ "SignalType" SG_ 298 HUDActv "BLN";
BA_ "SignalLongName" SG_ 298 HUDActv "Head Up Display Active";
BA_ "VNSigAllNodes" SG_ 298 HUDActv 1;
BA_ "SignalType" SG_ 298 BatVltV "ENM";
BA_ "SignalLongName" SG_ 298 BatVltV "Battery Voltage Validity";
BA_ "VNSigAllNodes" SG_ 298 BatVltV 1;
BA_ "SignalType" SG_ 298 BatVlt "UNM";
BA_ "SignalLongName" SG_ 298 BatVlt "Battery Voltage";
BA_ "VNSigAllNodes" SG_ 298 BatVlt 1;
BA_ "SignalType" SG_ 298 RLDoorAjarSwAct "BLN";
BA_ "SignalLongName" SG_ 298 RLDoorAjarSwAct "Rear Left Door Ajar Switch Active";
BA_ "VNSigAllNodes" SG_ 298 RLDoorAjarSwAct 1;
BA_ "SignalType" SG_ 298 DrSbltAtc "BLN";
BA_ "SignalLongName" SG_ 298 DrSbltAtc "Driver Seatbelt Attached";
BA_ "VNSigAllNodes" SG_ 298 DrSbltAtc 1;
BA_ "SignalType" SG_ 1322 TireRRPrsV "ENM";
BA_ "SignalLongName" SG_ 1322 TireRRPrsV "Tire Right Rear Pressure Validity";
BA_ "VNSigAllNodes" SG_ 1322 TireRRPrsV 1;
BA_ "SignalType" SG_ 1322 TireRRPrsStat "ENM";
BA_ "SignalLongName" SG_ 1322 TireRRPrsStat "Tire Right Rear Pressure Status";
BA_ "VNSigAllNodes" SG_ 1322 TireRRPrsStat 1;
BA_ "SignalType" SG_ 1322 TireRRPrs "UNM";
BA_ "SignalLongName" SG_ 1322 TireRRPrs "Tire Right Rear Pressure";
BA_ "GenSigStartValue" SG_ 1322 TireRRPrs 255;
BA_ "VNSigAllNodes" SG_ 1322 TireRRPrs 1;
BA_ "SignalType" SG_ 1322 TireRFPrsV "ENM";
BA_ "SignalLongName" SG_ 1322 TireRFPrsV "Tire Right Front Pressure Validity";
BA_ "VNSigAllNodes" SG_ 1322 TireRFPrsV 1;
BA_ "SignalType" SG_ 1322 TireRFPrsStat "ENM";
BA_ "SignalLongName" SG_ 1322 TireRFPrsStat "Tire Right Front Pressure Status";
BA_ "VNSigAllNodes" SG_ 1322 TireRFPrsStat 1;
BA_ "SignalType" SG_ 1322 TireRFPrs "UNM";
BA_ "SignalLongName" SG_ 1322 TireRFPrs "Tire Right Front Pressure";
BA_ "GenSigStartValue" SG_ 1322 TireRFPrs 255;
BA_ "VNSigAllNodes" SG_ 1322 TireRFPrs 1;
BA_ "SignalType" SG_ 1322 TireLRPrsV "ENM";
BA_ "SignalLongName" SG_ 1322 TireLRPrsV "Tire Left Rear Pressure Validity";
BA_ "VNSigAllNodes" SG_ 1322 TireLRPrsV 1;
BA_ "SignalType" SG_ 1322 TireLRPrsStat "ENM";
BA_ "SignalLongName" SG_ 1322 TireLRPrsStat "Tire Left Rear Pressure Status";
BA_ "VNSigAllNodes" SG_ 1322 TireLRPrsStat 1;
BA_ "SignalType" SG_ 1322 TireLRPrs "UNM";
BA_ "SignalLongName" SG_ 1322 TireLRPrs "Tire Left Rear Pressure";
BA_ "GenSigStartValue" SG_ 1322 TireLRPrs 255;
BA_ "VNSigAllNodes" SG_ 1322 TireLRPrs 1;
BA_ "SignalType" SG_ 1322 TireLFPrsV "ENM";
BA_ "SignalLongName" SG_ 1322 TireLFPrsV "Tire Left Front Pressure Validity";
BA_ "VNSigAllNodes" SG_ 1322 TireLFPrsV 1;
BA_ "SignalType" SG_ 1322 TireLFPrsStat "ENM";
BA_ "SignalLongName" SG_ 1322 TireLFPrsStat "Tire Left Front Pressure Status";
BA_ "VNSigAllNodes" SG_ 1322 TireLFPrsStat 1;
BA_ "SignalType" SG_ 1322 TireLFPrs "UNM";
BA_ "SignalLongName" SG_ 1322 TireLFPrs "Tire Left Front Pressure";
BA_ "GenSigStartValue" SG_ 1322 TireLFPrs 255;
BA_ "VNSigAllNodes" SG_ 1322 TireLFPrs 1;
BA_ "VNSigSLHSSharedDiagnostic" SG_ 1601 DgnInf 1;
BA_ "SignalType" SG_ 1601 DgnInf "UNM";
BA_ "SignalLongName" SG_ 1601 DgnInf "Diagnostic Information";
BA_ "VNSigAllNodes" SG_ 1601 DgnInf 1;
BA_ "VNSigSLHSSharedDiagnostic" SG_ 2018 DgnInf 1;
BA_ "SignalType" SG_ 2018 DgnInf "UNM";
BA_ "SignalLongName" SG_ 2018 DgnInf "Diagnostic Information";
BA_ "VNSigAllNodes" SG_ 2018 DgnInf 1;
BA_ "VNSigSLHSSharedDiagnostic" SG_ 2026 DgnInf 1;
BA_ "SignalType" SG_ 2026 DgnInf "UNM";
BA_ "SignalLongName" SG_ 2026 DgnInf "Diagnostic Information";
BA_ "VNSigAllNodes" SG_ 2026 DgnInf 1;
BA_ "VNSigSLHSSharedDiagnostic" SG_ 1514 DgnInf 1;
BA_ "SignalType" SG_ 1514 DgnInf "UNM";
BA_ "SignalLongName" SG_ 1514 DgnInf "Diagnostic Information";
BA_ "VNSigAllNodes" SG_ 1514 DgnInf 1;
BA_ "SignalType" SG_ 1300 VehIdNmDig2_9 "ASC";
BA_ "SignalLongName" SG_ 1300 VehIdNmDig2_9 "Vehicle Identification Number Digits 2-9";
BA_ "VNSigAllNodes" SG_ 1300 VehIdNmDig2_9 1;
BA_ "SignalType" SG_ 288 VehOdo "UNM";
BA_ "SignalLongName" SG_ 288 VehOdo "Vehicle Odometer";
BA_ "VNSigAllNodes" SG_ 288 VehOdo 1;
BA_ "SignalType" SG_ 288 VehOdoV "ENM";
BA_ "SignalLongName" SG_ 288 VehOdoV "Vehicle Odometer Validity";
BA_ "VNSigAllNodes" SG_ 288 VehOdoV 1;
BA_ "VNSigSLHSSharedDiagnostic" SG_ 2020 DgnInf 1;
BA_ "SignalType" SG_ 2020 DgnInf "UNM";
BA_ "SignalLongName" SG_ 2020 DgnInf "Diagnostic Information";
BA_ "VNSigAllNodes" SG_ 2020 DgnInf 1;
BA_ "VNSigSLHSSharedDiagnostic" SG_ 2028 DgnInf 1;
BA_ "SignalType" SG_ 2028 DgnInf "UNM";
BA_ "SignalLongName" SG_ 2028 DgnInf "Diagnostic Information";
BA_ "VNSigAllNodes" SG_ 2028 DgnInf 1;
BA_ "VNSigSLHSSharedDiagnostic" SG_ 1516 DgnInf 1;
BA_ "SignalType" SG_ 1516 DgnInf "UNM";
BA_ "SignalLongName" SG_ 1516 DgnInf "Diagnostic Information";
BA_ "VNSigAllNodes" SG_ 1516 DgnInf 1;
BA_ "SignalType" SG_ 485 StrAngSnsChksm "UNM";
BA_ "SignalLongName" SG_ 485 StrAngSnsChksm "Steering Angle Sensor Checksum";
BA_ "VNSigAllNodes" SG_ 485 StrAngSnsChksm 1;
BA_ "SignalType" SG_ 485 StrWhAngGrdV "ENM";
BA_ "SignalLongName" SG_ 485 StrWhAngGrdV "Steering Wheel Angle Gradient Validity";
BA_ "VNSigAllNodes" SG_ 485 StrWhAngGrdV 1;
BA_ "SignalType" SG_ 485 StrWhAngGrdMsk "ENM";
BA_ "SignalLongName" SG_ 485 StrWhAngGrdMsk "Steering Wheel Angle Gradient Mask";
BA_ "VNSigAllNodes" SG_ 485 StrWhAngGrdMsk 1;
BA_ "SignalType" SG_ 485 StrWhAngMsk "ENM";
BA_ "SignalLongName" SG_ 485 StrWhAngMsk "Steering Wheel Angle Mask";
BA_ "VNSigAllNodes" SG_ 485 StrWhAngMsk 1;
BA_ "SignalType" SG_ 485 StrWhlAngSenTyp "ENM";
BA_ "SignalLongName" SG_ 485 StrWhlAngSenTyp "Steering Wheel Angle Sensor Type";
BA_ "VNSigAllNodes" SG_ 485 StrWhlAngSenTyp 1;
BA_ "SignalType" SG_ 485 StrWhlAngSenCalStat "ENM";
BA_ "SignalLongName" SG_ 485 StrWhlAngSenCalStat "Steering Wheel Angle Sensor Calibration Status";
BA_ "VNSigAllNodes" SG_ 485 StrWhlAngSenCalStat 1;
BA_ "SignalType" SG_ 485 StrWhAngGrd "SNM";
BA_ "SignalLongName" SG_ 485 StrWhAngGrd "Steering Wheel Angle Gradient";
BA_ "VNSigAllNodes" SG_ 485 StrWhAngGrd 1;
BA_ "SignalType" SG_ 485 StWhlAngAliveRollCnt "UNM";
BA_ "SignalLongName" SG_ 485 StWhlAngAliveRollCnt "Steering Wheel Angle Alive Rolling Count";
BA_ "VNSigAllNodes" SG_ 485 StWhlAngAliveRollCnt 1;
BA_ "SignalType" SG_ 485 StrWhAngV "ENM";
BA_ "SignalLongName" SG_ 485 StrWhAngV "Steering Wheel Angle Validity";
BA_ "VNSigAllNodes" SG_ 485 StrWhAngV 1;
BA_ "SignalType" SG_ 485 StrWhAng "SNM";
BA_ "SignalLongName" SG_ 485 StrWhAng "Steering Wheel Angle";
BA_ "VNSigAllNodes" SG_ 485 StrWhAng 1;
BA_ "SignalType" SG_ 1001 DistRollCntAvgDrvnSrc "ENM";
BA_ "SignalLongName" SG_ 1001 DistRollCntAvgDrvnSrc "Distance Rolling Count Average Driven Source";
BA_ "VNSigAllNodes" SG_ 1001 DistRollCntAvgDrvnSrc 1;
BA_ "SignalType" SG_ 1001 VehSpdAvgDrvnSrc "ENM";
BA_ "SignalLongName" SG_ 1001 VehSpdAvgDrvnSrc "Vehicle Speed Average Driven Source";
BA_ "VNSigAllNodes" SG_ 1001 VehSpdAvgDrvnSrc 1;
BA_ "SignalType" SG_ 1001 DstRolCntAvgNonDrvnV "ENM";
BA_ "SignalLongName" SG_ 1001 DstRolCntAvgNonDrvnV "Distance Rolling Count Average Non Driven Validity";
BA_ "VNSigAllNodes" SG_ 1001 DstRolCntAvgNonDrvnV 1;
BA_ "SignalType" SG_ 1001 DstRolCntAvNDrRstOc "BLN";
BA_ "SignalLongName" SG_ 1001 DstRolCntAvNDrRstOc "Distance Rolling Count Average Non Driven Reset Occurred";
BA_ "VNSigAllNodes" SG_ 1001 DstRolCntAvNDrRstOc 1;
BA_ "SignalType" SG_ 1001 DstRolCntAvgNonDrvn "UNM";
BA_ "SignalLongName" SG_ 1001 DstRolCntAvgNonDrvn "Distance Rolling Count Average Non Driven";
BA_ "VNSigAllNodes" SG_ 1001 DstRolCntAvgNonDrvn 1;
BA_ "SignalType" SG_ 1001 DistRollCntAvgDrvnV "ENM";
BA_ "SignalLongName" SG_ 1001 DistRollCntAvgDrvnV "Distance Rolling Count Average Driven Validity";
BA_ "VNSigAllNodes" SG_ 1001 DistRollCntAvgDrvnV 1;
BA_ "SignalType" SG_ 1001 DstRolCntAvgDrnRstOc "BLN";
BA_ "SignalLongName" SG_ 1001 DstRolCntAvgDrnRstOc "Distance Rolling Count Average Driven Reset Occurred";
BA_ "VNSigAllNodes" SG_ 1001 DstRolCntAvgDrnRstOc 1;
BA_ "SignalType" SG_ 1001 DistRollCntAvgDrvn "UNM";
BA_ "SignalLongName" SG_ 1001 DistRollCntAvgDrvn "Distance Rolling Count Average Driven";
BA_ "VNSigAllNodes" SG_ 1001 DistRollCntAvgDrvn 1;
BA_ "SignalType" SG_ 1001 VehSpdAvgNDrvnV "ENM";
BA_ "SignalLongName" SG_ 1001 VehSpdAvgNDrvnV "Vehicle Speed Average Non Driven Validity";
BA_ "VNSigAllNodes" SG_ 1001 VehSpdAvgNDrvnV 1;
BA_ "SignalType" SG_ 1001 VehSpdAvgNDrvn "UNM";
BA_ "SignalLongName" SG_ 1001 VehSpdAvgNDrvn "Vehicle Speed Average Non Driven";
BA_ "VNSigAllNodes" SG_ 1001 VehSpdAvgNDrvn 1;
BA_ "SignalType" SG_ 1001 VehSpdAvgDrvnV "ENM";
BA_ "SignalLongName" SG_ 1001 VehSpdAvgDrvnV "Vehicle Speed Average Driven Validity";
BA_ "VNSigAllNodes" SG_ 1001 VehSpdAvgDrvnV 1;
BA_ "SignalType" SG_ 1001 VehSpdAvgDrvn "UNM";
BA_ "SignalLongName" SG_ 1001 VehSpdAvgDrvn "Vehicle Speed Average Driven";
BA_ "VNSigAllNodes" SG_ 1001 VehSpdAvgDrvn 1;
BA_ "SignalType" SG_ 961 PTImmblzerInfo "UNM";
BA_ "SignalLongName" SG_ 961 PTImmblzerInfo "Powertrain Immobilizer Information";
BA_ "VNSigAllNodes" SG_ 961 PTImmblzerInfo 1;
BA_ "SignalType" SG_ 804 CompOvrhtIndOn "BLN";
BA_ "SignalLongName" SG_ 804 CompOvrhtIndOn "Compressor Overheated Indication On";
BA_ "VNSigAllNodes" SG_ 804 CompOvrhtIndOn 1;
BA_ "SignalType" SG_ 804 VehHghtStatV "ENM";
BA_ "SignalLongName" SG_ 804 VehHghtStatV "Vehicle Height Status Validity";
BA_ "VNSigAllNodes" SG_ 804 VehHghtStatV 1;
BA_ "SignalType" SG_ 804 VehHghtStat "ENM";
BA_ "SignalLongName" SG_ 804 VehHghtStat "Vehicle Height Status";
BA_ "VNSigAllNodes" SG_ 804 VehHghtStat 1;
BA_ "SignalType" SG_ 804 SrvLevSysIO "BLN";
BA_ "SignalLongName" SG_ 804 SrvLevSysIO "Service Leveling System Indication On";
BA_ "VNSigAllNodes" SG_ 804 SrvLevSysIO 1;
BA_ "SignalType" SG_ 804 LevSysVehTopSpdLim "UNM";
BA_ "SignalLongName" SG_ 804 LevSysVehTopSpdLim "Leveling System Vehicle Top Speed Limit Value";
BA_ "VNSigAllNodes" SG_ 804 LevSysVehTopSpdLim 1;
BA_ "SignalType" SG_ 804 VehOvrLdIndOn "BLN";
BA_ "SignalLongName" SG_ 804 VehOvrLdIndOn "Vehicle Overloaded Indication On";
BA_ "VNSigAllNodes" SG_ 804 VehOvrLdIndOn 1;
BA_ "SignalType" SG_ 842 WhlRotDrctnlSRtNDrvn "ENM";
BA_ "SignalLongName" SG_ 842 WhlRotDrctnlSRtNDrvn "Wheel Rotational Directional Status Right Non Driven";
BA_ "VNSigAllNodes" SG_ 842 WhlRotDrctnlSRtNDrvn 1;
BA_ "SignalType" SG_ 842 WhlRotDrctnlStLfNDrvn "ENM";
BA_ "SignalLongName" SG_ 842 WhlRotDrctnlStLfNDrvn "Wheel Rotational Directional Status Left Non Driven";
BA_ "VNSigAllNodes" SG_ 842 WhlRotDrctnlStLfNDrvn 1;
BA_ "SignalType" SG_ 842 WhlGrndVlctyRtNnDrvnV "ENM";
BA_ "SignalLongName" SG_ 842 WhlGrndVlctyRtNnDrvnV "Wheel Ground Velocity Right Non Driven Validity";
BA_ "VNSigAllNodes" SG_ 842 WhlGrndVlctyRtNnDrvnV 1;
BA_ "SignalType" SG_ 842 WhlGrndVlctyRtNnDrvn "UNM";
BA_ "SignalLongName" SG_ 842 WhlGrndVlctyRtNnDrvn "Wheel Ground Velocity Right Non Driven";
BA_ "VNSigAllNodes" SG_ 842 WhlGrndVlctyRtNnDrvn 1;
BA_ "SignalType" SG_ 842 WhlGrndVlctyLftNnDrvnV "ENM";
BA_ "SignalLongName" SG_ 842 WhlGrndVlctyLftNnDrvnV "Wheel Ground Velocity Left Non Driven Validity";
BA_ "VNSigAllNodes" SG_ 842 WhlGrndVlctyLftNnDrvnV 1;
BA_ "SignalType" SG_ 842 WhlGrndVlctyLftNnDrvn "UNM";
BA_ "SignalLongName" SG_ 842 WhlGrndVlctyLftNnDrvn "Wheel Ground Velocity Left Non Driven";
BA_ "VNSigAllNodes" SG_ 842 WhlGrndVlctyLftNnDrvn 1;
BA_ "SignalType" SG_ 1241 FSERDTC_CdNum "UNM";
BA_ "PacketOrder" SG_ 1241 FSERDTC_CdNum 2;
BA_ "SignalLongName" SG_ 1241 FSERDTC_CdNum "Fuel System Emissions Related DTC : Code Number";
BA_ "VNSigAllNodes" SG_ 1241 FSERDTC_CdNum 1;
BA_ "SignalType" SG_ 1241 FSERDTC_SysDes "ENM";
BA_ "PacketOrder" SG_ 1241 FSERDTC_SysDes 1;
BA_ "SignalLongName" SG_ 1241 FSERDTC_SysDes "Fuel System Emissions Related DTC : System Designator";
BA_ "VNSigAllNodes" SG_ 1241 FSERDTC_SysDes 1;
BA_ "SignalType" SG_ 1241 FuelSysEmsRldMlfAtv "BLN";
BA_ "SignalLongName" SG_ 1241 FuelSysEmsRldMlfAtv "Fuel System Emissions Related Malfunction Active";
BA_ "VNSigAllNodes" SG_ 1241 FuelSysEmsRldMlfAtv 1;
BA_ "SignalType" SG_ 491 ExhPrsRgVlv2Pos "ENM";
BA_ "SignalLongName" SG_ 491 ExhPrsRgVlv2Pos "Exhaust Pressure Regulator Valve 2 Position";
BA_ "VNSigAllNodes" SG_ 491 ExhPrsRgVlv2Pos 1;
BA_ "SignalType" SG_ 491 ExhPrsRgVlv2PosV "ENM";
BA_ "SignalLongName" SG_ 491 ExhPrsRgVlv2PosV "Exhaust Pressure Regulator Valve 2 Position Validity";
BA_ "VNSigAllNodes" SG_ 491 ExhPrsRgVlv2PosV 1;
BA_ "SignalType" SG_ 491 ExhPrsRgVlvPosV "ENM";
BA_ "SignalLongName" SG_ 491 ExhPrsRgVlvPosV "Exhaust Pressure Regulator Valve Position Validity";
BA_ "VNSigAllNodes" SG_ 491 ExhPrsRgVlvPosV 1;
BA_ "SignalType" SG_ 491 ExhPrsRgVlvPos "ENM";
BA_ "SignalLongName" SG_ 491 ExhPrsRgVlvPos "Exhaust Pressure Regulator Valve Position";
BA_ "VNSigAllNodes" SG_ 491 ExhPrsRgVlvPos 1;
BA_ "SignalType" SG_ 491 FuelSysEstPressDlvrd "UNM";
BA_ "SignalLongName" SG_ 491 FuelSysEstPressDlvrd "Fuel System Estimated Pressure Delivered";
BA_ "VNSigAllNodes" SG_ 491 FuelSysEstPressDlvrd 1;
BA_ "SignalType" SG_ 491 FuelSysEstPressDlvrdV "ENM";
BA_ "SignalLongName" SG_ 491 FuelSysEstPressDlvrdV "Fuel System Estimated Pressure Delivered Validity";
BA_ "VNSigAllNodes" SG_ 491 FuelSysEstPressDlvrdV 1;
BA_ "SignalType" SG_ 1019 FuelAlchlCompAdptnPrg "BLN";
BA_ "SignalLongName" SG_ 1019 FuelAlchlCompAdptnPrg "Fuel Alcohol Composition Adaptation in Progress";
BA_ "VNSigAllNodes" SG_ 1019 FuelAlchlCompAdptnPrg 1;
BA_ "SignalType" SG_ 1019 FuelLvlEmnsRelStat "ENM";
BA_ "SignalLongName" SG_ 1019 FuelLvlEmnsRelStat "Fuel Level Emissions Related Status";
BA_ "VNSigAllNodes" SG_ 1019 FuelLvlEmnsRelStat 1;
BA_ "SignalType" SG_ 1019 EmnsRelFuelLvlLw "BLN";
BA_ "SignalLongName" SG_ 1019 EmnsRelFuelLvlLw "Emissions Related Fuel Level Low";
BA_ "VNSigAllNodes" SG_ 1019 EmnsRelFuelLvlLw 1;
BA_ "SignalType" SG_ 1019 EngFuelCntlState "ENM";
BA_ "SignalLongName" SG_ 1019 EngFuelCntlState "Engine Fuel Control State";
BA_ "VNSigAllNodes" SG_ 1019 EngFuelCntlState 1;
BA_ "SignalType" SG_ 1019 FuelAlcoholCompV "ENM";
BA_ "SignalLongName" SG_ 1019 FuelAlcoholCompV "Fuel Alcohol Composition Validity";
BA_ "VNSigAllNodes" SG_ 1019 FuelAlcoholCompV 1;
BA_ "SignalType" SG_ 1019 FuelAlcoholComp "UNM";
BA_ "SignalLongName" SG_ 1019 FuelAlcoholComp "Fuel Alcohol Composition";
BA_ "VNSigAllNodes" SG_ 1019 FuelAlcoholComp 1;
BA_REL_ "GenSigRxStartValue" BU_SG_REL_ TCM_HS SG_ 499 PTShftPtrnOvrdAct "False";
BA_REL_ "GenSigRxStartValue" BU_SG_REL_ TCM_HS SG_ 499 PFTrnsTUDSecSwSt "$0 - No Activation";
BA_REL_ "GenSigRxStartValue" BU_SG_REL_ PCM_HS SG_ 499 TrnsPFShftPattSw4Act "False";
BA_REL_ "GenSigRxStartValue" BU_SG_REL_ ECM_HS SG_ 499 TrnsPFShftPattSw4Act "False";
BA_REL_ "GenSigRxStartValue" BU_SG_REL_ TCM_HS SG_ 499 TrnsPFShftPattSw4Act "False";
BA_REL_ "GenSigRxStartValue" BU_SG_REL_ PCM_HS SG_ 499 TrnsPFShftPattSw3Act "False";
BA_REL_ "GenSigRxStartValue" BU_SG_REL_ ECM_HS SG_ 499 TrnsPFShftPattSw3Act "False";
BA_REL_ "GenSigRxStartValue" BU_SG_REL_ TCM_HS SG_ 499 TrnsPFShftPattSw3Act "False";
BA_REL_ "GenSigRxStartValue" BU_SG_REL_ PCM_HS SG_ 499 TrnsPFShftPattSw2Act "False";
BA_REL_ "GenSigRxStartValue" BU_SG_REL_ ECM_HS SG_ 499 TrnsPFShftPattSw2Act "False";
BA_REL_ "GenSigRxStartValue" BU_SG_REL_ TCM_HS SG_ 499 TrnsPFShftPattSw2Act "False";
BA_REL_ "GenSigRxStartValue" BU_SG_REL_ PCM_HS SG_ 499 TrnsPFShftPattSw1Act "False";
BA_REL_ "GenSigRxStartValue" BU_SG_REL_ ECM_HS SG_ 499 TrnsPFShftPattSw1Act "False";
BA_REL_ "GenSigRxStartValue" BU_SG_REL_ TCM_HS SG_ 499 TrnsPFShftPattSw1Act "False";
BA_REL_ "GenSigRxStartValue" BU_SG_REL_ TCM_HS SG_ 499 PFTrnsTUDSwSt "$0 - No Activation";
BA_REL_ "GenSigRxStartValue" BU_SG_REL_ TCM_HS SG_ 499 PFTrnsTUDEnSwSt "$0 - No Activation";
BA_REL_ "GenSigSuprvResp" BU_SG_REL_ VICM_HS SG_ 495 MassAirFlo 1;
BA_REL_ "GenSigTimeoutMsg" BU_SG_REL_ VICM_HS SG_ 495 MassAirFlo 495;
BA_REL_ "GenSigTimeoutTime" BU_SG_REL_ VICM_HS SG_ 495 MassAirFlo 31;
BA_REL_ "GenSigSuprvResp" BU_SG_REL_ BCM_HS SG_ 880 FOAI_VehAhdIndRq 1;
BA_REL_ "GenSigTimeoutTime" BU_SG_REL_ BCM_HS SG_ 880 FOAI_VehAhdIndRq 250;
BA_REL_ "GenSigSuprvResp" BU_SG_REL_ BCM_HS SG_ 880 FOAI_AlrtWrnIndRq 1;
BA_REL_ "GenSigTimeoutTime" BU_SG_REL_ BCM_HS SG_ 880 FOAI_AlrtWrnIndRq 250;
BA_REL_ "GenSigSuprvResp" BU_SG_REL_ BCM_HS SG_ 880 FOAI_AlrtChmIhbRq 1;
BA_REL_ "GenSigTimeoutTime" BU_SG_REL_ BCM_HS SG_ 880 FOAI_AlrtChmIhbRq 250;
BA_REL_ "GenSigSuprvResp" BU_SG_REL_ BCM_HS SG_ 880 FwdClnAlrtPr 1;
BA_REL_ "GenSigTimeoutTime" BU_SG_REL_ BCM_HS SG_ 880 FwdClnAlrtPr 250;
BA_REL_ "GenSigSuprvResp" BU_SG_REL_ BCM_HS SG_ 880 ACCUnavlbleDTWthrIO 1;
BA_REL_ "GenSigTimeoutTime" BU_SG_REL_ BCM_HS SG_ 880 ACCUnavlbleDTWthrIO 250;
BA_REL_ "GenSigSuprvResp" BU_SG_REL_ EBCM_OBD_HS SG_ 880 ACCAct370 1;
BA_REL_ "GenSigTimeoutMsg" BU_SG_REL_ EBCM_OBD_HS SG_ 880 ACCAct370 880;
BA_REL_ "GenSigTimeoutTime" BU_SG_REL_ EBCM_OBD_HS SG_ 880 ACCAct370 250;
BA_REL_ "GenSigSuprvResp" BU_SG_REL_ EBCM_HS SG_ 880 ACCAct370 1;
BA_REL_ "GenSigTimeoutMsg" BU_SG_REL_ EBCM_HS SG_ 880 ACCAct370 880;
BA_REL_ "GenSigTimeoutTime" BU_SG_REL_ EBCM_HS SG_ 880 ACCAct370 250;
BA_REL_ "GenSigSuprvResp" BU_SG_REL_ TCM_HS SG_ 880 ACCAct370 1;
BA_REL_ "GenSigTimeoutMsg" BU_SG_REL_ TCM_HS SG_ 880 ACCAct370 880;
BA_REL_ "GenSigTimeoutTime" BU_SG_REL_ TCM_HS SG_ 880 ACCAct370 250;
BA_REL_ "GenSigSuprvResp" BU_SG_REL_ BCM_HS SG_ 880 ACCAct370 1;
BA_REL_ "GenSigTimeoutMsg" BU_SG_REL_ BCM_HS SG_ 880 ACCAct370 880;
BA_REL_ "GenSigTimeoutTime" BU_SG_REL_ BCM_HS SG_ 880 ACCAct370 250;
BA_REL_ "GenSigSuprvResp" BU_SG_REL_ BCM_HS SG_ 880 DrvThrtlOvrdIO 1;
BA_REL_ "GenSigTimeoutMsg" BU_SG_REL_ BCM_HS SG_ 880 DrvThrtlOvrdIO 880;
BA_REL_ "GenSigTimeoutTime" BU_SG_REL_ BCM_HS SG_ 880 DrvThrtlOvrdIO 250;
BA_REL_ "GenSigSuprvResp" BU_SG_REL_ BCM_HS SG_ 880 ServAdpCrsCtrlIndOn 1;
BA_REL_ "GenSigTimeoutMsg" BU_SG_REL_ BCM_HS SG_ 880 ServAdpCrsCtrlIndOn 880;
BA_REL_ "GenSigTimeoutTime" BU_SG_REL_ BCM_HS SG_ 880 ServAdpCrsCtrlIndOn 250;
BA_REL_ "GenSigSuprvResp" BU_SG_REL_ ECM_HS SG_ 880 ACCDrvrSeltdSpd 1;
BA_REL_ "GenSigTimeoutMsg" BU_SG_REL_ ECM_HS SG_ 880 ACCDrvrSeltdSpd 880;
BA_REL_ "GenSigTimeoutTime" BU_SG_REL_ ECM_HS SG_ 880 ACCDrvrSeltdSpd 250;
BA_REL_ "GenSigSuprvResp" BU_SG_REL_ BCM_HS SG_ 880 ACCDrvrSeltdSpd 1;
BA_REL_ "GenSigTimeoutTime" BU_SG_REL_ BCM_HS SG_ 880 ACCDrvrSeltdSpd 250;
BA_REL_ "GenSigSuprvResp" BU_SG_REL_ BCM_HS SG_ 880 ACCHdwayStngIO 1;
BA_REL_ "GenSigTimeoutMsg" BU_SG_REL_ BCM_HS SG_ 880 ACCHdwayStngIO 880;
BA_REL_ "GenSigTimeoutTime" BU_SG_REL_ BCM_HS SG_ 880 ACCHdwayStngIO 250;
BA_REL_ "GenSigSuprvResp" BU_SG_REL_ BCM_HS SG_ 880 ACCHdwyStg 1;
BA_REL_ "GenSigTimeoutTime" BU_SG_REL_ BCM_HS SG_ 880 ACCHdwyStg 250;
BA_REL_ "GenSigSuprvResp" BU_SG_REL_ BCM_HS SG_ 880 ACCSnsClnRqdIO 1;
BA_REL_ "GenSigTimeoutMsg" BU_SG_REL_ BCM_HS SG_ 880 ACCSnsClnRqdIO 880;
BA_REL_ "GenSigTimeoutTime" BU_SG_REL_ BCM_HS SG_ 880 ACCSnsClnRqdIO 250;
BA_REL_ "GenSigSuprvResp" BU_SG_REL_ BCM_HS SG_ 880 ACCTmpUnavlbleIO 1;
BA_REL_ "GenSigTimeoutMsg" BU_SG_REL_ BCM_HS SG_ 880 ACCTmpUnavlbleIO 880;
BA_REL_ "GenSigTimeoutTime" BU_SG_REL_ BCM_HS SG_ 880 ACCTmpUnavlbleIO 250;
BA_REL_ "GenSigSuprvResp" BU_SG_REL_ BCM_HS SG_ 880 ACCDrvrSeltdSpdIO 1;
BA_REL_ "GenSigTimeoutMsg" BU_SG_REL_ BCM_HS SG_ 880 ACCDrvrSeltdSpdIO 880;
BA_REL_ "GenSigTimeoutTime" BU_SG_REL_ BCM_HS SG_ 880 ACCDrvrSeltdSpdIO 250;
BA_REL_ "GenSigSuprvResp" BU_SG_REL_ EOCM_F_HS SG_ 894 RtLwBmFld 2;
BA_REL_ "GenSigTimeoutMsg" BU_SG_REL_ EOCM_F_HS SG_ 894 RtLwBmFld 894;
BA_REL_ "GenSigTimeoutTime" BU_SG_REL_ EOCM_F_HS SG_ 894 RtLwBmFld 3750;
BA_REL_ "GenSigSuprvResp" BU_SG_REL_ EOCM_F_HS SG_ 894 RtLwBmFld 2;
BA_REL_ "GenSigTimeoutMsg" BU_SG_REL_ EOCM_F_HS SG_ 894 RtLwBmFld 894;
BA_REL_ "GenSigTimeoutTime" BU_SG_REL_ EOCM_F_HS SG_ 894 RtLwBmFld 3750;
BA_REL_ "GenSigSuprvResp" BU_SG_REL_ EOCM_F_HS SG_ 894 RtLwBmFld 2;
BA_REL_ "GenSigTimeoutMsg" BU_SG_REL_ EOCM_F_HS SG_ 894 RtLwBmFld 894;
BA_REL_ "GenSigTimeoutTime" BU_SG_REL_ EOCM_F_HS SG_ 894 RtLwBmFld 3750;
BA_REL_ "GenSigSuprvResp" BU_SG_REL_ EOCM_F_HS SG_ 894 RtLwBmFld 2;
BA_REL_ "GenSigTimeoutTime" BU_SG_REL_ EOCM_F_HS SG_ 894 RtLwBmFld 3750;
BA_REL_ "GenSigSuprvResp" BU_SG_REL_ EOCM_F_HS SG_ 894 LftLwBmFld 2;
BA_REL_ "GenSigTimeoutMsg" BU_SG_REL_ EOCM_F_HS SG_ 894 LftLwBmFld 894;
BA_REL_ "GenSigTimeoutTime" BU_SG_REL_ EOCM_F_HS SG_ 894 LftLwBmFld 3750;
BA_REL_ "GenSigSuprvResp" BU_SG_REL_ EOCM_F_HS SG_ 894 LftLwBmFld 2;
BA_REL_ "GenSigTimeoutMsg" BU_SG_REL_ EOCM_F_HS SG_ 894 LftLwBmFld 894;
BA_REL_ "GenSigTimeoutTime" BU_SG_REL_ EOCM_F_HS SG_ 894 LftLwBmFld 3750;
BA_REL_ "GenSigSuprvResp" BU_SG_REL_ EOCM_F_HS SG_ 894 LftLwBmFld 2;
BA_REL_ "GenSigTimeoutMsg" BU_SG_REL_ EOCM_F_HS SG_ 894 LftLwBmFld 894;
BA_REL_ "GenSigTimeoutTime" BU_SG_REL_ EOCM_F_HS SG_ 894 LftLwBmFld 3750;
BA_REL_ "GenSigSuprvResp" BU_SG_REL_ EOCM_F_HS SG_ 894 LftLwBmFld 2;
BA_REL_ "GenSigTimeoutTime" BU_SG_REL_ EOCM_F_HS SG_ 894 LftLwBmFld 3750;
BA_REL_ "GenSigSuprvResp" BU_SG_REL_ BCM_HS SG_ 894 HdLtLvlFlrIO 1;
BA_REL_ "GenSigTimeoutMsg" BU_SG_REL_ BCM_HS SG_ 894 HdLtLvlFlrIO 894;
BA_REL_ "GenSigTimeoutTime" BU_SG_REL_ BCM_HS SG_ 894 HdLtLvlFlrIO 3750;
BA_REL_ "GenSigSuprvResp" BU_SG_REL_ ECM_HS SG_ 298 SpdLmtrSttngTyp 1;
BA_REL_ "GenSigTimeoutMsg" BU_SG_REL_ ECM_HS SG_ 298 SpdLmtrSttngTyp 298;
BA_REL_ "GenSigTimeoutTime" BU_SG_REL_ ECM_HS SG_ 298 SpdLmtrSttngTyp 250;
BA_REL_ "GenSigSuprvResp" BU_SG_REL_ ECM_HS SG_ 298 TCSysDisSwAtv 1;
BA_REL_ "GenSigTimeoutMsg" BU_SG_REL_ ECM_HS SG_ 298 TCSysDisSwAtv 298;
BA_REL_ "GenSigTimeoutTime" BU_SG_REL_ ECM_HS SG_ 298 TCSysDisSwAtv 250;
BA_REL_ "GenSigSuprvResp" BU_SG_REL_ ECM_HS SG_ 298 AutoMdSpdLmtCnfrmd 1;
BA_REL_ "GenSigTimeoutMsg" BU_SG_REL_ ECM_HS SG_ 298 AutoMdSpdLmtCnfrmd 298;
BA_REL_ "GenSigTimeoutTime" BU_SG_REL_ ECM_HS SG_ 298 AutoMdSpdLmtCnfrmd 250;
BA_REL_ "GenSigSuprvResp" BU_SG_REL_ ECM_HS SG_ 298 TCSysDisSwAtvARC 1;
BA_REL_ "GenSigTimeoutMsg" BU_SG_REL_ ECM_HS SG_ 298 TCSysDisSwAtvARC 298;
BA_REL_ "GenSigTimeoutTime" BU_SG_REL_ ECM_HS SG_ 298 TCSysDisSwAtvARC 250;
BA_REL_ "GenSigSuprvResp" BU_SG_REL_ EBCM_OBD_HS SG_ 298 TCSysDisSwAtvARC 1;
BA_REL_ "GenSigTimeoutMsg" BU_SG_REL_ EBCM_OBD_HS SG_ 298 TCSysDisSwAtvARC 298;
BA_REL_ "GenSigTimeoutTime" BU_SG_REL_ EBCM_OBD_HS SG_ 298 TCSysDisSwAtvARC 250;
BA_REL_ "GenSigSuprvResp" BU_SG_REL_ EBCM_HS SG_ 298 TCSysDisSwAtvARC 1;
BA_REL_ "GenSigTimeoutMsg" BU_SG_REL_ EBCM_HS SG_ 298 TCSysDisSwAtvARC 298;
BA_REL_ "GenSigTimeoutTime" BU_SG_REL_ EBCM_HS SG_ 298 TCSysDisSwAtvARC 250;
BA_REL_ "GenSigSuprvResp" BU_SG_REL_ EBCM_OBD_HS SG_ 298 CrshAlrtDrvrSlctdType 1;
BA_REL_ "GenSigTimeoutMsg" BU_SG_REL_ EBCM_OBD_HS SG_ 298 CrshAlrtDrvrSlctdType 298;
BA_REL_ "GenSigTimeoutTime" BU_SG_REL_ EBCM_OBD_HS SG_ 298 CrshAlrtDrvrSlctdType 250;
BA_REL_ "GenSigSuprvResp" BU_SG_REL_ EBCM_HS SG_ 298 CrshAlrtDrvrSlctdType 1;
BA_REL_ "GenSigTimeoutMsg" BU_SG_REL_ EBCM_HS SG_ 298 CrshAlrtDrvrSlctdType 298;
BA_REL_ "GenSigTimeoutTime" BU_SG_REL_ EBCM_HS SG_ 298 CrshAlrtDrvrSlctdType 250;
BA_REL_ "GenSigVDAFailComment" BU_SG_REL_ ACC_HS SG_ 298 CrshAlrtDrvrSlctdType "Haptic Seat Virtual Device Availability";
BA_REL_ "GenSigVDAFailResp" BU_SG_REL_ ACC_HS SG_ 298 CrshAlrtDrvrSlctdType 1;
BA_REL_ "GenSigSuprvResp" BU_SG_REL_ ACC_HS SG_ 298 CrshAlrtDrvrSlctdType 1;
BA_REL_ "GenSigTimeoutMsg" BU_SG_REL_ ACC_HS SG_ 298 CrshAlrtDrvrSlctdType 298;
BA_REL_ "GenSigTimeoutTime" BU_SG_REL_ ACC_HS SG_ 298 CrshAlrtDrvrSlctdType 250;
BA_REL_ "GenSigSuprvResp" BU_SG_REL_ EBCM_OBD_HS SG_ 298 PsSbltAtc 1;
BA_REL_ "GenSigTimeoutMsg" BU_SG_REL_ EBCM_OBD_HS SG_ 298 PsSbltAtc 298;
BA_REL_ "GenSigTimeoutTime" BU_SG_REL_ EBCM_OBD_HS SG_ 298 PsSbltAtc 250;
BA_REL_ "GenSigSuprvResp" BU_SG_REL_ EBCM_HS SG_ 298 PsSbltAtc 1;
BA_REL_ "GenSigTimeoutMsg" BU_SG_REL_ EBCM_HS SG_ 298 PsSbltAtc 298;
BA_REL_ "GenSigTimeoutTime" BU_SG_REL_ EBCM_HS SG_ 298 PsSbltAtc 250;
BA_REL_ "GenSigSuprvResp" BU_SG_REL_ AHL_AFL_HS SG_ 298 RstrCustFctrDef 1;
BA_REL_ "GenSigTimeoutMsg" BU_SG_REL_ AHL_AFL_HS SG_ 298 RstrCustFctrDef 298;
BA_REL_ "GenSigTimeoutTime" BU_SG_REL_ AHL_AFL_HS SG_ 298 RstrCustFctrDef 250;
BA_REL_ "GenSigSuprvResp" BU_SG_REL_ EOCM_F_HS SG_ 298 ChmMstrVDA 1;
BA_REL_ "GenSigTimeoutMsg" BU_SG_REL_ EOCM_F_HS SG_ 298 ChmMstrVDA 298;
BA_REL_ "GenSigTimeoutTime" BU_SG_REL_ EOCM_F_HS SG_ 298 ChmMstrVDA 250;
BA_REL_ "GenSigSuprvResp" BU_SG_REL_ ACC_HS SG_ 298 ChmMstrVDA 2;
BA_REL_ "GenSigTimeoutMsg" BU_SG_REL_ ACC_HS SG_ 298 ChmMstrVDA 298;
BA_REL_ "GenSigTimeoutTime" BU_SG_REL_ ACC_HS SG_ 298 ChmMstrVDA 250;
BA_REL_ "GenSigSuprvResp" BU_SG_REL_ EOCM_F_HS SG_ 298 IPCVDA 1;
BA_REL_ "GenSigTimeoutMsg" BU_SG_REL_ EOCM_F_HS SG_ 298 IPCVDA 298;
BA_REL_ "GenSigTimeoutTime" BU_SG_REL_ EOCM_F_HS SG_ 298 IPCVDA 250;
BA_REL_ "GenSigSuprvResp" BU_SG_REL_ ACC_HS SG_ 298 IPCVDA 2;
BA_REL_ "GenSigTimeoutMsg" BU_SG_REL_ ACC_HS SG_ 298 IPCVDA 298;
BA_REL_ "GenSigTimeoutTime" BU_SG_REL_ ACC_HS SG_ 298 IPCVDA 250;
BA_REL_ "GenSigSuprvResp" BU_SG_REL_ EOCM_F_HS SG_ 298 HeadUpDispVDA 1;
BA_REL_ "GenSigTimeoutMsg" BU_SG_REL_ EOCM_F_HS SG_ 298 HeadUpDispVDA 298;
BA_REL_ "GenSigTimeoutTime" BU_SG_REL_ EOCM_F_HS SG_ 298 HeadUpDispVDA 250;
BA_REL_ "GenSigSuprvResp" BU_SG_REL_ ACC_HS SG_ 298 HeadUpDispVDA 2;
BA_REL_ "GenSigTimeoutMsg" BU_SG_REL_ ACC_HS SG_ 298 HeadUpDispVDA 298;
BA_REL_ "GenSigTimeoutTime" BU_SG_REL_ ACC_HS SG_ 298 HeadUpDispVDA 250;
BA_REL_ "GenSigSuprvResp" BU_SG_REL_ EBCM_OBD_HS SG_ 298 DDAjrSwAtv 1;
BA_REL_ "GenSigTimeoutMsg" BU_SG_REL_ EBCM_OBD_HS SG_ 298 DDAjrSwAtv 298;
BA_REL_ "GenSigTimeoutTime" BU_SG_REL_ EBCM_OBD_HS SG_ 298 DDAjrSwAtv 250;
BA_REL_ "GenSigSuprvResp" BU_SG_REL_ EBCM_HS SG_ 298 DDAjrSwAtv 1;
BA_REL_ "GenSigTimeoutMsg" BU_SG_REL_ EBCM_HS SG_ 298 DDAjrSwAtv 298;
BA_REL_ "GenSigTimeoutTime" BU_SG_REL_ EBCM_HS SG_ 298 DDAjrSwAtv 250;
BA_REL_ "GenSigRxStartValue" BU_SG_REL_ ACC_HS SG_ 298 DDAjrSwAtv "0";
BA_REL_ "GenSigSuprvResp" BU_SG_REL_ ACC_HS SG_ 298 DDAjrSwAtv 1;
BA_REL_ "GenSigTimeoutMsg" BU_SG_REL_ ACC_HS SG_ 298 DDAjrSwAtv 298;
BA_REL_ "GenSigTimeoutTime" BU_SG_REL_ ACC_HS SG_ 298 DDAjrSwAtv 250;
BA_REL_ "GenSigSuprvResp" BU_SG_REL_ PTO_HS SG_ 298 EnrgMgtLdShdRq 1;
BA_REL_ "GenSigTimeoutMsg" BU_SG_REL_ PTO_HS SG_ 298 EnrgMgtLdShdRq 298;
BA_REL_ "GenSigTimeoutTime" BU_SG_REL_ PTO_HS SG_ 298 EnrgMgtLdShdRq 250;
BA_REL_ "GenSigSuprvResp" BU_SG_REL_ EBCM_OBD_HS SG_ 298 TrlrHtchSwAtv 1;
BA_REL_ "GenSigTimeoutMsg" BU_SG_REL_ EBCM_OBD_HS SG_ 298 TrlrHtchSwAtv 298;
BA_REL_ "GenSigTimeoutTime" BU_SG_REL_ EBCM_OBD_HS SG_ 298 TrlrHtchSwAtv 250;
BA_REL_ "GenSigSuprvResp" BU_SG_REL_ EBCM_HS SG_ 298 TrlrHtchSwAtv 1;
BA_REL_ "GenSigTimeoutMsg" BU_SG_REL_ EBCM_HS SG_ 298 TrlrHtchSwAtv 298;
BA_REL_ "GenSigTimeoutTime" BU_SG_REL_ EBCM_HS SG_ 298 TrlrHtchSwAtv 250;
BA_REL_ "GenSigVDAFailComment" BU_SG_REL_ RDCM_HS SG_ 298 TrlrHtchSwAtv "Trailer Hardware Interface Virtual Device Availability";
BA_REL_ "GenSigVDAFailResp" BU_SG_REL_ RDCM_HS SG_ 298 TrlrHtchSwAtv 1;
BA_REL_ "GenSigSuprvResp" BU_SG_REL_ RDCM_HS SG_ 298 TrlrHtchSwAtv 1;
BA_REL_ "GenSigTimeoutMsg" BU_SG_REL_ RDCM_HS SG_ 298 TrlrHtchSwAtv 298;
BA_REL_ "GenSigTimeoutTime" BU_SG_REL_ RDCM_HS SG_ 298 TrlrHtchSwAtv 250;
BA_REL_ "GenSigVDAFailComment" BU_SG_REL_ ACC_HS SG_ 298 HUDActv "HeadUpDispVDA";
BA_REL_ "GenSigVDAFailResp" BU_SG_REL_ ACC_HS SG_ 298 HUDActv 1;
BA_REL_ "GenSigSuprvResp" BU_SG_REL_ ACC_HS SG_ 298 HUDActv 1;
BA_REL_ "GenSigTimeoutMsg" BU_SG_REL_ ACC_HS SG_ 298 HUDActv 298;
BA_REL_ "GenSigTimeoutTime" BU_SG_REL_ ACC_HS SG_ 298 HUDActv 250;
BA_REL_ "GenSigSuprvResp" BU_SG_REL_ TCM_HS SG_ 298 BatVlt 1;
BA_REL_ "GenSigTimeoutMsg" BU_SG_REL_ TCM_HS SG_ 298 BatVlt 298;
BA_REL_ "GenSigTimeoutTime" BU_SG_REL_ TCM_HS SG_ 298 BatVlt 250;
BA_REL_ "GenSigSuprvResp" BU_SG_REL_ HCP_HS SG_ 298 BatVlt 1;
BA_REL_ "GenSigTimeoutMsg" BU_SG_REL_ HCP_HS SG_ 298 BatVlt 298;
BA_REL_ "GenSigTimeoutTime" BU_SG_REL_ HCP_HS SG_ 298 BatVlt 250;
BA_REL_ "GenSigSuprvResp" BU_SG_REL_ BCP_HS SG_ 298 BatVlt 1;
BA_REL_ "GenSigTimeoutMsg" BU_SG_REL_ BCP_HS SG_ 298 BatVlt 298;
BA_REL_ "GenSigTimeoutTime" BU_SG_REL_ BCP_HS SG_ 298 BatVlt 250;
BA_REL_ "GenSigSuprvResp" BU_SG_REL_ MCP_C_HS SG_ 298 BatVlt 1;
BA_REL_ "GenSigTimeoutMsg" BU_SG_REL_ MCP_C_HS SG_ 298 BatVlt 298;
BA_REL_ "GenSigTimeoutTime" BU_SG_REL_ MCP_C_HS SG_ 298 BatVlt 250;
BA_REL_ "GenSigSuprvResp" BU_SG_REL_ MCP_B_HS SG_ 298 BatVlt 1;
BA_REL_ "GenSigTimeoutMsg" BU_SG_REL_ MCP_B_HS SG_ 298 BatVlt 298;
BA_REL_ "GenSigTimeoutTime" BU_SG_REL_ MCP_B_HS SG_ 298 BatVlt 250;
BA_REL_ "GenSigSuprvResp" BU_SG_REL_ MCP_A_HS SG_ 298 BatVlt 1;
BA_REL_ "GenSigTimeoutMsg" BU_SG_REL_ MCP_A_HS SG_ 298 BatVlt 298;
BA_REL_ "GenSigTimeoutTime" BU_SG_REL_ MCP_A_HS SG_ 298 BatVlt 250;
BA_REL_ "GenSigSuprvResp" BU_SG_REL_ ECM_HS SG_ 298 BatVlt 1;
BA_REL_ "GenSigTimeoutMsg" BU_SG_REL_ ECM_HS SG_ 298 BatVlt 298;
BA_REL_ "GenSigTimeoutTime" BU_SG_REL_ ECM_HS SG_ 298 BatVlt 250;
BA_REL_ "GenSigSuprvResp" BU_SG_REL_ ICCM_OBD_HS SG_ 298 BatVlt 1;
BA_REL_ "GenSigTimeoutMsg" BU_SG_REL_ ICCM_OBD_HS SG_ 298 BatVlt 298;
BA_REL_ "GenSigTimeoutTime" BU_SG_REL_ ICCM_OBD_HS SG_ 298 BatVlt 250;
BA_REL_ "GenSigSuprvResp" BU_SG_REL_ ICCM_HS SG_ 298 BatVlt 1;
BA_REL_ "GenSigTimeoutMsg" BU_SG_REL_ ICCM_HS SG_ 298 BatVlt 298;
BA_REL_ "GenSigTimeoutTime" BU_SG_REL_ ICCM_HS SG_ 298 BatVlt 250;
BA_REL_ "GenSigSuprvResp" BU_SG_REL_ EPB_HS SG_ 298 DrSbltAtc 1;
BA_REL_ "GenSigTimeoutMsg" BU_SG_REL_ EPB_HS SG_ 298 DrSbltAtc 298;
BA_REL_ "GenSigTimeoutTime" BU_SG_REL_ EPB_HS SG_ 298 DrSbltAtc 250;
BA_REL_ "GenSigSuprvResp" BU_SG_REL_ ICCM_OBD_HS SG_ 1322 TireRRPrsStat 1;
BA_REL_ "GenSigTimeoutMsg" BU_SG_REL_ ICCM_OBD_HS SG_ 1322 TireRRPrsStat 1322;
BA_REL_ "GenSigTimeoutTime" BU_SG_REL_ ICCM_OBD_HS SG_ 1322 TireRRPrsStat 2500;
BA_REL_ "GenSigSuprvResp" BU_SG_REL_ ICCM_HS SG_ 1322 TireRRPrsStat 1;
BA_REL_ "GenSigTimeoutMsg" BU_SG_REL_ ICCM_HS SG_ 1322 TireRRPrsStat 1322;
BA_REL_ "GenSigTimeoutTime" BU_SG_REL_ ICCM_HS SG_ 1322 TireRRPrsStat 2500;
BA_REL_ "GenSigSuprvResp" BU_SG_REL_ RDCM_HS SG_ 1322 TireRRPrsStat 1;
BA_REL_ "GenSigTimeoutMsg" BU_SG_REL_ RDCM_HS SG_ 1322 TireRRPrsStat 1322;
BA_REL_ "GenSigTimeoutTime" BU_SG_REL_ RDCM_HS SG_ 1322 TireRRPrsStat 2500;
BA_REL_ "GenSigSuprvResp" BU_SG_REL_ ICCM_OBD_HS SG_ 1322 TireRRPrs 1;
BA_REL_ "GenSigTimeoutMsg" BU_SG_REL_ ICCM_OBD_HS SG_ 1322 TireRRPrs 1322;
BA_REL_ "GenSigTimeoutTime" BU_SG_REL_ ICCM_OBD_HS SG_ 1322 TireRRPrs 2500;
BA_REL_ "GenSigSuprvResp" BU_SG_REL_ ICCM_HS SG_ 1322 TireRRPrs 1;
BA_REL_ "GenSigTimeoutMsg" BU_SG_REL_ ICCM_HS SG_ 1322 TireRRPrs 1322;
BA_REL_ "GenSigTimeoutTime" BU_SG_REL_ ICCM_HS SG_ 1322 TireRRPrs 2500;
BA_REL_ "GenSigSuprvResp" BU_SG_REL_ RDCM_HS SG_ 1322 TireRRPrs 1;
BA_REL_ "GenSigTimeoutMsg" BU_SG_REL_ RDCM_HS SG_ 1322 TireRRPrs 1322;
BA_REL_ "GenSigTimeoutTime" BU_SG_REL_ RDCM_HS SG_ 1322 TireRRPrs 2500;
BA_REL_ "GenSigSuprvResp" BU_SG_REL_ ICCM_OBD_HS SG_ 1322 TireRFPrsStat 1;
BA_REL_ "GenSigTimeoutMsg" BU_SG_REL_ ICCM_OBD_HS SG_ 1322 TireRFPrsStat 1322;
BA_REL_ "GenSigTimeoutTime" BU_SG_REL_ ICCM_OBD_HS SG_ 1322 TireRFPrsStat 2500;
BA_REL_ "GenSigSuprvResp" BU_SG_REL_ ICCM_HS SG_ 1322 TireRFPrsStat 1;
BA_REL_ "GenSigTimeoutMsg" BU_SG_REL_ ICCM_HS SG_ 1322 TireRFPrsStat 1322;
BA_REL_ "GenSigTimeoutTime" BU_SG_REL_ ICCM_HS SG_ 1322 TireRFPrsStat 2500;
BA_REL_ "GenSigSuprvResp" BU_SG_REL_ RDCM_HS SG_ 1322 TireRFPrsStat 1;
BA_REL_ "GenSigTimeoutMsg" BU_SG_REL_ RDCM_HS SG_ 1322 TireRFPrsStat 1322;
BA_REL_ "GenSigTimeoutTime" BU_SG_REL_ RDCM_HS SG_ 1322 TireRFPrsStat 2500;
BA_REL_ "GenSigSuprvResp" BU_SG_REL_ ICCM_OBD_HS SG_ 1322 TireRFPrs 1;
BA_REL_ "GenSigTimeoutMsg" BU_SG_REL_ ICCM_OBD_HS SG_ 1322 TireRFPrs 1322;
BA_REL_ "GenSigTimeoutTime" BU_SG_REL_ ICCM_OBD_HS SG_ 1322 TireRFPrs 2500;
BA_REL_ "GenSigSuprvResp" BU_SG_REL_ ICCM_HS SG_ 1322 TireRFPrs 1;
BA_REL_ "GenSigTimeoutMsg" BU_SG_REL_ ICCM_HS SG_ 1322 TireRFPrs 1322;
BA_REL_ "GenSigTimeoutTime" BU_SG_REL_ ICCM_HS SG_ 1322 TireRFPrs 2500;
BA_REL_ "GenSigSuprvResp" BU_SG_REL_ RDCM_HS SG_ 1322 TireRFPrs 1;
BA_REL_ "GenSigTimeoutMsg" BU_SG_REL_ RDCM_HS SG_ 1322 TireRFPrs 1322;
BA_REL_ "GenSigTimeoutTime" BU_SG_REL_ RDCM_HS SG_ 1322 TireRFPrs 2500;
BA_REL_ "GenSigSuprvResp" BU_SG_REL_ ICCM_OBD_HS SG_ 1322 TireLRPrsStat 1;
BA_REL_ "GenSigTimeoutMsg" BU_SG_REL_ ICCM_OBD_HS SG_ 1322 TireLRPrsStat 1322;
BA_REL_ "GenSigTimeoutTime" BU_SG_REL_ ICCM_OBD_HS SG_ 1322 TireLRPrsStat 2500;
BA_REL_ "GenSigSuprvResp" BU_SG_REL_ ICCM_HS SG_ 1322 TireLRPrsStat 1;
BA_REL_ "GenSigTimeoutMsg" BU_SG_REL_ ICCM_HS SG_ 1322 TireLRPrsStat 1322;
BA_REL_ "GenSigTimeoutTime" BU_SG_REL_ ICCM_HS SG_ 1322 TireLRPrsStat 2500;
BA_REL_ "GenSigSuprvResp" BU_SG_REL_ RDCM_HS SG_ 1322 TireLRPrsStat 1;
BA_REL_ "GenSigTimeoutMsg" BU_SG_REL_ RDCM_HS SG_ 1322 TireLRPrsStat 1322;
BA_REL_ "GenSigTimeoutTime" BU_SG_REL_ RDCM_HS SG_ 1322 TireLRPrsStat 2500;
BA_REL_ "GenSigSuprvResp" BU_SG_REL_ ICCM_OBD_HS SG_ 1322 TireLRPrs 1;
BA_REL_ "GenSigTimeoutMsg" BU_SG_REL_ ICCM_OBD_HS SG_ 1322 TireLRPrs 1322;
BA_REL_ "GenSigTimeoutTime" BU_SG_REL_ ICCM_OBD_HS SG_ 1322 TireLRPrs 2500;
BA_REL_ "GenSigSuprvResp" BU_SG_REL_ ICCM_HS SG_ 1322 TireLRPrs 1;
BA_REL_ "GenSigTimeoutMsg" BU_SG_REL_ ICCM_HS SG_ 1322 TireLRPrs 1322;
BA_REL_ "GenSigTimeoutTime" BU_SG_REL_ ICCM_HS SG_ 1322 TireLRPrs 2500;
BA_REL_ "GenSigSuprvResp" BU_SG_REL_ RDCM_HS SG_ 1322 TireLRPrs 1;
BA_REL_ "GenSigTimeoutMsg" BU_SG_REL_ RDCM_HS SG_ 1322 TireLRPrs 1322;
BA_REL_ "GenSigTimeoutTime" BU_SG_REL_ RDCM_HS SG_ 1322 TireLRPrs 2500;
BA_REL_ "GenSigSuprvResp" BU_SG_REL_ ICCM_OBD_HS SG_ 1322 TireLFPrsStat 1;
BA_REL_ "GenSigTimeoutMsg" BU_SG_REL_ ICCM_OBD_HS SG_ 1322 TireLFPrsStat 1322;
BA_REL_ "GenSigTimeoutTime" BU_SG_REL_ ICCM_OBD_HS SG_ 1322 TireLFPrsStat 2500;
BA_REL_ "GenSigSuprvResp" BU_SG_REL_ ICCM_HS SG_ 1322 TireLFPrsStat 1;
BA_REL_ "GenSigTimeoutMsg" BU_SG_REL_ ICCM_HS SG_ 1322 TireLFPrsStat 1322;
BA_REL_ "GenSigTimeoutTime" BU_SG_REL_ ICCM_HS SG_ 1322 TireLFPrsStat 2500;
BA_REL_ "GenSigSuprvResp" BU_SG_REL_ RDCM_HS SG_ 1322 TireLFPrsStat 1;
BA_REL_ "GenSigTimeoutMsg" BU_SG_REL_ RDCM_HS SG_ 1322 TireLFPrsStat 1322;
BA_REL_ "GenSigTimeoutTime" BU_SG_REL_ RDCM_HS SG_ 1322 TireLFPrsStat 2500;
BA_REL_ "GenSigSuprvResp" BU_SG_REL_ ICCM_OBD_HS SG_ 1322 TireLFPrs 1;
BA_REL_ "GenSigTimeoutMsg" BU_SG_REL_ ICCM_OBD_HS SG_ 1322 TireLFPrs 1322;
BA_REL_ "GenSigTimeoutTime" BU_SG_REL_ ICCM_OBD_HS SG_ 1322 TireLFPrs 2500;
BA_REL_ "GenSigSuprvResp" BU_SG_REL_ ICCM_HS SG_ 1322 TireLFPrs 1;
BA_REL_ "GenSigTimeoutMsg" BU_SG_REL_ ICCM_HS SG_ 1322 TireLFPrs 1322;
BA_REL_ "GenSigTimeoutTime" BU_SG_REL_ ICCM_HS SG_ 1322 TireLFPrs 2500;
BA_REL_ "GenSigSuprvResp" BU_SG_REL_ RDCM_HS SG_ 1322 TireLFPrs 1;
BA_REL_ "GenSigTimeoutMsg" BU_SG_REL_ RDCM_HS SG_ 1322 TireLFPrs 1322;
BA_REL_ "GenSigTimeoutTime" BU_SG_REL_ RDCM_HS SG_ 1322 TireLFPrs 2500;
BA_REL_ "GenSigSuprvResp" BU_SG_REL_ EBCM_OBD_HS SG_ 1300 VehIdNmDig2_9 1;
BA_REL_ "GenSigTimeoutMsg" BU_SG_REL_ EBCM_OBD_HS SG_ 1300 VehIdNmDig2_9 1300;
BA_REL_ "GenSigTimeoutTime" BU_SG_REL_ EBCM_OBD_HS SG_ 1300 VehIdNmDig2_9 2500;
BA_REL_ "GenSigSuprvResp" BU_SG_REL_ EBCM_HS SG_ 1300 VehIdNmDig2_9 1;
BA_REL_ "GenSigTimeoutMsg" BU_SG_REL_ EBCM_HS SG_ 1300 VehIdNmDig2_9 1300;
BA_REL_ "GenSigTimeoutTime" BU_SG_REL_ EBCM_HS SG_ 1300 VehIdNmDig2_9 2500;
BA_REL_ "GenSigSuprvResp" BU_SG_REL_ TCCM_HS SG_ 1300 VehIdNmDig2_9 1;
BA_REL_ "GenSigTimeoutMsg" BU_SG_REL_ TCCM_HS SG_ 1300 VehIdNmDig2_9 1300;
BA_REL_ "GenSigTimeoutTime" BU_SG_REL_ TCCM_HS SG_ 1300 VehIdNmDig2_9 2500;
BA_REL_ "GenSigSuprvResp" BU_SG_REL_ RDCM_HS SG_ 1300 VehIdNmDig2_9 1;
BA_REL_ "GenSigTimeoutMsg" BU_SG_REL_ RDCM_HS SG_ 1300 VehIdNmDig2_9 1300;
BA_REL_ "GenSigTimeoutTime" BU_SG_REL_ RDCM_HS SG_ 1300 VehIdNmDig2_9 2500;
BA_REL_ "GenSigSuprvResp" BU_SG_REL_ TCCM_HS SG_ 288 VehOdo 1;
BA_REL_ "GenSigTimeoutMsg" BU_SG_REL_ TCCM_HS SG_ 288 VehOdo 288;
BA_REL_ "GenSigTimeoutTime" BU_SG_REL_ TCCM_HS SG_ 288 VehOdo 12500;
BA_REL_ "GenSigSuprvResp" BU_SG_REL_ ACC_HS SG_ 288 VehOdo 1;
BA_REL_ "GenSigTimeoutMsg" BU_SG_REL_ ACC_HS SG_ 288 VehOdo 288;
BA_REL_ "GenSigTimeoutTime" BU_SG_REL_ ACC_HS SG_ 288 VehOdo 12500;
BA_REL_ "GenSigSuprvResp" BU_SG_REL_ FCM_HS SG_ 485 StrAngSnsChksm 1;
BA_REL_ "GenSigTimeoutMsg" BU_SG_REL_ FCM_HS SG_ 485 StrAngSnsChksm 485;
BA_REL_ "GenSigTimeoutTime" BU_SG_REL_ FCM_HS SG_ 485 StrAngSnsChksm 250;
BA_REL_ "GenSigRxStartValue" BU_SG_REL_ RDCM_HS SG_ 485 StrWhlAngSenCalStat "$2 - Calibrated";
BA_REL_ "GenSigRxStartValue" BU_SG_REL_ ACC_HS SG_ 485 StrWhlAngSenCalStat "0x0-Unknown";
BA_REL_ "GenSigSuprvResp" BU_SG_REL_ FCM_HS SG_ 485 StrWhAngGrd 1;
BA_REL_ "GenSigTimeoutMsg" BU_SG_REL_ FCM_HS SG_ 485 StrWhAngGrd 485;
BA_REL_ "GenSigTimeoutTime" BU_SG_REL_ FCM_HS SG_ 485 StrWhAngGrd 250;
BA_REL_ "GenSigSuprvResp" BU_SG_REL_ HMIM_HS SG_ 485 StrWhAng 1;
BA_REL_ "GenSigTimeoutMsg" BU_SG_REL_ HMIM_HS SG_ 485 StrWhAng 485;
BA_REL_ "GenSigTimeoutTime" BU_SG_REL_ HMIM_HS SG_ 485 StrWhAng 250;
BA_REL_ "GenSigSuprvResp" BU_SG_REL_ FCM_HS SG_ 485 StrWhAng 1;
BA_REL_ "GenSigTimeoutMsg" BU_SG_REL_ FCM_HS SG_ 485 StrWhAng 485;
BA_REL_ "GenSigTimeoutTime" BU_SG_REL_ FCM_HS SG_ 485 StrWhAng 250;
BA_REL_ "GenSigSuprvResp" BU_SG_REL_ FCM_HS SG_ 485 StrWhAng 1;
BA_REL_ "GenSigTimeoutMsg" BU_SG_REL_ FCM_HS SG_ 485 StrWhAng 485;
BA_REL_ "GenSigTimeoutTime" BU_SG_REL_ FCM_HS SG_ 485 StrWhAng 250;
BA_REL_ "GenSigSuprvResp" BU_SG_REL_ ICCM_OBD_HS SG_ 485 StrWhAng 1;
BA_REL_ "GenSigTimeoutMsg" BU_SG_REL_ ICCM_OBD_HS SG_ 485 StrWhAng 485;
BA_REL_ "GenSigTimeoutTime" BU_SG_REL_ ICCM_OBD_HS SG_ 485 StrWhAng 250;
BA_REL_ "GenSigSuprvResp" BU_SG_REL_ ICCM_HS SG_ 485 StrWhAng 1;
BA_REL_ "GenSigTimeoutMsg" BU_SG_REL_ ICCM_HS SG_ 485 StrWhAng 485;
BA_REL_ "GenSigTimeoutTime" BU_SG_REL_ ICCM_HS SG_ 485 StrWhAng 250;
BA_REL_ "GenSigSuprvResp" BU_SG_REL_ ALC_HS SG_ 485 StrWhAng 1;
BA_REL_ "GenSigTimeoutMsg" BU_SG_REL_ ALC_HS SG_ 485 StrWhAng 485;
BA_REL_ "GenSigTimeoutTime" BU_SG_REL_ ALC_HS SG_ 485 StrWhAng 250;
BA_REL_ "GenSigSuprvResp" BU_SG_REL_ SADS_HS SG_ 485 StrWhAng 1;
BA_REL_ "GenSigTimeoutMsg" BU_SG_REL_ SADS_HS SG_ 485 StrWhAng 485;
BA_REL_ "GenSigTimeoutTime" BU_SG_REL_ SADS_HS SG_ 485 StrWhAng 250;
BA_REL_ "GenSigSuprvResp" BU_SG_REL_ VES_HS SG_ 485 StrWhAng 1;
BA_REL_ "GenSigTimeoutMsg" BU_SG_REL_ VES_HS SG_ 485 StrWhAng 485;
BA_REL_ "GenSigTimeoutTime" BU_SG_REL_ VES_HS SG_ 485 StrWhAng 250;
BA_REL_ "GenSigSuprvResp" BU_SG_REL_ EPS_HS SG_ 485 StrWhAng 1;
BA_REL_ "GenSigTimeoutMsg" BU_SG_REL_ EPS_HS SG_ 485 StrWhAng 485;
BA_REL_ "GenSigTimeoutTime" BU_SG_REL_ EPS_HS SG_ 485 StrWhAng 250;
BA_REL_ "GenSigVBitResp" BU_SG_REL_ RDCM_HS SG_ 485 StrWhAng 1;
BA_REL_ "GenSigVDAFailComment" BU_SG_REL_ RDCM_HS SG_ 485 StrWhAng "Steering Wheel Angle Virtual Device Availability";
BA_REL_ "GenSigVDAFailResp" BU_SG_REL_ RDCM_HS SG_ 485 StrWhAng 1;
BA_REL_ "GenSigSuprvResp" BU_SG_REL_ RDCM_HS SG_ 485 StrWhAng 1;
BA_REL_ "GenSigTimeoutMsg" BU_SG_REL_ RDCM_HS SG_ 485 StrWhAng 485;
BA_REL_ "GenSigTimeoutTime" BU_SG_REL_ RDCM_HS SG_ 485 StrWhAng 250;
BA_REL_ "GenSigVBitResp" BU_SG_REL_ RDCM_HS SG_ 485 StrWhAng 1;
BA_REL_ "GenSigVDAFailComment" BU_SG_REL_ RDCM_HS SG_ 485 StrWhAng "Steering Wheel Angle Virtual Device Availability";
BA_REL_ "GenSigVDAFailResp" BU_SG_REL_ RDCM_HS SG_ 485 StrWhAng 1;
BA_REL_ "GenSigSuprvResp" BU_SG_REL_ RDCM_HS SG_ 485 StrWhAng 1;
BA_REL_ "GenSigTimeoutMsg" BU_SG_REL_ RDCM_HS SG_ 485 StrWhAng 485;
BA_REL_ "GenSigTimeoutTime" BU_SG_REL_ RDCM_HS SG_ 485 StrWhAng 250;
BA_REL_ "GenSigVBitResp" BU_SG_REL_ ACC_HS SG_ 485 StrWhAng 1;
BA_REL_ "GenSigVDAFailComment" BU_SG_REL_ ACC_HS SG_ 485 StrWhAng "Steering Wheel Angle Virtual Device Availability";
BA_REL_ "GenSigVDAFailResp" BU_SG_REL_ ACC_HS SG_ 485 StrWhAng 1;
BA_REL_ "GenSigSuprvResp" BU_SG_REL_ ACC_HS SG_ 485 StrWhAng 1;
BA_REL_ "GenSigTimeoutMsg" BU_SG_REL_ ACC_HS SG_ 485 StrWhAng 485;
BA_REL_ "GenSigTimeoutTime" BU_SG_REL_ ACC_HS SG_ 485 StrWhAng 125;
BA_REL_ "GenSigSuprvResp" BU_SG_REL_ AHL_AFL_HS SG_ 485 StrWhAng 1;
BA_REL_ "GenSigTimeoutMsg" BU_SG_REL_ AHL_AFL_HS SG_ 485 StrWhAng 485;
BA_REL_ "GenSigTimeoutTime" BU_SG_REL_ AHL_AFL_HS SG_ 485 StrWhAng 250;
BA_REL_ "GenSigVBitResp" BU_SG_REL_ BCM_HS SG_ 485 StrWhAng 1;
BA_REL_ "GenSigSuprvResp" BU_SG_REL_ BCM_HS SG_ 485 StrWhAng 1;
BA_REL_ "GenSigTimeoutMsg" BU_SG_REL_ BCM_HS SG_ 485 StrWhAng 485;
BA_REL_ "GenSigTimeoutTime" BU_SG_REL_ BCM_HS SG_ 485 StrWhAng 250;
BA_REL_ "GenSigVBitResp" BU_SG_REL_ BCM_HS SG_ 485 StrWhAng 1;
BA_REL_ "GenSigSuprvResp" BU_SG_REL_ BCM_HS SG_ 485 StrWhAng 1;
BA_REL_ "GenSigTimeoutMsg" BU_SG_REL_ BCM_HS SG_ 485 StrWhAng 485;
BA_REL_ "GenSigTimeoutTime" BU_SG_REL_ BCM_HS SG_ 485 StrWhAng 250;
BA_REL_ "GenSigSuprvResp" BU_SG_REL_ TCCM_HS SG_ 485 StrWhAng 1;
BA_REL_ "GenSigTimeoutMsg" BU_SG_REL_ TCCM_HS SG_ 485 StrWhAng 485;
BA_REL_ "GenSigTimeoutTime" BU_SG_REL_ TCCM_HS SG_ 485 StrWhAng 250;
BA_REL_ "GenSigSuprvResp" BU_SG_REL_ TCCM_HS SG_ 485 StrWhAng 1;
BA_REL_ "GenSigTimeoutMsg" BU_SG_REL_ TCCM_HS SG_ 485 StrWhAng 485;
BA_REL_ "GenSigTimeoutTime" BU_SG_REL_ TCCM_HS SG_ 485 StrWhAng 250;
BA_REL_ "GenSigSuprvResp" BU_SG_REL_ HCP_HS SG_ 1001 DistRollCntAvgDrvnSrc 1;
BA_REL_ "GenSigTimeoutMsg" BU_SG_REL_ HCP_HS SG_ 1001 DistRollCntAvgDrvnSrc 1001;
BA_REL_ "GenSigTimeoutTime" BU_SG_REL_ HCP_HS SG_ 1001 DistRollCntAvgDrvnSrc 250;
BA_REL_ "GenSigSuprvResp" BU_SG_REL_ BCP_HS SG_ 1001 DistRollCntAvgDrvnSrc 1;
BA_REL_ "GenSigTimeoutMsg" BU_SG_REL_ BCP_HS SG_ 1001 DistRollCntAvgDrvnSrc 1001;
BA_REL_ "GenSigTimeoutTime" BU_SG_REL_ BCP_HS SG_ 1001 DistRollCntAvgDrvnSrc 250;
BA_REL_ "GenSigSuprvResp" BU_SG_REL_ EBCM_OBD_HS SG_ 1001 DistRollCntAvgDrvnSrc 1;
BA_REL_ "GenSigTimeoutMsg" BU_SG_REL_ EBCM_OBD_HS SG_ 1001 DistRollCntAvgDrvnSrc 1001;
BA_REL_ "GenSigTimeoutTime" BU_SG_REL_ EBCM_OBD_HS SG_ 1001 DistRollCntAvgDrvnSrc 250;
BA_REL_ "GenSigSuprvResp" BU_SG_REL_ EBCM_HS SG_ 1001 DistRollCntAvgDrvnSrc 1;
BA_REL_ "GenSigTimeoutMsg" BU_SG_REL_ EBCM_HS SG_ 1001 DistRollCntAvgDrvnSrc 1001;
BA_REL_ "GenSigTimeoutTime" BU_SG_REL_ EBCM_HS SG_ 1001 DistRollCntAvgDrvnSrc 250;
BA_REL_ "GenSigSuprvResp" BU_SG_REL_ PTO_HS SG_ 1001 VehSpdAvgDrvnSrc 1;
BA_REL_ "GenSigTimeoutMsg" BU_SG_REL_ PTO_HS SG_ 1001 VehSpdAvgDrvnSrc 1001;
BA_REL_ "GenSigTimeoutTime" BU_SG_REL_ PTO_HS SG_ 1001 VehSpdAvgDrvnSrc 250;
BA_REL_ "GenSigSuprvResp" BU_SG_REL_ EBCM_OBD_HS SG_ 1001 VehSpdAvgDrvnSrc 1;
BA_REL_ "GenSigTimeoutMsg" BU_SG_REL_ EBCM_OBD_HS SG_ 1001 VehSpdAvgDrvnSrc 1001;
BA_REL_ "GenSigTimeoutTime" BU_SG_REL_ EBCM_OBD_HS SG_ 1001 VehSpdAvgDrvnSrc 250;
BA_REL_ "GenSigSuprvResp" BU_SG_REL_ EBCM_HS SG_ 1001 VehSpdAvgDrvnSrc 1;
BA_REL_ "GenSigTimeoutMsg" BU_SG_REL_ EBCM_HS SG_ 1001 VehSpdAvgDrvnSrc 1001;
BA_REL_ "GenSigTimeoutTime" BU_SG_REL_ EBCM_HS SG_ 1001 VehSpdAvgDrvnSrc 250;
BA_REL_ "GenSigSuprvResp" BU_SG_REL_ EBCM_OBD_HS SG_ 1001 DstRolCntAvNDrRstOc 1;
BA_REL_ "GenSigTimeoutMsg" BU_SG_REL_ EBCM_OBD_HS SG_ 1001 DstRolCntAvNDrRstOc 1001;
BA_REL_ "GenSigTimeoutTime" BU_SG_REL_ EBCM_OBD_HS SG_ 1001 DstRolCntAvNDrRstOc 250;
BA_REL_ "GenSigSuprvResp" BU_SG_REL_ EBCM_HS SG_ 1001 DstRolCntAvNDrRstOc 1;
BA_REL_ "GenSigTimeoutMsg" BU_SG_REL_ EBCM_HS SG_ 1001 DstRolCntAvNDrRstOc 1001;
BA_REL_ "GenSigTimeoutTime" BU_SG_REL_ EBCM_HS SG_ 1001 DstRolCntAvNDrRstOc 250;
BA_REL_ "GenSigSuprvResp" BU_SG_REL_ VICM_HS SG_ 1001 DstRolCntAvgNonDrvn 1;
BA_REL_ "GenSigTimeoutMsg" BU_SG_REL_ VICM_HS SG_ 1001 DstRolCntAvgNonDrvn 1001;
BA_REL_ "GenSigTimeoutTime" BU_SG_REL_ VICM_HS SG_ 1001 DstRolCntAvgNonDrvn 250;
BA_REL_ "GenSigSuprvResp" BU_SG_REL_ EBCM_OBD_HS SG_ 1001 DstRolCntAvgNonDrvn 1;
BA_REL_ "GenSigTimeoutMsg" BU_SG_REL_ EBCM_OBD_HS SG_ 1001 DstRolCntAvgNonDrvn 1001;
BA_REL_ "GenSigTimeoutTime" BU_SG_REL_ EBCM_OBD_HS SG_ 1001 DstRolCntAvgNonDrvn 250;
BA_REL_ "GenSigSuprvResp" BU_SG_REL_ EBCM_HS SG_ 1001 DstRolCntAvgNonDrvn 1;
BA_REL_ "GenSigTimeoutMsg" BU_SG_REL_ EBCM_HS SG_ 1001 DstRolCntAvgNonDrvn 1001;
BA_REL_ "GenSigTimeoutTime" BU_SG_REL_ EBCM_HS SG_ 1001 DstRolCntAvgNonDrvn 250;
BA_REL_ "GenSigVBitResp" BU_SG_REL_ BCM_HS SG_ 1001 DstRolCntAvgNonDrvn 1;
BA_REL_ "GenSigSuprvResp" BU_SG_REL_ BCM_HS SG_ 1001 DstRolCntAvgNonDrvn 1;
BA_REL_ "GenSigTimeoutMsg" BU_SG_REL_ BCM_HS SG_ 1001 DstRolCntAvgNonDrvn 1001;
BA_REL_ "GenSigTimeoutTime" BU_SG_REL_ BCM_HS SG_ 1001 DstRolCntAvgNonDrvn 250;
BA_REL_ "GenSigSuprvResp" BU_SG_REL_ HCP_HS SG_ 1001 DstRolCntAvgDrnRstOc 1;
BA_REL_ "GenSigTimeoutMsg" BU_SG_REL_ HCP_HS SG_ 1001 DstRolCntAvgDrnRstOc 1001;
BA_REL_ "GenSigTimeoutTime" BU_SG_REL_ HCP_HS SG_ 1001 DstRolCntAvgDrnRstOc 250;
BA_REL_ "GenSigSuprvResp" BU_SG_REL_ BCP_HS SG_ 1001 DstRolCntAvgDrnRstOc 1;
BA_REL_ "GenSigTimeoutMsg" BU_SG_REL_ BCP_HS SG_ 1001 DstRolCntAvgDrnRstOc 1001;
BA_REL_ "GenSigTimeoutTime" BU_SG_REL_ BCP_HS SG_ 1001 DstRolCntAvgDrnRstOc 250;
BA_REL_ "GenSigSuprvResp" BU_SG_REL_ EBCM_OBD_HS SG_ 1001 DstRolCntAvgDrnRstOc 1;
BA_REL_ "GenSigTimeoutMsg" BU_SG_REL_ EBCM_OBD_HS SG_ 1001 DstRolCntAvgDrnRstOc 1001;
BA_REL_ "GenSigTimeoutTime" BU_SG_REL_ EBCM_OBD_HS SG_ 1001 DstRolCntAvgDrnRstOc 250;
BA_REL_ "GenSigSuprvResp" BU_SG_REL_ EBCM_HS SG_ 1001 DstRolCntAvgDrnRstOc 1;
BA_REL_ "GenSigTimeoutMsg" BU_SG_REL_ EBCM_HS SG_ 1001 DstRolCntAvgDrnRstOc 1001;
BA_REL_ "GenSigTimeoutTime" BU_SG_REL_ EBCM_HS SG_ 1001 DstRolCntAvgDrnRstOc 250;
BA_REL_ "GenSigSuprvResp" BU_SG_REL_ HCP_HS SG_ 1001 DistRollCntAvgDrvn 1;
BA_REL_ "GenSigTimeoutMsg" BU_SG_REL_ HCP_HS SG_ 1001 DistRollCntAvgDrvn 1001;
BA_REL_ "GenSigTimeoutTime" BU_SG_REL_ HCP_HS SG_ 1001 DistRollCntAvgDrvn 250;
BA_REL_ "GenSigSuprvResp" BU_SG_REL_ BCP_HS SG_ 1001 DistRollCntAvgDrvn 1;
BA_REL_ "GenSigTimeoutMsg" BU_SG_REL_ BCP_HS SG_ 1001 DistRollCntAvgDrvn 1001;
BA_REL_ "GenSigTimeoutTime" BU_SG_REL_ BCP_HS SG_ 1001 DistRollCntAvgDrvn 250;
BA_REL_ "GenSigSuprvResp" BU_SG_REL_ EBCM_OBD_HS SG_ 1001 DistRollCntAvgDrvn 1;
BA_REL_ "GenSigTimeoutMsg" BU_SG_REL_ EBCM_OBD_HS SG_ 1001 DistRollCntAvgDrvn 1001;
BA_REL_ "GenSigTimeoutTime" BU_SG_REL_ EBCM_OBD_HS SG_ 1001 DistRollCntAvgDrvn 250;
BA_REL_ "GenSigSuprvResp" BU_SG_REL_ EBCM_HS SG_ 1001 DistRollCntAvgDrvn 1;
BA_REL_ "GenSigTimeoutMsg" BU_SG_REL_ EBCM_HS SG_ 1001 DistRollCntAvgDrvn 1001;
BA_REL_ "GenSigTimeoutTime" BU_SG_REL_ EBCM_HS SG_ 1001 DistRollCntAvgDrvn 250;
BA_REL_ "GenSigSuprvResp" BU_SG_REL_ VICM_HS SG_ 1001 DistRollCntAvgDrvn 1;
BA_REL_ "GenSigTimeoutMsg" BU_SG_REL_ VICM_HS SG_ 1001 DistRollCntAvgDrvn 1001;
BA_REL_ "GenSigTimeoutTime" BU_SG_REL_ VICM_HS SG_ 1001 DistRollCntAvgDrvn 250;
BA_REL_ "GenSigVBitResp" BU_SG_REL_ ICCM_OBD_HS SG_ 1001 DistRollCntAvgDrvn 1;
BA_REL_ "GenSigVBitResp" BU_SG_REL_ ICCM_HS SG_ 1001 DistRollCntAvgDrvn 1;
BA_REL_ "GenSigVBitResp" BU_SG_REL_ FSCM_ITBC_HS SG_ 1001 DistRollCntAvgDrvn 1;
BA_REL_ "GenSigVBitResp" BU_SG_REL_ FSCM_HS SG_ 1001 DistRollCntAvgDrvn 1;
BA_REL_ "GenSigVBitResp" BU_SG_REL_ BCM_HS SG_ 1001 DistRollCntAvgDrvn 1;
BA_REL_ "GenSigSuprvResp" BU_SG_REL_ BCM_HS SG_ 1001 DistRollCntAvgDrvn 1;
BA_REL_ "GenSigTimeoutMsg" BU_SG_REL_ BCM_HS SG_ 1001 DistRollCntAvgDrvn 1001;
BA_REL_ "GenSigTimeoutTime" BU_SG_REL_ BCM_HS SG_ 1001 DistRollCntAvgDrvn 250;
BA_REL_ "GenSigVBitResp" BU_SG_REL_ BCM_HS SG_ 1001 DistRollCntAvgDrvn 1;
BA_REL_ "GenSigSuprvResp" BU_SG_REL_ BCM_HS SG_ 1001 DistRollCntAvgDrvn 1;
BA_REL_ "GenSigTimeoutMsg" BU_SG_REL_ BCM_HS SG_ 1001 DistRollCntAvgDrvn 1001;
BA_REL_ "GenSigTimeoutTime" BU_SG_REL_ BCM_HS SG_ 1001 DistRollCntAvgDrvn 250;
BA_REL_ "GenSigSuprvResp" BU_SG_REL_ VICM2_HS SG_ 1001 VehSpdAvgNDrvn 1;
BA_REL_ "GenSigTimeoutMsg" BU_SG_REL_ VICM2_HS SG_ 1001 VehSpdAvgNDrvn 1001;
BA_REL_ "GenSigTimeoutTime" BU_SG_REL_ VICM2_HS SG_ 1001 VehSpdAvgNDrvn 250;
BA_REL_ "GenSigSuprvResp" BU_SG_REL_ HMIM_HS SG_ 1001 VehSpdAvgNDrvn 1;
BA_REL_ "GenSigTimeoutMsg" BU_SG_REL_ HMIM_HS SG_ 1001 VehSpdAvgNDrvn 1001;
BA_REL_ "GenSigTimeoutTime" BU_SG_REL_ HMIM_HS SG_ 1001 VehSpdAvgNDrvn 250;
BA_REL_ "GenSigSuprvResp" BU_SG_REL_ VICM_HS SG_ 1001 VehSpdAvgNDrvn 1;
BA_REL_ "GenSigTimeoutMsg" BU_SG_REL_ VICM_HS SG_ 1001 VehSpdAvgNDrvn 1001;
BA_REL_ "GenSigTimeoutTime" BU_SG_REL_ VICM_HS SG_ 1001 VehSpdAvgNDrvn 250;
BA_REL_ "GenSigVBitResp" BU_SG_REL_ APPS_HS SG_ 1001 VehSpdAvgNDrvn 1;
BA_REL_ "GenSigSuprvResp" BU_SG_REL_ APPS_HS SG_ 1001 VehSpdAvgNDrvn 1;
BA_REL_ "GenSigTimeoutMsg" BU_SG_REL_ APPS_HS SG_ 1001 VehSpdAvgNDrvn 1001;
BA_REL_ "GenSigTimeoutTime" BU_SG_REL_ APPS_HS SG_ 1001 VehSpdAvgNDrvn 250;
BA_REL_ "GenSigSuprvResp" BU_SG_REL_ TCCM_HS SG_ 1001 VehSpdAvgNDrvn 1;
BA_REL_ "GenSigTimeoutMsg" BU_SG_REL_ TCCM_HS SG_ 1001 VehSpdAvgNDrvn 1001;
BA_REL_ "GenSigTimeoutTime" BU_SG_REL_ TCCM_HS SG_ 1001 VehSpdAvgNDrvn 250;
BA_REL_ "GenSigSuprvResp" BU_SG_REL_ EPB_HS SG_ 1001 VehSpdAvgNDrvn 1;
BA_REL_ "GenSigTimeoutMsg" BU_SG_REL_ EPB_HS SG_ 1001 VehSpdAvgNDrvn 1001;
BA_REL_ "GenSigTimeoutTime" BU_SG_REL_ EPB_HS SG_ 1001 VehSpdAvgNDrvn 250;
BA_REL_ "GenSigSuprvResp" BU_SG_REL_ AHL_AFL_HS SG_ 1001 VehSpdAvgNDrvn 1;
BA_REL_ "GenSigTimeoutMsg" BU_SG_REL_ AHL_AFL_HS SG_ 1001 VehSpdAvgNDrvn 1001;
BA_REL_ "GenSigTimeoutTime" BU_SG_REL_ AHL_AFL_HS SG_ 1001 VehSpdAvgNDrvn 250;
BA_REL_ "GenSigVBitResp" BU_SG_REL_ BCM_HS SG_ 1001 VehSpdAvgNDrvn 1;
BA_REL_ "GenSigSuprvResp" BU_SG_REL_ BCM_HS SG_ 1001 VehSpdAvgNDrvn 1;
BA_REL_ "GenSigTimeoutMsg" BU_SG_REL_ BCM_HS SG_ 1001 VehSpdAvgNDrvn 1001;
BA_REL_ "GenSigTimeoutTime" BU_SG_REL_ BCM_HS SG_ 1001 VehSpdAvgNDrvn 250;
BA_REL_ "GenSigVBitResp" BU_SG_REL_ BCM_HS SG_ 1001 VehSpdAvgNDrvn 1;
BA_REL_ "GenSigSuprvResp" BU_SG_REL_ BCM_HS SG_ 1001 VehSpdAvgNDrvn 1;
BA_REL_ "GenSigTimeoutMsg" BU_SG_REL_ BCM_HS SG_ 1001 VehSpdAvgNDrvn 1001;
BA_REL_ "GenSigTimeoutTime" BU_SG_REL_ BCM_HS SG_ 1001 VehSpdAvgNDrvn 250;
BA_REL_ "GenSigSuprvResp" BU_SG_REL_ ACC_HS SG_ 1001 VehSpdAvgNDrvn 1;
BA_REL_ "GenSigTimeoutMsg" BU_SG_REL_ ACC_HS SG_ 1001 VehSpdAvgNDrvn 1001;
BA_REL_ "GenSigTimeoutTime" BU_SG_REL_ ACC_HS SG_ 1001 VehSpdAvgNDrvn 250;
BA_REL_ "GenSigVBitResp" BU_SG_REL_ PTO_HS SG_ 1001 VehSpdAvgNDrvn 1;
BA_REL_ "GenSigSuprvResp" BU_SG_REL_ PTO_HS SG_ 1001 VehSpdAvgNDrvn 1;
BA_REL_ "GenSigTimeoutMsg" BU_SG_REL_ PTO_HS SG_ 1001 VehSpdAvgNDrvn 1001;
BA_REL_ "GenSigTimeoutTime" BU_SG_REL_ PTO_HS SG_ 1001 VehSpdAvgNDrvn 250;
BA_REL_ "GenSigSuprvResp" BU_SG_REL_ PFAF_HS SG_ 1001 VehSpdAvgDrvn 1;
BA_REL_ "GenSigTimeoutMsg" BU_SG_REL_ PFAF_HS SG_ 1001 VehSpdAvgDrvn 1001;
BA_REL_ "GenSigTimeoutTime" BU_SG_REL_ PFAF_HS SG_ 1001 VehSpdAvgDrvn 250;
BA_REL_ "GenSigSuprvResp" BU_SG_REL_ EBCM_OBD_HS SG_ 1001 VehSpdAvgDrvn 1;
BA_REL_ "GenSigTimeoutMsg" BU_SG_REL_ EBCM_OBD_HS SG_ 1001 VehSpdAvgDrvn 1001;
BA_REL_ "GenSigTimeoutTime" BU_SG_REL_ EBCM_OBD_HS SG_ 1001 VehSpdAvgDrvn 250;
BA_REL_ "GenSigSuprvResp" BU_SG_REL_ EBCM_HS SG_ 1001 VehSpdAvgDrvn 1;
BA_REL_ "GenSigTimeoutMsg" BU_SG_REL_ EBCM_HS SG_ 1001 VehSpdAvgDrvn 1001;
BA_REL_ "GenSigTimeoutTime" BU_SG_REL_ EBCM_HS SG_ 1001 VehSpdAvgDrvn 250;
BA_REL_ "GenSigSuprvResp" BU_SG_REL_ VES_HS SG_ 1001 VehSpdAvgDrvn 1;
BA_REL_ "GenSigTimeoutMsg" BU_SG_REL_ VES_HS SG_ 1001 VehSpdAvgDrvn 1001;
BA_REL_ "GenSigTimeoutTime" BU_SG_REL_ VES_HS SG_ 1001 VehSpdAvgDrvn 250;
BA_REL_ "GenSigSuprvResp" BU_SG_REL_ EPS_HS SG_ 1001 VehSpdAvgDrvn 1;
BA_REL_ "GenSigTimeoutMsg" BU_SG_REL_ EPS_HS SG_ 1001 VehSpdAvgDrvn 1001;
BA_REL_ "GenSigTimeoutTime" BU_SG_REL_ EPS_HS SG_ 1001 VehSpdAvgDrvn 250;
BA_REL_ "GenSigSuprvResp" BU_SG_REL_ VICM_HS SG_ 1001 VehSpdAvgDrvn 1;
BA_REL_ "GenSigTimeoutMsg" BU_SG_REL_ VICM_HS SG_ 1001 VehSpdAvgDrvn 1001;
BA_REL_ "GenSigTimeoutTime" BU_SG_REL_ VICM_HS SG_ 1001 VehSpdAvgDrvn 250;
BA_REL_ "GenSigVBitResp" BU_SG_REL_ APPS_HS SG_ 1001 VehSpdAvgDrvn 1;
BA_REL_ "GenSigSuprvResp" BU_SG_REL_ APPS_HS SG_ 1001 VehSpdAvgDrvn 1;
BA_REL_ "GenSigTimeoutMsg" BU_SG_REL_ APPS_HS SG_ 1001 VehSpdAvgDrvn 1001;
BA_REL_ "GenSigTimeoutTime" BU_SG_REL_ APPS_HS SG_ 1001 VehSpdAvgDrvn 250;
BA_REL_ "GenSigSuprvResp" BU_SG_REL_ TCCM_HS SG_ 1001 VehSpdAvgDrvn 1;
BA_REL_ "GenSigTimeoutMsg" BU_SG_REL_ TCCM_HS SG_ 1001 VehSpdAvgDrvn 1001;
BA_REL_ "GenSigTimeoutTime" BU_SG_REL_ TCCM_HS SG_ 1001 VehSpdAvgDrvn 250;
BA_REL_ "GenSigSuprvResp" BU_SG_REL_ VICM2_HS SG_ 1001 VehSpdAvgDrvn 1;
BA_REL_ "GenSigTimeoutMsg" BU_SG_REL_ VICM2_HS SG_ 1001 VehSpdAvgDrvn 1001;
BA_REL_ "GenSigTimeoutTime" BU_SG_REL_ VICM2_HS SG_ 1001 VehSpdAvgDrvn 250;
BA_REL_ "GenSigVBitResp" BU_SG_REL_ FSCM_ITBC_HS SG_ 1001 VehSpdAvgDrvn 1;
BA_REL_ "GenSigSuprvResp" BU_SG_REL_ FSCM_HS SG_ 1001 VehSpdAvgDrvn 1;
BA_REL_ "GenSigTimeoutMsg" BU_SG_REL_ FSCM_HS SG_ 1001 VehSpdAvgDrvn 1001;
BA_REL_ "GenSigTimeoutTime" BU_SG_REL_ FSCM_HS SG_ 1001 VehSpdAvgDrvn 250;
BA_REL_ "GenSigVBitResp" BU_SG_REL_ FSCM_HS SG_ 1001 VehSpdAvgDrvn 1;
BA_REL_ "GenSigSuprvResp" BU_SG_REL_ EPB_HS SG_ 1001 VehSpdAvgDrvn 1;
BA_REL_ "GenSigTimeoutMsg" BU_SG_REL_ EPB_HS SG_ 1001 VehSpdAvgDrvn 1001;
BA_REL_ "GenSigTimeoutTime" BU_SG_REL_ EPB_HS SG_ 1001 VehSpdAvgDrvn 250;
BA_REL_ "GenSigSuprvResp" BU_SG_REL_ ICCM_OBD_HS SG_ 1001 VehSpdAvgDrvn 1;
BA_REL_ "GenSigTimeoutMsg" BU_SG_REL_ ICCM_OBD_HS SG_ 1001 VehSpdAvgDrvn 1001;
BA_REL_ "GenSigTimeoutTime" BU_SG_REL_ ICCM_OBD_HS SG_ 1001 VehSpdAvgDrvn 250;
BA_REL_ "GenSigVBitResp" BU_SG_REL_ ICCM_OBD_HS SG_ 1001 VehSpdAvgDrvn 1;
BA_REL_ "GenSigSuprvResp" BU_SG_REL_ ICCM_HS SG_ 1001 VehSpdAvgDrvn 1;
BA_REL_ "GenSigTimeoutMsg" BU_SG_REL_ ICCM_HS SG_ 1001 VehSpdAvgDrvn 1001;
BA_REL_ "GenSigTimeoutTime" BU_SG_REL_ ICCM_HS SG_ 1001 VehSpdAvgDrvn 250;
BA_REL_ "GenSigVBitResp" BU_SG_REL_ ICCM_HS SG_ 1001 VehSpdAvgDrvn 1;
BA_REL_ "GenSigSuprvResp" BU_SG_REL_ ACC_HS SG_ 1001 VehSpdAvgDrvn 1;
BA_REL_ "GenSigTimeoutMsg" BU_SG_REL_ ACC_HS SG_ 1001 VehSpdAvgDrvn 1001;
BA_REL_ "GenSigTimeoutTime" BU_SG_REL_ ACC_HS SG_ 1001 VehSpdAvgDrvn 250;
BA_REL_ "GenSigVBitResp" BU_SG_REL_ BCM_HS SG_ 1001 VehSpdAvgDrvn 1;
BA_REL_ "GenSigSuprvResp" BU_SG_REL_ BCM_HS SG_ 1001 VehSpdAvgDrvn 1;
BA_REL_ "GenSigTimeoutMsg" BU_SG_REL_ BCM_HS SG_ 1001 VehSpdAvgDrvn 1001;
BA_REL_ "GenSigTimeoutTime" BU_SG_REL_ BCM_HS SG_ 1001 VehSpdAvgDrvn 250;
BA_REL_ "GenSigVBitResp" BU_SG_REL_ BCM_HS SG_ 1001 VehSpdAvgDrvn 1;
BA_REL_ "GenSigSuprvResp" BU_SG_REL_ BCM_HS SG_ 1001 VehSpdAvgDrvn 1;
BA_REL_ "GenSigTimeoutMsg" BU_SG_REL_ BCM_HS SG_ 1001 VehSpdAvgDrvn 1001;
BA_REL_ "GenSigTimeoutTime" BU_SG_REL_ BCM_HS SG_ 1001 VehSpdAvgDrvn 250;
BA_REL_ "GenSigVBitResp" BU_SG_REL_ BCM_HS SG_ 1001 VehSpdAvgDrvn 1;
BA_REL_ "GenSigSuprvResp" BU_SG_REL_ BCM_HS SG_ 1001 VehSpdAvgDrvn 1;
BA_REL_ "GenSigTimeoutMsg" BU_SG_REL_ BCM_HS SG_ 1001 VehSpdAvgDrvn 1001;
BA_REL_ "GenSigTimeoutTime" BU_SG_REL_ BCM_HS SG_ 1001 VehSpdAvgDrvn 250;
BA_REL_ "GenSigSuprvRespSubValue" BU_SG_REL_ BCM_HS SG_ 804 VehHghtStatV 1;
BA_REL_ "GenSigSuprvResp" BU_SG_REL_ BCM_HS SG_ 804 VehHghtStatV 2;
BA_REL_ "GenSigTimeoutMsg" BU_SG_REL_ BCM_HS SG_ 804 VehHghtStatV 804;
BA_REL_ "GenSigTimeoutTime" BU_SG_REL_ BCM_HS SG_ 804 VehHghtStatV 1250;
BA_REL_ "GenSigVBitResp" BU_SG_REL_ BCM_HS SG_ 804 VehHghtStat 1;
BA_REL_ "GenSigSuprvResp" BU_SG_REL_ BCM_HS SG_ 804 VehHghtStat 1;
BA_REL_ "GenSigTimeoutMsg" BU_SG_REL_ BCM_HS SG_ 804 VehHghtStat 804;
BA_REL_ "GenSigTimeoutTime" BU_SG_REL_ BCM_HS SG_ 804 VehHghtStat 1250;
BA_REL_ "GenSigSuprvResp" BU_SG_REL_ BCM_HS SG_ 804 SrvLevSysIO 1;
BA_REL_ "GenSigTimeoutMsg" BU_SG_REL_ BCM_HS SG_ 804 SrvLevSysIO 804;
BA_REL_ "GenSigTimeoutTime" BU_SG_REL_ BCM_HS SG_ 804 SrvLevSysIO 1250;
BA_REL_ "GenSigSuprvResp" BU_SG_REL_ BCM_HS SG_ 804 LevSysVehTopSpdLim 1;
BA_REL_ "GenSigTimeoutMsg" BU_SG_REL_ BCM_HS SG_ 804 LevSysVehTopSpdLim 804;
BA_REL_ "GenSigTimeoutTime" BU_SG_REL_ BCM_HS SG_ 804 LevSysVehTopSpdLim 1250;
BA_REL_ "GenSigSuprvResp" BU_SG_REL_ VICM_HS SG_ 842 WhlRotDrctnlSRtNDrvn 1;
BA_REL_ "GenSigTimeoutMsg" BU_SG_REL_ VICM_HS SG_ 842 WhlRotDrctnlSRtNDrvn 842;
BA_REL_ "GenSigTimeoutTime" BU_SG_REL_ VICM_HS SG_ 842 WhlRotDrctnlSRtNDrvn 250;
BA_REL_ "GenSigSuprvResp" BU_SG_REL_ EOCM_F_HS SG_ 842 WhlRotDrctnlSRtNDrvn 1;
BA_REL_ "GenSigTimeoutMsg" BU_SG_REL_ EOCM_F_HS SG_ 842 WhlRotDrctnlSRtNDrvn 842;
BA_REL_ "GenSigTimeoutTime" BU_SG_REL_ EOCM_F_HS SG_ 842 WhlRotDrctnlSRtNDrvn 160;
BA_REL_ "GenSigSuprvResp" BU_SG_REL_ VICM_HS SG_ 842 WhlRotDrctnlStLfNDrvn 1;
BA_REL_ "GenSigTimeoutMsg" BU_SG_REL_ VICM_HS SG_ 842 WhlRotDrctnlStLfNDrvn 842;
BA_REL_ "GenSigTimeoutTime" BU_SG_REL_ VICM_HS SG_ 842 WhlRotDrctnlStLfNDrvn 250;
BA_REL_ "GenSigSuprvResp" BU_SG_REL_ EOCM_F_HS SG_ 842 WhlRotDrctnlStLfNDrvn 1;
BA_REL_ "GenSigTimeoutMsg" BU_SG_REL_ EOCM_F_HS SG_ 842 WhlRotDrctnlStLfNDrvn 842;
BA_REL_ "GenSigTimeoutTime" BU_SG_REL_ EOCM_F_HS SG_ 842 WhlRotDrctnlStLfNDrvn 160;
BA_REL_ "GenSigSuprvResp" BU_SG_REL_ TCCM_HS SG_ 842 WhlGrndVlctyRtNnDrvn 1;
BA_REL_ "GenSigTimeoutMsg" BU_SG_REL_ TCCM_HS SG_ 842 WhlGrndVlctyRtNnDrvn 842;
BA_REL_ "GenSigTimeoutTime" BU_SG_REL_ TCCM_HS SG_ 842 WhlGrndVlctyRtNnDrvn 250;
BA_REL_ "GenSigVBitResp" BU_SG_REL_ APPS_HS SG_ 842 WhlGrndVlctyRtNnDrvn 1;
BA_REL_ "GenSigSuprvResp" BU_SG_REL_ APPS_HS SG_ 842 WhlGrndVlctyRtNnDrvn 1;
BA_REL_ "GenSigTimeoutMsg" BU_SG_REL_ APPS_HS SG_ 842 WhlGrndVlctyRtNnDrvn 842;
BA_REL_ "GenSigTimeoutTime" BU_SG_REL_ APPS_HS SG_ 842 WhlGrndVlctyRtNnDrvn 250;
BA_REL_ "GenSigSuprvResp" BU_SG_REL_ EOCM_F_HS SG_ 842 WhlGrndVlctyRtNnDrvn 1;
BA_REL_ "GenSigTimeoutMsg" BU_SG_REL_ EOCM_F_HS SG_ 842 WhlGrndVlctyRtNnDrvn 842;
BA_REL_ "GenSigTimeoutTime" BU_SG_REL_ EOCM_F_HS SG_ 842 WhlGrndVlctyRtNnDrvn 160;
BA_REL_ "GenSigSuprvResp" BU_SG_REL_ ACC_HS SG_ 842 WhlGrndVlctyRtNnDrvn 1;
BA_REL_ "GenSigTimeoutMsg" BU_SG_REL_ ACC_HS SG_ 842 WhlGrndVlctyRtNnDrvn 842;
BA_REL_ "GenSigTimeoutTime" BU_SG_REL_ ACC_HS SG_ 842 WhlGrndVlctyRtNnDrvn 250;
BA_REL_ "GenSigVBitResp" BU_SG_REL_ BCM_HS SG_ 842 WhlGrndVlctyRtNnDrvn 1;
BA_REL_ "GenSigSuprvResp" BU_SG_REL_ BCM_HS SG_ 842 WhlGrndVlctyRtNnDrvn 1;
BA_REL_ "GenSigTimeoutMsg" BU_SG_REL_ BCM_HS SG_ 842 WhlGrndVlctyRtNnDrvn 842;
BA_REL_ "GenSigTimeoutTime" BU_SG_REL_ BCM_HS SG_ 842 WhlGrndVlctyRtNnDrvn 250;
BA_REL_ "GenSigSuprvResp" BU_SG_REL_ EPB_HS SG_ 842 WhlGrndVlctyRtNnDrvn 1;
BA_REL_ "GenSigTimeoutMsg" BU_SG_REL_ EPB_HS SG_ 842 WhlGrndVlctyRtNnDrvn 842;
BA_REL_ "GenSigTimeoutTime" BU_SG_REL_ EPB_HS SG_ 842 WhlGrndVlctyRtNnDrvn 125;
BA_REL_ "GenSigSuprvResp" BU_SG_REL_ VES_HS SG_ 842 WhlGrndVlctyRtNnDrvn 1;
BA_REL_ "GenSigTimeoutMsg" BU_SG_REL_ VES_HS SG_ 842 WhlGrndVlctyRtNnDrvn 842;
BA_REL_ "GenSigTimeoutTime" BU_SG_REL_ VES_HS SG_ 842 WhlGrndVlctyRtNnDrvn 250;
BA_REL_ "GenSigSuprvResp" BU_SG_REL_ EPS_HS SG_ 842 WhlGrndVlctyRtNnDrvn 1;
BA_REL_ "GenSigTimeoutMsg" BU_SG_REL_ EPS_HS SG_ 842 WhlGrndVlctyRtNnDrvn 842;
BA_REL_ "GenSigTimeoutTime" BU_SG_REL_ EPS_HS SG_ 842 WhlGrndVlctyRtNnDrvn 250;
BA_REL_ "GenSigSuprvResp" BU_SG_REL_ TCCM_HS SG_ 842 WhlGrndVlctyLftNnDrvn 1;
BA_REL_ "GenSigTimeoutMsg" BU_SG_REL_ TCCM_HS SG_ 842 WhlGrndVlctyLftNnDrvn 842;
BA_REL_ "GenSigTimeoutTime" BU_SG_REL_ TCCM_HS SG_ 842 WhlGrndVlctyLftNnDrvn 250;
BA_REL_ "GenSigVBitResp" BU_SG_REL_ APPS_HS SG_ 842 WhlGrndVlctyLftNnDrvn 1;
BA_REL_ "GenSigSuprvResp" BU_SG_REL_ APPS_HS SG_ 842 WhlGrndVlctyLftNnDrvn 1;
BA_REL_ "GenSigTimeoutMsg" BU_SG_REL_ APPS_HS SG_ 842 WhlGrndVlctyLftNnDrvn 842;
BA_REL_ "GenSigTimeoutTime" BU_SG_REL_ APPS_HS SG_ 842 WhlGrndVlctyLftNnDrvn 250;
BA_REL_ "GenSigSuprvResp" BU_SG_REL_ EOCM_F_HS SG_ 842 WhlGrndVlctyLftNnDrvn 1;
BA_REL_ "GenSigTimeoutMsg" BU_SG_REL_ EOCM_F_HS SG_ 842 WhlGrndVlctyLftNnDrvn 842;
BA_REL_ "GenSigTimeoutTime" BU_SG_REL_ EOCM_F_HS SG_ 842 WhlGrndVlctyLftNnDrvn 160;
BA_REL_ "GenSigVBitResp" BU_SG_REL_ BCM_HS SG_ 842 WhlGrndVlctyLftNnDrvn 1;
BA_REL_ "GenSigSuprvResp" BU_SG_REL_ BCM_HS SG_ 842 WhlGrndVlctyLftNnDrvn 1;
BA_REL_ "GenSigTimeoutMsg" BU_SG_REL_ BCM_HS SG_ 842 WhlGrndVlctyLftNnDrvn 842;
BA_REL_ "GenSigTimeoutTime" BU_SG_REL_ BCM_HS SG_ 842 WhlGrndVlctyLftNnDrvn 250;
BA_REL_ "GenSigVBitResp" BU_SG_REL_ RDCM_HS SG_ 842 WhlGrndVlctyLftNnDrvn 1;
BA_REL_ "GenSigSuprvResp" BU_SG_REL_ RDCM_HS SG_ 842 WhlGrndVlctyLftNnDrvn 1;
BA_REL_ "GenSigTimeoutMsg" BU_SG_REL_ RDCM_HS SG_ 842 WhlGrndVlctyLftNnDrvn 842;
BA_REL_ "GenSigTimeoutTime" BU_SG_REL_ RDCM_HS SG_ 842 WhlGrndVlctyLftNnDrvn 250;
BA_REL_ "GenSigSuprvResp" BU_SG_REL_ ACC_HS SG_ 842 WhlGrndVlctyLftNnDrvn 1;
BA_REL_ "GenSigTimeoutMsg" BU_SG_REL_ ACC_HS SG_ 842 WhlGrndVlctyLftNnDrvn 842;
BA_REL_ "GenSigTimeoutTime" BU_SG_REL_ ACC_HS SG_ 842 WhlGrndVlctyLftNnDrvn 250;
BA_REL_ "GenSigSuprvResp" BU_SG_REL_ EPB_HS SG_ 842 WhlGrndVlctyLftNnDrvn 1;
BA_REL_ "GenSigTimeoutMsg" BU_SG_REL_ EPB_HS SG_ 842 WhlGrndVlctyLftNnDrvn 842;
BA_REL_ "GenSigTimeoutTime" BU_SG_REL_ EPB_HS SG_ 842 WhlGrndVlctyLftNnDrvn 125;
BA_REL_ "GenSigSuprvResp" BU_SG_REL_ ECM_HS SG_ 491 ExhPrsRgVlv2Pos 1;
BA_REL_ "GenSigTimeoutMsg" BU_SG_REL_ ECM_HS SG_ 491 ExhPrsRgVlv2Pos 491;
BA_REL_ "GenSigTimeoutTime" BU_SG_REL_ ECM_HS SG_ 491 ExhPrsRgVlv2Pos 31;
BA_REL_ "GenSigSuprvResp" BU_SG_REL_ PCM_HS SG_ 491 ExhPrsRgVlvPosV 1;
BA_REL_ "GenSigTimeoutMsg" BU_SG_REL_ PCM_HS SG_ 491 ExhPrsRgVlvPosV 491;
BA_REL_ "GenSigTimeoutTime" BU_SG_REL_ PCM_HS SG_ 491 ExhPrsRgVlvPosV 30;
BA_REL_ "GenSigSuprvResp" BU_SG_REL_ ECM_HS SG_ 491 ExhPrsRgVlvPosV 1;
BA_REL_ "GenSigTimeoutMsg" BU_SG_REL_ ECM_HS SG_ 491 ExhPrsRgVlvPosV 491;
BA_REL_ "GenSigTimeoutTime" BU_SG_REL_ ECM_HS SG_ 491 ExhPrsRgVlvPosV 30;
BA_REL_ "GenSigSuprvResp" BU_SG_REL_ PCM_HS SG_ 491 ExhPrsRgVlvPos 1;
BA_REL_ "GenSigTimeoutMsg" BU_SG_REL_ PCM_HS SG_ 491 ExhPrsRgVlvPos 491;
BA_REL_ "GenSigTimeoutTime" BU_SG_REL_ PCM_HS SG_ 491 ExhPrsRgVlvPos 30;
BA_REL_ "GenSigSuprvResp" BU_SG_REL_ ECM_HS SG_ 491 ExhPrsRgVlvPos 1;
BA_REL_ "GenSigTimeoutMsg" BU_SG_REL_ ECM_HS SG_ 491 ExhPrsRgVlvPos 491;
BA_REL_ "GenSigTimeoutTime" BU_SG_REL_ ECM_HS SG_ 491 ExhPrsRgVlvPos 30;
BA_REL_ "GenSigSuprvResp" BU_SG_REL_ VCM_HS SG_ 491 FuelSysEstPressDlvrd 1;
BA_REL_ "GenSigTimeoutMsg" BU_SG_REL_ VCM_HS SG_ 491 FuelSysEstPressDlvrd 491;
BA_REL_ "GenSigTimeoutTime" BU_SG_REL_ VCM_HS SG_ 491 FuelSysEstPressDlvrd 1250;
BA_REL_ "GenSigSuprvResp" BU_SG_REL_ PCM_HS SG_ 491 FuelSysEstPressDlvrd 1;
BA_REL_ "GenSigTimeoutMsg" BU_SG_REL_ PCM_HS SG_ 491 FuelSysEstPressDlvrd 491;
BA_REL_ "GenSigTimeoutTime" BU_SG_REL_ PCM_HS SG_ 491 FuelSysEstPressDlvrd 30;
BA_REL_ "GenSigSuprvResp" BU_SG_REL_ ECM_HS SG_ 491 FuelSysEstPressDlvrd 1;
BA_REL_ "GenSigTimeoutMsg" BU_SG_REL_ ECM_HS SG_ 491 FuelSysEstPressDlvrd 491;
BA_REL_ "GenSigTimeoutTime" BU_SG_REL_ ECM_HS SG_ 491 FuelSysEstPressDlvrd 30;
BA_REL_ "GenSigSuprvResp" BU_SG_REL_ PCM_HS SG_ 491 FuelSysEstPressDlvrdV 1;
BA_REL_ "GenSigTimeoutMsg" BU_SG_REL_ PCM_HS SG_ 491 FuelSysEstPressDlvrdV 491;
BA_REL_ "GenSigTimeoutTime" BU_SG_REL_ PCM_HS SG_ 491 FuelSysEstPressDlvrdV 30;
BA_REL_ "GenSigSuprvResp" BU_SG_REL_ ECM_HS SG_ 491 FuelSysEstPressDlvrdV 1;
BA_REL_ "GenSigTimeoutMsg" BU_SG_REL_ ECM_HS SG_ 491 FuelSysEstPressDlvrdV 491;
BA_REL_ "GenSigTimeoutTime" BU_SG_REL_ ECM_HS SG_ 491 FuelSysEstPressDlvrdV 30;
BA_REL_ "GenSigSuprvResp" BU_SG_REL_ VICM_HS SG_ 1019 FuelAlcoholComp 1;
BA_REL_ "GenSigTimeoutMsg" BU_SG_REL_ VICM_HS SG_ 1019 FuelAlcoholComp 1019;
BA_REL_ "GenSigTimeoutTime" BU_SG_REL_ VICM_HS SG_ 1019 FuelAlcoholComp 625;
BA_REL_ "GenSigVBitResp" BU_SG_REL_ ICCM_OBD_HS SG_ 1019 FuelAlcoholComp 1;
BA_REL_ "GenSigVBitResp" BU_SG_REL_ ICCM_HS SG_ 1019 FuelAlcoholComp 1;
BA_REL_ "GenSigVBitResp" BU_SG_REL_ FSCM_ITBC_HS SG_ 1019 FuelAlcoholComp 1;
BA_REL_ "GenSigVBitResp" BU_SG_REL_ FSCM_HS SG_ 1019 FuelAlcoholComp 1;
VAL_ 499 PTShftPtrnOvrdAct 1 "true" 0 "false" ;
VAL_ 499 PFTrnsTUDSecSwSt 3 "Illegal Up/Down Switch State Active" 2 "Decrement Switch Active" 1 "Increment Switch Active" 0 "No Activation" ;
VAL_ 499 TrnsPFShftPattSw4Act 1 "true" 0 "false" ;
VAL_ 499 TrnsPFShftPattSw3Act 1 "true" 0 "false" ;
VAL_ 499 TrnsPFShftPattSw2Act 1 "true" 0 "false" ;
VAL_ 499 TrnsPFShftPattSw1Act 1 "true" 0 "false" ;
VAL_ 499 PFTrnsTUDSwSt 3 "Illegal Up/Down Switch State Active" 2 "Decrement Switch Active" 1 "Increment Switch Active" 0 "No Activation" ;
VAL_ 499 PFTrnsTUDEnSwSt 3 "Illegal Enable Switch State" 2 "Electronic Range Select Enable Sw" 1 "Driver Shift Control Enable Switch" 0 "No Activation" ;
VAL_ 499 OvrdrvDsblReqd 1 "true" 0 "false" ;
VAL_ 1282 TireTrdTmpStat 0 "No Action (unknown)" 1 "Frozen" 2 "Cold" 3 "Warm" 4 "Hot" 5 "Overheated" ;
VAL_ 1282 AllNodesVNA_502 1 "Activate Virtual Network" 0 "No Activation" ;
VAL_ 1282 A3ERRAlrmReq 0 "No Action" 1 "Set Alarm" 2 "Cancel Alarm" ;
VAL_ 1921 DTCI_CurrentStatus_781 1 "true" 0 "false" ;
VAL_ 1921 DTCI_WrnIndRqdSt_781 1 "true" 0 "false" ;
VAL_ 1921 DTCIUnused7_781 1 "true" 0 "false" ;
VAL_ 1921 DTCIUnused6_781 1 "true" 0 "false" ;
VAL_ 1921 DTCIUnused5_781 1 "true" 0 "false" ;
VAL_ 1921 DTCIUnused4_781 1 "true" 0 "false" ;
VAL_ 1921 DTCIUnused3_781 1 "true" 0 "false" ;
VAL_ 1921 DTCIUnused2_781 1 "true" 0 "false" ;
VAL_ 1921 DTCIUnused1_781 1 "true" 0 "false" ;
VAL_ 1921 DTCI_TstNPsdPwrUpSt_781 1 "true" 0 "false" ;
VAL_ 1921 DTCI_TstNPsdCdClrdSt_781 1 "true" 0 "false" ;
VAL_ 1921 DTCI_TstFldPwrUpSt_781 1 "true" 0 "false" ;
VAL_ 1921 DTCI_TstFldCdClrdStat_781 1 "true" 0 "false" ;
VAL_ 1921 DTCI_HistStat_781 1 "true" 0 "false" ;
VAL_ 1921 DTCI_DTCTriggered_781 1 "true" 0 "false" ;
VAL_ 1921 DTCI_DTCFaultType_781 3 "Type C" 2 "Type B" 1 "Type A" 0 "Not Supported" ;
VAL_ 1921 DTCI_CodeSupported_781 1 "true" 0 "false" ;
VAL_ 1920 DTCI_CurrentStatus_780 1 "true" 0 "false" ;
VAL_ 1920 DTCI_WrnIndRqdSt_780 1 "true" 0 "false" ;
VAL_ 1920 DTCIUnused7_780 1 "true" 0 "false" ;
VAL_ 1920 DTCIUnused6_780 1 "true" 0 "false" ;
VAL_ 1920 DTCIUnused5_780 1 "true" 0 "false" ;
VAL_ 1920 DTCIUnused4_780 1 "true" 0 "false" ;
VAL_ 1920 DTCIUnused3_780 1 "true" 0 "false" ;
VAL_ 1920 DTCIUnused2_780 1 "true" 0 "false" ;
VAL_ 1920 DTCIUnused1_780 1 "true" 0 "false" ;
VAL_ 1920 DTCI_TstNPsdPwrUpSt_780 1 "true" 0 "false" ;
VAL_ 1920 DTCI_TstNPsdCdClrdSt_780 1 "true" 0 "false" ;
VAL_ 1920 DTCI_TstFldPwrUpSt_780 1 "true" 0 "false" ;
VAL_ 1920 DTCI_TstFldCdClrdStat_780 1 "true" 0 "false" ;
VAL_ 1920 DTCI_HistStat_780 1 "true" 0 "false" ;
VAL_ 1920 DTCI_DTCTriggered_780 1 "true" 0 "false" ;
VAL_ 1920 DTCI_DTCFaultType_780 3 "Type C" 2 "Type B" 1 "Type A" 0 "Not Supported" ;
VAL_ 1920 DTCI_CodeSupported_780 1 "true" 0 "false" ;
VAL_ 495 MassAirFloV 1 "Invalid" 0 "Valid" ;
VAL_ 1914 DTCI_DTCFaultType_77A 3 "Type C" 2 "Type B" 1 "Type A" 0 "Not Supported" ;
VAL_ 1914 DTCI_CodeSupported_77A 1 "true" 0 "false" ;
VAL_ 1914 DTCI_CurrentStatus_77A 1 "true" 0 "false" ;
VAL_ 1914 DTCI_TstNPsdCdClrdSt_77A 1 "true" 0 "false" ;
VAL_ 1914 DTCI_TstFldCdClrdStat_77A 1 "true" 0 "false" ;
VAL_ 1914 DTCI_HistStat_77A 1 "true" 0 "false" ;
VAL_ 1914 DTCI_TstNPsdPwrUpSt_77A 1 "true" 0 "false" ;
VAL_ 1914 DTCI_TstFldPwrUpSt_77A 1 "true" 0 "false" ;
VAL_ 1914 DTCI_WrnIndRqdSt_77A 1 "true" 0 "false" ;
VAL_ 1914 DTCI_DTCTriggered_77A 1 "true" 0 "false" ;
VAL_ 1914 DTCIUnused7_77A 1 "true" 0 "false" ;
VAL_ 1914 DTCIUnused6_77A 1 "true" 0 "false" ;
VAL_ 1914 DTCIUnused5_77A 1 "true" 0 "false" ;
VAL_ 1914 DTCIUnused4_77A 1 "true" 0 "false" ;
VAL_ 1914 DTCIUnused3_77A 1 "true" 0 "false" ;
VAL_ 1914 DTCIUnused2_77A 1 "true" 0 "false" ;
VAL_ 1914 DTCIUnused1_77A 1 "true" 0 "false" ;
VAL_ 1911 DTCI_DTCFaultType_777 3 "Type C" 2 "Type B" 1 "Type A" 0 "Not Supported" ;
VAL_ 1911 DTCI_CodeSupported_777 1 "true" 0 "false" ;
VAL_ 1911 DTCI_CurrentStatus_777 1 "true" 0 "false" ;
VAL_ 1911 DTCI_TstNPsdCdClrdSt_777 1 "true" 0 "false" ;
VAL_ 1911 DTCI_TstFldCdClrdStat_777 1 "true" 0 "false" ;
VAL_ 1911 DTCI_HistStat_777 1 "true" 0 "false" ;
VAL_ 1911 DTCI_TstNPsdPwrUpSt_777 1 "true" 0 "false" ;
VAL_ 1911 DTCI_TstFldPwrUpSt_777 1 "true" 0 "false" ;
VAL_ 1911 DTCI_WrnIndRqdSt_777 1 "true" 0 "false" ;
VAL_ 1911 DTCI_DTCTriggered_777 1 "true" 0 "false" ;
VAL_ 1911 DTCIUnused7_777 1 "true" 0 "false" ;
VAL_ 1911 DTCIUnused6_777 1 "true" 0 "false" ;
VAL_ 1911 DTCIUnused5_777 1 "true" 0 "false" ;
VAL_ 1911 DTCIUnused4_777 1 "true" 0 "false" ;
VAL_ 1911 DTCIUnused3_777 1 "true" 0 "false" ;
VAL_ 1911 DTCIUnused2_777 1 "true" 0 "false" ;
VAL_ 1911 DTCIUnused1_777 1 "true" 0 "false" ;
VAL_ 1906 DTCI_DTCFaultType_772 3 "Type C" 2 "Type B" 1 "Type A" 0 "Not Supported" ;
VAL_ 1906 DTCI_CodeSupported_772 1 "true" 0 "false" ;
VAL_ 1906 DTCI_CurrentStatus_772 1 "true" 0 "false" ;
VAL_ 1906 DTCI_TstNPsdCdClrdSt_772 1 "true" 0 "false" ;
VAL_ 1906 DTCI_TstFldCdClrdStat_772 1 "true" 0 "false" ;
VAL_ 1906 DTCI_HistStat_772 1 "true" 0 "false" ;
VAL_ 1906 DTCI_TstNPsdPwrUpSt_772 1 "true" 0 "false" ;
VAL_ 1906 DTCI_TstFldPwrUpSt_772 1 "true" 0 "false" ;
VAL_ 1906 DTCI_WrnIndRqdSt_772 1 "true" 0 "false" ;
VAL_ 1906 DTCI_DTCTriggered_772 1 "true" 0 "false" ;
VAL_ 1906 DTCIUnused7_772 1 "true" 0 "false" ;
VAL_ 1906 DTCIUnused6_772 1 "true" 0 "false" ;
VAL_ 1906 DTCIUnused5_772 1 "true" 0 "false" ;
VAL_ 1906 DTCIUnused4_772 1 "true" 0 "false" ;
VAL_ 1906 DTCIUnused3_772 1 "true" 0 "false" ;
VAL_ 1906 DTCIUnused2_772 1 "true" 0 "false" ;
VAL_ 1906 DTCIUnused1_772 1 "true" 0 "false" ;
VAL_ 1907 DTCI_DTCFaultType_773 3 "Type C" 2 "Type B" 1 "Type A" 0 "Not Supported" ;
VAL_ 1907 DTCI_CodeSupported_773 1 "true" 0 "false" ;
VAL_ 1907 DTCI_CurrentStatus_773 1 "true" 0 "false" ;
VAL_ 1907 DTCI_TstNPsdCdClrdSt_773 1 "true" 0 "false" ;
VAL_ 1907 DTCI_TstFldCdClrdStat_773 1 "true" 0 "false" ;
VAL_ 1907 DTCI_HistStat_773 1 "true" 0 "false" ;
VAL_ 1907 DTCI_TstNPsdPwrUpSt_773 1 "true" 0 "false" ;
VAL_ 1907 DTCI_TstFldPwrUpSt_773 1 "true" 0 "false" ;
VAL_ 1907 DTCI_WrnIndRqdSt_773 1 "true" 0 "false" ;
VAL_ 1907 DTCI_DTCTriggered_773 1 "true" 0 "false" ;
VAL_ 1907 DTCIUnused7_773 1 "true" 0 "false" ;
VAL_ 1907 DTCIUnused6_773 1 "true" 0 "false" ;
VAL_ 1907 DTCIUnused5_773 1 "true" 0 "false" ;
VAL_ 1907 DTCIUnused4_773 1 "true" 0 "false" ;
VAL_ 1907 DTCIUnused3_773 1 "true" 0 "false" ;
VAL_ 1907 DTCIUnused2_773 1 "true" 0 "false" ;
VAL_ 1907 DTCIUnused1_773 1 "true" 0 "false" ;
VAL_ 1915 DTCI_DTCFaultType_77B 3 "Type C" 2 "Type B" 1 "Type A" 0 "Not Supported" ;
VAL_ 1915 DTCI_CodeSupported_77B 1 "true" 0 "false" ;
VAL_ 1915 DTCI_CurrentStatus_77B 1 "true" 0 "false" ;
VAL_ 1915 DTCI_TstNPsdCdClrdSt_77B 1 "true" 0 "false" ;
VAL_ 1915 DTCI_TstFldCdClrdStat_77B 1 "true" 0 "false" ;
VAL_ 1915 DTCI_HistStat_77B 1 "true" 0 "false" ;
VAL_ 1915 DTCI_TstNPsdPwrUpSt_77B 1 "true" 0 "false" ;
VAL_ 1915 DTCI_TstFldPwrUpSt_77B 1 "true" 0 "false" ;
VAL_ 1915 DTCI_WrnIndRqdSt_77B 1 "true" 0 "false" ;
VAL_ 1915 DTCI_DTCTriggered_77B 1 "true" 0 "false" ;
VAL_ 1915 DTCIUnused7_77B 1 "true" 0 "false" ;
VAL_ 1915 DTCIUnused6_77B 1 "true" 0 "false" ;
VAL_ 1915 DTCIUnused5_77B 1 "true" 0 "false" ;
VAL_ 1915 DTCIUnused4_77B 1 "true" 0 "false" ;
VAL_ 1915 DTCIUnused3_77B 1 "true" 0 "false" ;
VAL_ 1915 DTCIUnused2_77B 1 "true" 0 "false" ;
VAL_ 1915 DTCIUnused1_77B 1 "true" 0 "false" ;
VAL_ 880 FOAI_VehAhdIndRq 0 "No Alert" 1 "Alert Level 1" 2 "Alert Level 2" 3 "Alert Level 3" ;
VAL_ 880 FOAI_AlrtWrnIndRq 0 "No Alert" 1 "Alert Level 1" 2 "Alert Level 2" 3 "Alert Level 3" ;
VAL_ 880 FOAI_AlrtChmIhbRq 0 "Allow Chime" 1 "Inhibit Chime" ;
VAL_ 880 FwdClnAlrtPr 1 "true" 0 "false" ;
VAL_ 880 ACCUnavlbleDTWthrIO 1 "true" 0 "false" ;
VAL_ 880 ACCAct370 1 "true" 0 "false" ;
VAL_ 880 DrvThrtlOvrdIO 1 "true" 0 "false" ;
VAL_ 880 ServAdpCrsCtrlIndOn 1 "true" 0 "false" ;
VAL_ 880 ACCHdwayStngIO 1 "true" 0 "false" ;
VAL_ 880 ACCHdwyStg 7 "Headway Setting 7" 6 "Headway Setting 6" 5 "Headway Setting 5" 4 "Headway Setting 4" 3 "Headway Setting 3" 2 "Headway Setting 2" 1 "Headway Setting 1" 0 "Minimum Headway Setting" ;
VAL_ 880 ACCSnsClnRqdIO 1 "true" 0 "false" ;
VAL_ 880 ACCTmpUnavlbleIO 1 "true" 0 "false" ;
VAL_ 880 ACCDrvrSeltdSpdIO 1 "true" 0 "false" ;
VAL_ 894 RtLwBmFld 1 "true" 0 "false" ;
VAL_ 894 LftLwBmFld 1 "true" 0 "false" ;
VAL_ 894 AdvFrntLghtSysIndRq 7 "Indication 7" 6 "Indication 6" 5 "Indication 5" 4 "Indication 4" 3 "Indication 3" 2 "Indication 2" 1 "Indication 1" 0 "No Indication" ;
VAL_ 894 HdLtLvlFlrIO 1 "true" 0 "false" ;
VAL_ 298 SpdLmtrSttngTyp 1 "Auto" 0 "Manual" ;
VAL_ 298 TCSysDisSwAtv 1 "true" 0 "false" ;
VAL_ 298 AutoMdSpdLmtCnfrmd 1 "true" 0 "false" ;
VAL_ 298 ChmAct 1 "true" 0 "false" ;
VAL_ 298 DDAjrSwAtvM 0 "Don't Use Data" 1 "Use Data" ;
VAL_ 298 CrshAlrtDrvrSlctdType 0 "Chime" 1 "Seat" ;
VAL_ 298 PsSbltAtcV 1 "Invalid" 0 "Valid" ;
VAL_ 298 PsSbltAtc 1 "true" 0 "false" ;
VAL_ 298 TrlrBrkDsplyAct 1 "true" 0 "false" ;
VAL_ 298 RdSpdCatType 3 "all speed categories 0 - 50 km/h" 2 "all speed categories 51-80 km/h" 1 "all speed categories 81-130 km/h" 0 "all speed categories > 130 km/h" ;
VAL_ 298 LnCat 3 "Four Or More Lanes" 2 "Two Or Three Lanes" 1 "One lane" 0 "no info available" ;
VAL_ 298 FncRdClass 7 "COLLECTOR" 6 "ALLEY" 5 "ARTERIAL" 4 "HIGHWAY" 3 "PED-MALL" 2 "FREEWAY" 1 "SFREEWAY" 0 "LOCAL (Residential Road)" ;
VAL_ 298 SprtLnRd 1 "true" 0 "false" ;
VAL_ 298 CntrldAccRd 1 "true" 0 "false" ;
VAL_ 298 BldUpArDet 1 "true" 0 "false" ;
VAL_ 298 MpDataAvlbl 1 "true" 0 "false" ;
VAL_ 298 SusCustStngReq 7 "Auto" 6 "Performance Mode 6" 5 "Performance Mode 5" 4 "Performance Mode 4" 3 "Performance Mode 3" 2 "Performance Mode 2" 1 "Performance Mode 1" 0 "No Action" ;
VAL_ 298 StrCustStngReq 7 "Auto" 6 "Performance Mode 6" 5 "Performance Mode 5" 4 "Performance Mode 4" 3 "Performance Mode 3" 2 "Performance Mode 2" 1 "Performance Mode 1" 0 "No Action" ;
VAL_ 298 RstrCustFctrDef 1 "Restore Defaults" 0 "No Action" ;
VAL_ 298 DrvlnCustStngReq 7 "Auto" 6 "Performance Mode 6" 5 "Performance Mode 5" 4 "Performance Mode 4" 3 "Performance Mode 3" 2 "Performance Mode 2" 1 "Performance Mode 1" 0 "No Action" ;
VAL_ 298 ChmMstrVDA 1 "VirtualDeviceAvailable" 0 "VirtualDeviceUnavailable" ;
VAL_ 298 IPCVDA 1 "VirtualDeviceAvailable" 0 "VirtualDeviceUnavailable" ;
VAL_ 298 HeadUpDispVDA 1 "VirtualDeviceAvailable" 0 "VirtualDeviceUnavailable" ;
VAL_ 298 HapticSeatVDA 1 "VirtualDeviceAvailable" 0 "VirtualDeviceUnavailable" ;
VAL_ 298 RRDoorAjarSwAct 1 "true" 0 "false" ;
VAL_ 298 PDAjrSwAtv 1 "true" 0 "false" ;
VAL_ 298 DDAjrSwAtv 1 "true" 0 "false" ;
VAL_ 298 TrlrHWIntrfcVDA 1 "VirtualDeviceAvailable" 0 "VirtualDeviceUnavailable" ;
VAL_ 298 DrId 7 "Unknown" 6 "Driver #7" 5 "Driver #6" 4 "Driver #5" 3 "Driver #4" 2 "Driver #3" 1 "Driver #2" 0 "Driver #1" ;
VAL_ 298 EnrgMgtLdShdRq 4 "Load Shed Level 4" 3 "Load Shed Level 3" 2 "Load Shed Level 2" 1 "Load Shed Level 1" 0 "No Load Shedding" ;
VAL_ 298 DrSbltAtcV 1 "Invalid" 0 "Valid" ;
VAL_ 298 TrlrHtchSwAtv 1 "true" 0 "false" ;
VAL_ 298 TreInfMonSysRstReq 1 "true" 0 "false" ;
VAL_ 298 HUDActv 1 "true" 0 "false" ;
VAL_ 298 BatVltV 1 "Invalid" 0 "Valid" ;
VAL_ 298 RLDoorAjarSwAct 1 "true" 0 "false" ;
VAL_ 298 DrSbltAtc 1 "true" 0 "false" ;
VAL_ 1322 TireRRPrsV 1 "Invalid" 0 "Valid" ;
VAL_ 1322 TireRRPrsStat 5 "High" 4 "Low - Extended Mobility" 3 "Low" 2 "Low - Service Now" 1 "Nominal" 0 "Unknown" ;
VAL_ 1322 TireRFPrsV 1 "Invalid" 0 "Valid" ;
VAL_ 1322 TireRFPrsStat 5 "High" 4 "Low - Extended Mobility" 3 "Low" 2 "Low - Service Now" 1 "Nominal" 0 "Unknown" ;
VAL_ 1322 TireLRPrsV 1 "Invalid" 0 "Valid" ;
VAL_ 1322 TireLRPrsStat 5 "High" 4 "Low - Extended Mobility" 3 "Low" 2 "Low - Service Now" 1 "Nominal" 0 "Unknown" ;
VAL_ 1322 TireLFPrsV 1 "Invalid" 0 "Valid" ;
VAL_ 1322 TireLFPrsStat 5 "High" 4 "Low - Extended Mobility" 3 "Low" 2 "Low - Service Now" 1 "Nominal" 0 "Unknown" ;
VAL_ 288 VehOdoV 1 "Invalid" 0 "Valid" ;
VAL_ 485 StrWhAngGrdV 0 "Valid" 1 "Invalid" ;
VAL_ 485 StrWhAngGrdMsk 0 "Don't Use Data" 1 "Use Data" ;
VAL_ 485 StrWhAngMsk 0 "Don't Use Data" 1 "Use Data" ;
VAL_ 485 StrWhlAngSenTyp 0 "Type 1" 1 "Type 2" 2 "Type 3" 3 "Type 4" ;
VAL_ 485 StrWhlAngSenCalStat 2 "Calibrated" 1 "Estimated" 0 "Unknown" ;
VAL_ 485 StrWhAngV 1 "Invalid" 0 "Valid" ;
VAL_ 1001 DistRollCntAvgDrvnSrc 1 "Wheel Speed" 0 "Transmission Output Speed" ;
VAL_ 1001 VehSpdAvgDrvnSrc 1 "Wheel Speed" 0 "Transmission Output Speed" ;
VAL_ 1001 DstRolCntAvgNonDrvnV 1 "Invalid" 0 "Valid" ;
VAL_ 1001 DstRolCntAvNDrRstOc 1 "true" 0 "false" ;
VAL_ 1001 DistRollCntAvgDrvnV 1 "Invalid" 0 "Valid" ;
VAL_ 1001 DstRolCntAvgDrnRstOc 1 "true" 0 "false" ;
VAL_ 1001 VehSpdAvgNDrvnV 1 "Invalid" 0 "Valid" ;
VAL_ 1001 VehSpdAvgDrvnV 1 "Invalid" 0 "Valid" ;
VAL_ 804 CompOvrhtIndOn 1 "true" 0 "false" ;
VAL_ 804 VehHghtStatV 1 "Invalid" 0 "Valid" ;
VAL_ 804 VehHghtStat 4 "Maximum Height" 3 "Kneeling Height" 2 "Aerodynamic Height" 1 "Normal Design Ride Height" 0 "Unknown" ;
VAL_ 804 SrvLevSysIO 1 "true" 0 "false" ;
VAL_ 804 VehOvrLdIndOn 1 "true" 0 "false" ;
VAL_ 842 WhlRotDrctnlSRtNDrvn 0 "Unknown" 1 "Forward" 2 "Reverse" 3 "Not Supported" 4 "Failed" 5 "Reserved 1" 6 "Reserved 2" 7 "Reserved 3" ;
VAL_ 842 WhlRotDrctnlStLfNDrvn 0 "Unknown" 1 "Forward" 2 "Reverse" 3 "Not Supported" 4 "Failed" 5 "Reserved 1" 6 "Reserved 2" 7 "Reserved 3" ;
VAL_ 842 WhlGrndVlctyRtNnDrvnV 1 "Invalid" 0 "Valid" ;
VAL_ 842 WhlGrndVlctyLftNnDrvnV 1 "Invalid" 0 "Valid" ;
VAL_ 1241 FSERDTC_SysDes 15 "U3-Network Codes Reserved" 14 "U2-Network Codes Reserved" 13 "U1-Network Codes MFG Controlled" 12 "U0-Network Codes SAE Controlled" 11 "B3-Body Codes Reserved" 10 "B2-Body Codes Reserved" 9 "B1-Body Codes MFG Controlled" 8 "B0-Body Codes SAE Controlled" 7 "C3-Chassis Codes Reserved" 6 "C2-Chassis Codes Reserved" 5 "C1-Chassis Codes MFG Controlled" 4 "C0-Chassis Codes SAE Controlled" 3 "P3-Powertrain Codes Reserved" 2 "P2-Powertrain Codes Reserved" 1 "P1-Powertrain Codes MFG Controlled" 0 "P0-Powertrain Codes SAE Controlled" ;
VAL_ 1241 FuelSysEmsRldMlfAtv 1 "true" 0 "false" ;
VAL_ 491 ExhPrsRgVlv2Pos 0 "Open" 1 "Closed" ;
VAL_ 491 ExhPrsRgVlv2PosV 1 "Invalid" 0 "Valid" ;
VAL_ 491 ExhPrsRgVlvPosV 1 "Invalid" 0 "Valid" ;
VAL_ 491 ExhPrsRgVlvPos 1 "Closed" 0 "Open" ;
VAL_ 491 FuelSysEstPressDlvrdV 1 "Invalid" 0 "Valid" ;
VAL_ 1019 FuelAlchlCompAdptnPrg 1 "true" 0 "false" ;
VAL_ 1019 FuelLvlEmnsRelStat 0 "Valid" 1 "Invalid" ;
VAL_ 1019 EmnsRelFuelLvlLw 1 "true" 0 "false" ;
VAL_ 1019 EngFuelCntlState 2 "Stoichiometric Closed Loop" 1 "Non-Stoichiometric Closed Loop" 0 "Open Loop" ;
VAL_ 1019 FuelAlcoholCompV 1 "Invalid" 0 "Valid" ;
SIG_GROUP_ 1282 Alrm3ExtRngReq 1 : A3ERRAlrmTime A3ERRAlrmReq;
SIG_GROUP_ 1921 DTCInfo_781 1 : DTCI_CurrentStatus_781 DTCI_WrnIndRqdSt_781 DTCIUnused7_781 DTCIUnused6_781 DTCIUnused5_781 DTCIUnused4_781 DTCIUnused3_781 DTCIUnused2_781 DTCIUnused1_781 DTCI_TstNPsdPwrUpSt_781 DTCI_TstNPsdCdClrdSt_781 DTCI_TstFldPwrUpSt_781 DTCI_TstFldCdClrdStat_781 DTCI_HistStat_781 DTCI_DTCTriggered_781 DTCI_DTCSource_781 DTCI_DTCNumber_781 DTCI_DTCFaultType_781 DTCI_DTCFailType_781 DTCI_CodeSupported_781;
SIG_GROUP_ 1920 DTCInfo_780 1 : DTCI_CurrentStatus_780 DTCI_WrnIndRqdSt_780 DTCIUnused7_780 DTCIUnused6_780 DTCIUnused5_780 DTCIUnused4_780 DTCIUnused3_780 DTCIUnused2_780 DTCIUnused1_780 DTCI_TstNPsdPwrUpSt_780 DTCI_TstNPsdCdClrdSt_780 DTCI_TstFldPwrUpSt_780 DTCI_TstFldCdClrdStat_780 DTCI_HistStat_780 DTCI_DTCTriggered_780 DTCI_DTCSource_780 DTCI_DTCNumber_780 DTCI_DTCFaultType_780 DTCI_DTCFailType_780 DTCI_CodeSupported_780;
SIG_GROUP_ 1914 DTCInfo_77A 1 : DTCI_DTCFaultType_77A DTCI_CodeSupported_77A DTCI_CurrentStatus_77A DTCI_TstNPsdCdClrdSt_77A DTCI_TstFldCdClrdStat_77A DTCI_HistStat_77A DTCI_TstNPsdPwrUpSt_77A DTCI_TstFldPwrUpSt_77A DTCI_WrnIndRqdSt_77A DTCI_DTCFailType_77A DTCI_DTCNumber_77A DTCI_DTCSource_77A DTCI_DTCTriggered_77A DTCIUnused7_77A DTCIUnused6_77A DTCIUnused5_77A DTCIUnused4_77A DTCIUnused3_77A DTCIUnused2_77A DTCIUnused1_77A;
SIG_GROUP_ 1911 DTCInfo_777 1 : DTCI_DTCFaultType_777 DTCI_CodeSupported_777 DTCI_CurrentStatus_777 DTCI_TstNPsdCdClrdSt_777 DTCI_TstFldCdClrdStat_777 DTCI_HistStat_777 DTCI_TstNPsdPwrUpSt_777 DTCI_TstFldPwrUpSt_777 DTCI_WrnIndRqdSt_777 DTCI_DTCFailType_777 DTCI_DTCNumber_777 DTCI_DTCSource_777 DTCI_DTCTriggered_777 DTCIUnused7_777 DTCIUnused6_777 DTCIUnused5_777 DTCIUnused4_777 DTCIUnused3_777 DTCIUnused2_777 DTCIUnused1_777;
SIG_GROUP_ 1906 DTCInfo_772 1 : DTCI_DTCFaultType_772 DTCI_CodeSupported_772 DTCI_CurrentStatus_772 DTCI_TstNPsdCdClrdSt_772 DTCI_TstFldCdClrdStat_772 DTCI_HistStat_772 DTCI_TstNPsdPwrUpSt_772 DTCI_TstFldPwrUpSt_772 DTCI_WrnIndRqdSt_772 DTCI_DTCFailType_772 DTCI_DTCNumber_772 DTCI_DTCSource_772 DTCI_DTCTriggered_772 DTCIUnused7_772 DTCIUnused6_772 DTCIUnused5_772 DTCIUnused4_772 DTCIUnused3_772 DTCIUnused2_772 DTCIUnused1_772;
SIG_GROUP_ 1907 DTCInfo_773 1 : DTCI_DTCFaultType_773 DTCI_CodeSupported_773 DTCI_CurrentStatus_773 DTCI_TstNPsdCdClrdSt_773 DTCI_TstFldCdClrdStat_773 DTCI_HistStat_773 DTCI_TstNPsdPwrUpSt_773 DTCI_TstFldPwrUpSt_773 DTCI_WrnIndRqdSt_773 DTCI_DTCFailType_773 DTCI_DTCNumber_773 DTCI_DTCSource_773 DTCI_DTCTriggered_773 DTCIUnused7_773 DTCIUnused6_773 DTCIUnused5_773 DTCIUnused4_773 DTCIUnused3_773 DTCIUnused2_773 DTCIUnused1_773;
SIG_GROUP_ 1915 DTCInfo_77B 1 : DTCI_DTCFaultType_77B DTCI_CodeSupported_77B DTCI_CurrentStatus_77B DTCI_TstNPsdCdClrdSt_77B DTCI_TstFldCdClrdStat_77B DTCI_HistStat_77B DTCI_TstNPsdPwrUpSt_77B DTCI_TstFldPwrUpSt_77B DTCI_WrnIndRqdSt_77B DTCI_DTCFailType_77B DTCI_DTCNumber_77B DTCI_DTCSource_77B DTCI_DTCTriggered_77B DTCIUnused7_77B DTCIUnused6_77B DTCIUnused5_77B DTCIUnused4_77B DTCIUnused3_77B DTCIUnused2_77B DTCIUnused1_77B;
SIG_GROUP_ 880 FwdObjAlrtInd 1 : FOAI_VehAhdIndRq FOAI_AlrtWrnIndRq FOAI_AlrtChmIhbRq;
SIG_GROUP_ 1241 FuelSysEmnsRelDTC 1 : FSERDTC_CdNum FSERDTC_SysDes;
